VERSION ""

NS_ :

BS_:

BU_:

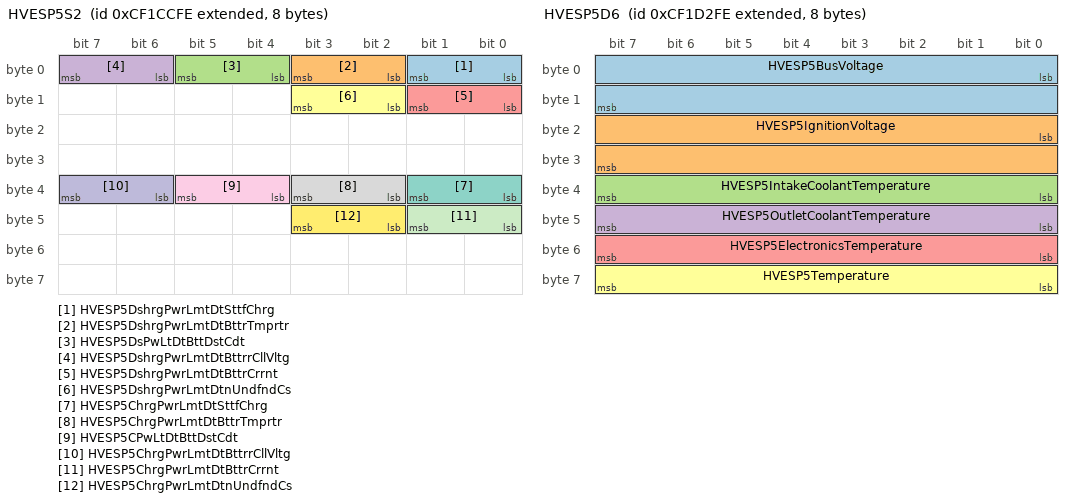
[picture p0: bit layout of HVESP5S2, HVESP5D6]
BO_ 2364656894 HVESP5S2: 8 Vector__XXX
 SG_ HVESP5DshrgPwrLmtDtSttfChrg : 0|2@1+ (1,0) [0|3] "" Vector__XXX
 SG_ HVESP5DshrgPwrLmtDtBttrTmprtr : 2|2@1+ (1,0) [0|3] "" Vector__XXX
 SG_ HVESP5DsPwLtDtBttDstCdt : 4|2@1+ (1,0) [0|3] "" Vector__XXX
 SG_ HVESP5DshrgPwrLmtDtBttrrCllVltg : 6|2@1+ (1,0) [0|3] "" Vector__XXX
 SG_ HVESP5DshrgPwrLmtDtBttrCrrnt : 8|2@1+ (1,0) [0|3] "" Vector__XXX
 SG_ HVESP5DshrgPwrLmtDtnUndfndCs : 10|2@1+ (1,0) [0|3] "" Vector__XXX
 SG_ HVESP5ChrgPwrLmtDtSttfChrg : 32|2@1+ (1,0) [0|3] "" Vector__XXX
 SG_ HVESP5ChrgPwrLmtDtBttrTmprtr : 34|2@1+ (1,0) [0|3] "" Vector__XXX
 SG_ HVESP5CPwLtDtBttDstCdt : 36|2@1+ (1,0) [0|3] "" Vector__XXX
 SG_ HVESP5ChrgPwrLmtDtBttrrCllVltg : 38|2@1+ (1,0) [0|3] "" Vector__XXX
 SG_ HVESP5ChrgPwrLmtDtBttrCrrnt : 40|2@1+ (1,0) [0|3] "" Vector__XXX
 SG_ HVESP5ChrgPwrLmtDtnUndfndCs : 42|2@1+ (1,0) [0|3] "" Vector__XXX

BO_ 2364657150 HVESP5D1: 8 Vector__XXX
 SG_ HVESP5AvailableDischargePower : 0|16@1+ (0.05,0) [0|3212.75] "kW" Vector__XXX
 SG_ HVESP5AvailableChargePower : 16|16@1+ (0.05,0) [0|3212.75] "kW" Vector__XXX
 SG_ HVESP5VoltageLevel : 32|16@1+ (0.05,0) [0|3212.75] "V" Vector__XXX
 SG_ HVESP5Current : 48|16@1+ (0.05,-1600) [-1600|1612.75] "A" Vector__XXX

BO_ 2364657406 HVESP5D2: 8 Vector__XXX
 SG_ HVESP5FastUpdateStateofCharge : 0|16@1+ (0.0015625,0) [0|100.3984375] "%" Vector__XXX
 SG_ HVESP5HighestCellVoltage : 16|16@1+ (0.001,0) [0|64.255] "V" Vector__XXX
 SG_ HVESP5LowestCellVoltage : 32|16@1+ (0.001,0) [0|64.255] "V" Vector__XXX
 SG_ HVESP5CllVltgDffrntlStts : 48|4@1+ (1,0) [0|15] "" Vector__XXX

BO_ 2364657662 HVESP5D3: 8 Vector__XXX
 SG_ HVESP5HighestCellTemperature : 0|16@1+ (0.03125,-273) [-273|1734.96875] "degC" Vector__XXX
 SG_ HVESP5LowestCellTemperature : 16|16@1+ (0.03125,-273) [-273|1734.96875] "degC" Vector__XXX
 SG_ HVESP5AverageCellTemperature : 32|16@1+ (0.03125,-273) [-273|1734.96875] "degC" Vector__XXX
 SG_ HVESP5CllTmprtrDffrntlStts : 48|2@1+ (1,0) [0|3] "" Vector__XXX

BO_ 2364657918 HVESP5D4: 8 Vector__XXX
 SG_ HVESP5DischargeCapacity : 0|16@1+ (0.01,0) [0|642.55] "Ah" Vector__XXX
 SG_ HVESP5ChargeCapacity : 16|16@1+ (0.01,0) [0|642.55] "Ah" Vector__XXX
 SG_ HVESP5CellBalancingCount : 32|16@1+ (1,0) [0|64255] "count" Vector__XXX

BO_ 2364658174 HVESP5D5: 8 Vector__XXX
 SG_ HVESP5DischargeCurrentLimit : 0|16@1+ (0.05,-1600) [-1600|1612.75] "A" Vector__XXX
 SG_ HVESP5ChargeCurrentLimit : 16|16@1+ (0.05,-1600) [-1600|1612.75] "A" Vector__XXX
 SG_ HVESP5LowestCellStateofCharge : 32|16@1+ (0.0015625,0) [0|100.3984375] "%" Vector__XXX
 SG_ HVESP5HighestCellStateofCharge : 48|16@1+ (0.0015625,0) [0|100.3984375] "%" Vector__XXX

BO_ 2364658430 HVESP5D6: 8 Vector__XXX
 SG_ HVESP5BusVoltage : 0|16@1+ (0.05,0) [0|3212.75] "V" Vector__XXX
 SG_ HVESP5IgnitionVoltage : 16|16@1+ (0.01,0) [0|642.55] "V" Vector__XXX
 SG_ HVESP5IntakeCoolantTemperature : 32|8@1+ (1,-40) [-40|210] "degC" Vector__XXX
 SG_ HVESP5OutletCoolantTemperature : 40|8@1+ (1,-40) [-40|210] "degC" Vector__XXX
 SG_ HVESP5ElectronicsTemperature : 48|8@1+ (1,-40) [-40|210] "degC" Vector__XXX
 SG_ HVESP5Temperature : 56|8@1+ (1,-40) [-40|210] "degC" Vector__XXX

BO_ 2364658686 HVESP5S1: 8 Vector__XXX
 SG_ HVESP5HghVltgBsPstvCnttrStt : 0|2@1+ (1,0) [0|3] "" Vector__XXX
 SG_ HVESP5HghVltgBsNgtvCnttrStt : 2|2@1+ (1,0) [0|3] "" Vector__XXX
 SG_ HVESP5HghVltgBsDsnntFrwrnng : 4|4@1+ (1,0) [0|15] "" Vector__XXX
 SG_ HVESP5HghVltgBsPrChrgRlStt : 8|2@1+ (1,0) [0|3] "" Vector__XXX
 SG_ HVESP5CntrfPkCnttrStt : 10|2@1+ (1,0) [0|3] "" Vector__XXX
 SG_ HVESP5HghVltgBsAtvIsltnTstStts : 12|4@1+ (1,0) [0|15] "" Vector__XXX
 SG_ HVESP5HghVltgBsPssvIsltnTstStts : 16|4@1+ (1,0) [0|15] "" Vector__XXX
 SG_ HVESP5HVILStatus : 20|2@1+ (1,0) [0|3] "" Vector__XXX
 SG_ HVESP5InertiaSwitchStatus : 22|2@1+ (1,0) [0|3] "" Vector__XXX
 SG_ HVESP5StateofChargeStatus : 24|4@1+ (1,0) [0|15] "" Vector__XXX
 SG_ HVESP5CellBalanceStatus : 28|2@1+ (1,0) [0|3] "" Vector__XXX
 SG_ HVESP5CellBalancingActive : 30|2@1+ (1,0) [0|3] "" Vector__XXX
 SG_ HVESP5InternalChargerStatus : 32|2@1+ (1,0) [0|3] "" Vector__XXX
 SG_ HVESP5HghVltgBsCnntnStts : 40|4@1+ (1,0) [0|15] "" Vector__XXX
 SG_ HVESP5OperationalStatus : 44|4@1+ (1,0) [0|15] "" Vector__XXX
 SG_ HVESP5Status1Counter : 52|4@1+ (1,0) [0|15] "" Vector__XXX
 SG_ HVESP5Status1CRC : 56|8@1+ (1,0) [0|255] "count" Vector__XXX

BO_ 2364658942 HVESP5D7: 8 Vector__XXX
 SG_ HVESP5DischargeEnergyCapacity : 0|24@1+ (0.001,0) [0|16449.535] "kWh" Vector__XXX
 SG_ HVESP5ChargeEnergyCapacity : 24|24@1+ (0.001,0) [0|16449.535] "kWh" Vector__XXX
 SG_ HVESP5MaximumChargeVoltageLimit : 48|16@1+ (0.05,0) [0|3212.75] "V" Vector__XXX

BO_ 2364659198 HVESP5MS1: 8 Vector__XXX
 SG_ HVESP5Module1OperationalStatus : 0|2@1+ (1,0) [0|3] "" Vector__XXX
 SG_ HVESP5Module2OperationalStatus : 2|2@1+ (1,0) [0|3] "" Vector__XXX
 SG_ HVESP5Module3OperationalStatus : 4|2@1+ (1,0) [0|3] "" Vector__XXX
 SG_ HVESP5Module4OperationalStatus : 6|2@1+ (1,0) [0|3] "" Vector__XXX
 SG_ HVESP5Module5OperationalStatus : 8|2@1+ (1,0) [0|3] "" Vector__XXX
 SG_ HVESP5Module6OperationalStatus : 10|2@1+ (1,0) [0|3] "" Vector__XXX
 SG_ HVESP5Module7OperationalStatus : 12|2@1+ (1,0) [0|3] "" Vector__XXX
 SG_ HVESP5Module8OperationalStatus : 14|2@1+ (1,0) [0|3] "" Vector__XXX
 SG_ HVESP5Module9OperationalStatus : 16|2@1+ (1,0) [0|3] "" Vector__XXX
 SG_ HVESP5Module10OperationalStatus : 18|2@1+ (1,0) [0|3] "" Vector__XXX
 SG_ HVESP5Module11OperationalStatus : 20|2@1+ (1,0) [0|3] "" Vector__XXX
 SG_ HVESP5Module12OperationalStatus : 22|2@1+ (1,0) [0|3] "" Vector__XXX
 SG_ HVESP5Module13OperationalStatus : 24|2@1+ (1,0) [0|3] "" Vector__XXX
 SG_ HVESP5Module14OperationalStatus : 26|2@1+ (1,0) [0|3] "" Vector__XXX
 SG_ HVESP5Module15OperationalStatus : 28|2@1+ (1,0) [0|3] "" Vector__XXX
 SG_ HVESP5Module16OperationalStatus : 30|2@1+ (1,0) [0|3] "" Vector__XXX
 SG_ HVESP5Module17OperationalStatus : 32|2@1+ (1,0) [0|3] "" Vector__XXX
 SG_ HVESP5Module18OperationalStatus : 34|2@1+ (1,0) [0|3] "" Vector__XXX
 SG_ HVESP5Module19OperationalStatus : 36|2@1+ (1,0) [0|3] "" Vector__XXX
 SG_ HVESP5Module20OperationalStatus : 38|2@1+ (1,0) [0|3] "" Vector__XXX
 SG_ HVESP5Module21OperationalStatus : 40|2@1+ (1,0) [0|3] "" Vector__XXX
 SG_ HVESP5Module22OperationalStatus : 42|2@1+ (1,0) [0|3] "" Vector__XXX
 SG_ HVESP5Module23OperationalStatus : 44|2@1+ (1,0) [0|3] "" Vector__XXX
 SG_ HVESP5Module24OperationalStatus : 46|2@1+ (1,0) [0|3] "" Vector__XXX
 SG_ HVESP5Module25OperationalStatus : 48|2@1+ (1,0) [0|3] "" Vector__XXX
 SG_ HVESP5Module26OperationalStatus : 50|2@1+ (1,0) [0|3] "" Vector__XXX
 SG_ HVESP5Module27OperationalStatus : 52|2@1+ (1,0) [0|3] "" Vector__XXX
 SG_ HVESP5Module28OperationalStatus : 54|2@1+ (1,0) [0|3] "" Vector__XXX
 SG_ HVESP5Module29OperationalStatus : 56|2@1+ (1,0) [0|3] "" Vector__XXX
 SG_ HVESP5Module30OperationalStatus : 58|2@1+ (1,0) [0|3] "" Vector__XXX
 SG_ HVESP5Module31OperationalStatus : 60|2@1+ (1,0) [0|3] "" Vector__XXX
 SG_ HVESP5Module32OperationalStatus : 62|2@1+ (1,0) [0|3] "" Vector__XXX

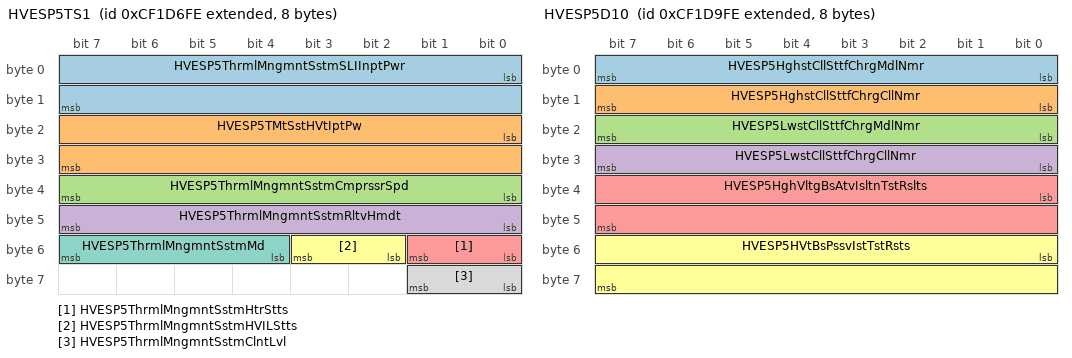
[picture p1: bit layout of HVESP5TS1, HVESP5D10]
BO_ 2364659454 HVESP5TS1: 8 Vector__XXX
 SG_ HVESP5ThrmlMngmntSstmSLIInptPwr : 0|16@1+ (0.5,0) [0|32127.5] "W" Vector__XXX
 SG_ HVESP5TMtSstHVtIptPw : 16|16@1+ (0.5,0) [0|32127.5] "W" Vector__XXX
 SG_ HVESP5ThrmlMngmntSstmCmprssrSpd : 32|8@1+ (32,0) [0|8000] "rpm" Vector__XXX
 SG_ HVESP5ThrmlMngmntSstmRltvHmdt : 40|8@1+ (0.4,0) [0|100] "%" Vector__XXX
 SG_ HVESP5ThrmlMngmntSstmHtrStts : 48|2@1+ (1,0) [0|3] "" Vector__XXX
 SG_ HVESP5ThrmlMngmntSstmHVILStts : 50|2@1+ (1,0) [0|3] "" Vector__XXX
 SG_ HVESP5ThrmlMngmntSstmMd : 52|4@1+ (1,0) [0|15] "" Vector__XXX
 SG_ HVESP5ThrmlMngmntSstmClntLvl : 56|2@1+ (1,0) [0|3] "" Vector__XXX

BO_ 2364659710 HVESP5D8: 8 Vector__XXX
 SG_ HVESP5HghstCllVltgMdlNmr : 0|8@1+ (1,0) [0|250] "count" Vector__XXX
 SG_ HVESP5HghstCllVltgCllNmr : 8|8@1+ (1,0) [0|250] "count" Vector__XXX
 SG_ HVESP5LwstCllVltgMdlNmr : 16|8@1+ (1,0) [0|250] "count" Vector__XXX
 SG_ HVESP5LwstCllVltgCllNmr : 24|8@1+ (1,0) [0|250] "count" Vector__XXX
 SG_ HVESP5AverageCellVoltage : 32|16@1+ (0.001,0) [0|64.255] "V" Vector__XXX

BO_ 2364659966 HVESP5D9: 8 Vector__XXX
 SG_ HVESP5HghstCllTmprtrMdlNmr : 0|8@1+ (1,0) [0|250] "count" Vector__XXX
 SG_ HVESP5HghstCllTmprtrCllNmr : 8|8@1+ (1,0) [0|250] "count" Vector__XXX
 SG_ HVESP5LwstCllTmprtrMdlNmr : 16|8@1+ (1,0) [0|250] "count" Vector__XXX
 SG_ HVESP5LwstCllTmprtrCllNmr : 24|8@1+ (1,0) [0|250] "count" Vector__XXX

BO_ 2364660222 HVESP5D10: 8 Vector__XXX
 SG_ HVESP5HghstCllSttfChrgMdlNmr : 0|8@1+ (1,0) [0|250] "count" Vector__XXX
 SG_ HVESP5HghstCllSttfChrgCllNmr : 8|8@1+ (1,0) [0|250] "count" Vector__XXX
 SG_ HVESP5LwstCllSttfChrgMdlNmr : 16|8@1+ (1,0) [0|250] "count" Vector__XXX
 SG_ HVESP5LwstCllSttfChrgCllNmr : 24|8@1+ (1,0) [0|250] "count" Vector__XXX
 SG_ HVESP5HghVltgBsAtvIsltnTstRslts : 32|16@1+ (0.1,0) [0|6425.5] "ohm/V" Vector__XXX
 SG_ HVESP5HVtBsPssvIstTstRsts : 48|16@1+ (0.1,0) [0|6425.5] "ohm/V" Vector__XXX

BO_ 2364660478 HVESP5D11: 8 Vector__XXX
 SG_ HVESP5BsVltgNgtvtChsssGrndVltg : 0|16@1+ (0.05,0) [0|3212.75] "V" Vector__XXX
 SG_ HVESP5VltgLvlNgtvtChsssGrndVltg : 16|16@1+ (0.05,0) [0|3212.75] "V" Vector__XXX
 SG_ HVESP5ActualChargeRate : 32|16@1+ (0.05,0) [0|3212.75] "kW" Vector__XXX

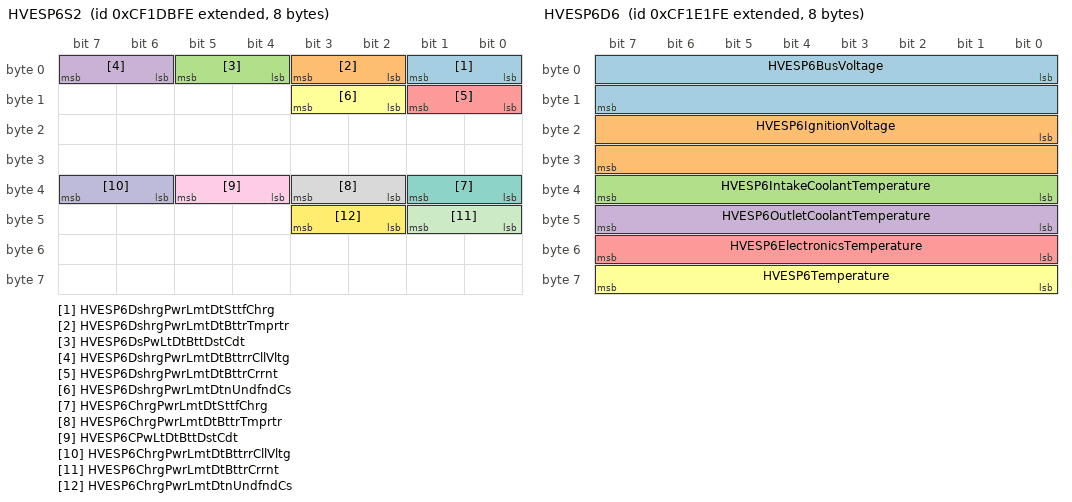
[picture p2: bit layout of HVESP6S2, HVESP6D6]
BO_ 2364660734 HVESP6S2: 8 Vector__XXX
 SG_ HVESP6DshrgPwrLmtDtSttfChrg : 0|2@1+ (1,0) [0|3] "" Vector__XXX
 SG_ HVESP6DshrgPwrLmtDtBttrTmprtr : 2|2@1+ (1,0) [0|3] "" Vector__XXX
 SG_ HVESP6DsPwLtDtBttDstCdt : 4|2@1+ (1,0) [0|3] "" Vector__XXX
 SG_ HVESP6DshrgPwrLmtDtBttrrCllVltg : 6|2@1+ (1,0) [0|3] "" Vector__XXX
 SG_ HVESP6DshrgPwrLmtDtBttrCrrnt : 8|2@1+ (1,0) [0|3] "" Vector__XXX
 SG_ HVESP6DshrgPwrLmtDtnUndfndCs : 10|2@1+ (1,0) [0|3] "" Vector__XXX
 SG_ HVESP6ChrgPwrLmtDtSttfChrg : 32|2@1+ (1,0) [0|3] "" Vector__XXX
 SG_ HVESP6ChrgPwrLmtDtBttrTmprtr : 34|2@1+ (1,0) [0|3] "" Vector__XXX
 SG_ HVESP6CPwLtDtBttDstCdt : 36|2@1+ (1,0) [0|3] "" Vector__XXX
 SG_ HVESP6ChrgPwrLmtDtBttrrCllVltg : 38|2@1+ (1,0) [0|3] "" Vector__XXX
 SG_ HVESP6ChrgPwrLmtDtBttrCrrnt : 40|2@1+ (1,0) [0|3] "" Vector__XXX
 SG_ HVESP6ChrgPwrLmtDtnUndfndCs : 42|2@1+ (1,0) [0|3] "" Vector__XXX

BO_ 2364660990 HVESP6D1: 8 Vector__XXX
 SG_ HVESP6AvailableDischargePower : 0|16@1+ (0.05,0) [0|3212.75] "kW" Vector__XXX
 SG_ HVESP6AvailableChargePower : 16|16@1+ (0.05,0) [0|3212.75] "kW" Vector__XXX
 SG_ HVESP6VoltageLevel : 32|16@1+ (0.05,0) [0|3212.75] "V" Vector__XXX
 SG_ HVESP6Current : 48|16@1+ (0.05,-1600) [-1600|1612.75] "A" Vector__XXX

BO_ 2364661246 HVESP6D2: 8 Vector__XXX
 SG_ HVESP6FastUpdateStateofCharge : 0|16@1+ (0.0015625,0) [0|100.3984375] "%" Vector__XXX
 SG_ HVESP6HighestCellVoltage : 16|16@1+ (0.001,0) [0|64.255] "V" Vector__XXX
 SG_ HVESP6LowestCellVoltage : 32|16@1+ (0.001,0) [0|64.255] "V" Vector__XXX
 SG_ HVESP6CllVltgDffrntlStts : 48|4@1+ (1,0) [0|15] "" Vector__XXX

BO_ 2364661502 HVESP6D3: 8 Vector__XXX
 SG_ HVESP6HighestCellTemperature : 0|16@1+ (0.03125,-273) [-273|1734.96875] "degC" Vector__XXX
 SG_ HVESP6LowestCellTemperature : 16|16@1+ (0.03125,-273) [-273|1734.96875] "degC" Vector__XXX
 SG_ HVESP6AverageCellTemperature : 32|16@1+ (0.03125,-273) [-273|1734.96875] "degC" Vector__XXX
 SG_ HVESP6CllTmprtrDffrntlStts : 48|2@1+ (1,0) [0|3] "" Vector__XXX

BO_ 2364661758 HVESP6D4: 8 Vector__XXX
 SG_ HVESP6DischargeCapacity : 0|16@1+ (0.01,0) [0|642.55] "Ah" Vector__XXX
 SG_ HVESP6ChargeCapacity : 16|16@1+ (0.01,0) [0|642.55] "Ah" Vector__XXX
 SG_ HVESP6CellBalancingCount : 32|16@1+ (1,0) [0|64255] "count" Vector__XXX

BO_ 2364662014 HVESP6D5: 8 Vector__XXX
 SG_ HVESP6DischargeCurrentLimit : 0|16@1+ (0.05,-1600) [-1600|1612.75] "A" Vector__XXX
 SG_ HVESP6ChargeCurrentLimit : 16|16@1+ (0.05,-1600) [-1600|1612.75] "A" Vector__XXX
 SG_ HVESP6LowestCellStateofCharge : 32|16@1+ (0.0015625,0) [0|100.3984375] "%" Vector__XXX
 SG_ HVESP6HighestCellStateofCharge : 48|16@1+ (0.0015625,0) [0|100.3984375] "%" Vector__XXX

BO_ 2364662270 HVESP6D6: 8 Vector__XXX
 SG_ HVESP6BusVoltage : 0|16@1+ (0.05,0) [0|3212.75] "V" Vector__XXX
 SG_ HVESP6IgnitionVoltage : 16|16@1+ (0.01,0) [0|642.55] "V" Vector__XXX
 SG_ HVESP6IntakeCoolantTemperature : 32|8@1+ (1,-40) [-40|210] "degC" Vector__XXX
 SG_ HVESP6OutletCoolantTemperature : 40|8@1+ (1,-40) [-40|210] "degC" Vector__XXX
 SG_ HVESP6ElectronicsTemperature : 48|8@1+ (1,-40) [-40|210] "degC" Vector__XXX
 SG_ HVESP6Temperature : 56|8@1+ (1,-40) [-40|210] "degC" Vector__XXX

BO_ 2364662526 HVESP6S1: 8 Vector__XXX
 SG_ HVESP6HghVltgBsPstvCnttrStt : 0|2@1+ (1,0) [0|3] "" Vector__XXX
 SG_ HVESP6HghVltgBsNgtvCnttrStt : 2|2@1+ (1,0) [0|3] "" Vector__XXX
 SG_ HVESP6HghVltgBsDsnntFrwrnng : 4|4@1+ (1,0) [0|15] "" Vector__XXX
 SG_ HVESP6HghVltgBsPrChrgRlStt : 8|2@1+ (1,0) [0|3] "" Vector__XXX
 SG_ HVESP6CntrfPkCnttrStt : 10|2@1+ (1,0) [0|3] "" Vector__XXX
 SG_ HVESP6HghVltgBsAtvIsltnTstStts : 12|4@1+ (1,0) [0|15] "" Vector__XXX
 SG_ HVESP6HghVltgBsPssvIsltnTstStts : 16|4@1+ (1,0) [0|15] "" Vector__XXX
 SG_ HVESP6HVILStatus : 20|2@1+ (1,0) [0|3] "" Vector__XXX
 SG_ HVESP6InertiaSwitchStatus : 22|2@1+ (1,0) [0|3] "" Vector__XXX
 SG_ HVESP6StateofChargeStatus : 24|4@1+ (1,0) [0|15] "" Vector__XXX
 SG_ HVESP6CellBalanceStatus : 28|2@1+ (1,0) [0|3] "" Vector__XXX
 SG_ HVESP6CellBalancingActive : 30|2@1+ (1,0) [0|3] "" Vector__XXX
 SG_ HVESP6InternalChargerStatus : 32|2@1+ (1,0) [0|3] "" Vector__XXX
 SG_ HVESP6HghVltgBsCnntnStts : 40|4@1+ (1,0) [0|15] "" Vector__XXX
 SG_ HVESP6OperationalStatus : 44|4@1+ (1,0) [0|15] "" Vector__XXX
 SG_ HVESP6Status1Counter : 52|4@1+ (1,0) [0|15] "" Vector__XXX
 SG_ HVESP6Status1CRC : 56|8@1+ (1,0) [0|255] "count" Vector__XXX

BO_ 2364662782 HVESP6D7: 8 Vector__XXX
 SG_ HVESP6DischargeEnergyCapacity : 0|24@1+ (0.001,0) [0|16449.535] "kWh" Vector__XXX
 SG_ HVESP6ChargeEnergyCapacity : 24|24@1+ (0.001,0) [0|16449.535] "kWh" Vector__XXX
 SG_ HVESP6MaximumChargeVoltageLimit : 48|16@1+ (0.05,0) [0|3212.75] "V" Vector__XXX

BO_ 2364663038 HVESP6MS1: 8 Vector__XXX
 SG_ HVESP6Module1OperationalStatus : 0|2@1+ (1,0) [0|3] "" Vector__XXX
 SG_ HVESP6Module2OperationalStatus : 2|2@1+ (1,0) [0|3] "" Vector__XXX
 SG_ HVESP6Module3OperationalStatus : 4|2@1+ (1,0) [0|3] "" Vector__XXX
 SG_ HVESP6Module4OperationalStatus : 6|2@1+ (1,0) [0|3] "" Vector__XXX
 SG_ HVESP6Module5OperationalStatus : 8|2@1+ (1,0) [0|3] "" Vector__XXX
 SG_ HVESP6Module6OperationalStatus : 10|2@1+ (1,0) [0|3] "" Vector__XXX
 SG_ HVESP6Module7OperationalStatus : 12|2@1+ (1,0) [0|3] "" Vector__XXX
 SG_ HVESP6Module8OperationalStatus : 14|2@1+ (1,0) [0|3] "" Vector__XXX
 SG_ HVESP6Module9OperationalStatus : 16|2@1+ (1,0) [0|3] "" Vector__XXX
 SG_ HVESP6Module10OperationalStatus : 18|2@1+ (1,0) [0|3] "" Vector__XXX
 SG_ HVESP6Module11OperationalStatus : 20|2@1+ (1,0) [0|3] "" Vector__XXX
 SG_ HVESP6Module12OperationalStatus : 22|2@1+ (1,0) [0|3] "" Vector__XXX
 SG_ HVESP6Module13OperationalStatus : 24|2@1+ (1,0) [0|3] "" Vector__XXX
 SG_ HVESP6Module14OperationalStatus : 26|2@1+ (1,0) [0|3] "" Vector__XXX
 SG_ HVESP6Module15OperationalStatus : 28|2@1+ (1,0) [0|3] "" Vector__XXX
 SG_ HVESP6Module16OperationalStatus : 30|2@1+ (1,0) [0|3] "" Vector__XXX
 SG_ HVESP6Module17OperationalStatus : 32|2@1+ (1,0) [0|3] "" Vector__XXX
 SG_ HVESP6Module18OperationalStatus : 34|2@1+ (1,0) [0|3] "" Vector__XXX
 SG_ HVESP6Module19OperationalStatus : 36|2@1+ (1,0) [0|3] "" Vector__XXX
 SG_ HVESP6Module20OperationalStatus : 38|2@1+ (1,0) [0|3] "" Vector__XXX
 SG_ HVESP6Module21OperationalStatus : 40|2@1+ (1,0) [0|3] "" Vector__XXX
 SG_ HVESP6Module22OperationalStatus : 42|2@1+ (1,0) [0|3] "" Vector__XXX
 SG_ HVESP6Module23OperationalStatus : 44|2@1+ (1,0) [0|3] "" Vector__XXX
 SG_ HVESP6Module24OperationalStatus : 46|2@1+ (1,0) [0|3] "" Vector__XXX
 SG_ HVESP6Module25OperationalStatus : 48|2@1+ (1,0) [0|3] "" Vector__XXX
 SG_ HVESP6Module26OperationalStatus : 50|2@1+ (1,0) [0|3] "" Vector__XXX
 SG_ HVESP6Module27OperationalStatus : 52|2@1+ (1,0) [0|3] "" Vector__XXX
 SG_ HVESP6Module28OperationalStatus : 54|2@1+ (1,0) [0|3] "" Vector__XXX
 SG_ HVESP6Module29OperationalStatus : 56|2@1+ (1,0) [0|3] "" Vector__XXX
 SG_ HVESP6Module30OperationalStatus : 58|2@1+ (1,0) [0|3] "" Vector__XXX
 SG_ HVESP6Module31OperationalStatus : 60|2@1+ (1,0) [0|3] "" Vector__XXX
 SG_ HVESP6Module32OperationalStatus : 62|2@1+ (1,0) [0|3] "" Vector__XXX

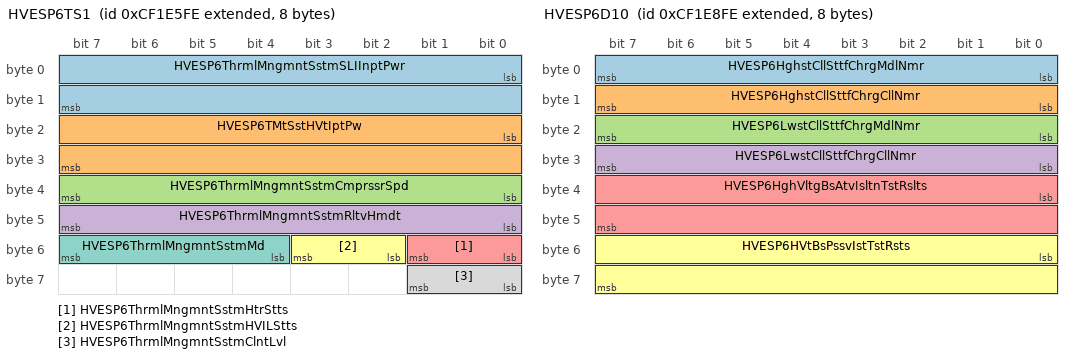
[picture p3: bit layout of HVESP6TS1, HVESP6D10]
BO_ 2364663294 HVESP6TS1: 8 Vector__XXX
 SG_ HVESP6ThrmlMngmntSstmSLIInptPwr : 0|16@1+ (0.5,0) [0|32127.5] "W" Vector__XXX
 SG_ HVESP6TMtSstHVtIptPw : 16|16@1+ (0.5,0) [0|32127.5] "W" Vector__XXX
 SG_ HVESP6ThrmlMngmntSstmCmprssrSpd : 32|8@1+ (32,0) [0|8000] "rpm" Vector__XXX
 SG_ HVESP6ThrmlMngmntSstmRltvHmdt : 40|8@1+ (0.4,0) [0|100] "%" Vector__XXX
 SG_ HVESP6ThrmlMngmntSstmHtrStts : 48|2@1+ (1,0) [0|3] "" Vector__XXX
 SG_ HVESP6ThrmlMngmntSstmHVILStts : 50|2@1+ (1,0) [0|3] "" Vector__XXX
 SG_ HVESP6ThrmlMngmntSstmMd : 52|4@1+ (1,0) [0|15] "" Vector__XXX
 SG_ HVESP6ThrmlMngmntSstmClntLvl : 56|2@1+ (1,0) [0|3] "" Vector__XXX

BO_ 2364663550 HVESP6D8: 8 Vector__XXX
 SG_ HVESP6HghstCllVltgMdlNmr : 0|8@1+ (1,0) [0|250] "count" Vector__XXX
 SG_ HVESP6HghstCllVltgCllNmr : 8|8@1+ (1,0) [0|250] "count" Vector__XXX
 SG_ HVESP6LwstCllVltgMdlNmr : 16|8@1+ (1,0) [0|250] "count" Vector__XXX
 SG_ HVESP6LwstCllVltgCllNmr : 24|8@1+ (1,0) [0|250] "count" Vector__XXX
 SG_ HVESP6AverageCellVoltage : 32|16@1+ (0.001,0) [0|64.255] "V" Vector__XXX

BO_ 2364663806 HVESP6D9: 8 Vector__XXX
 SG_ HVESP6HghstCllTmprtrMdlNmr : 0|8@1+ (1,0) [0|250] "count" Vector__XXX
 SG_ HVESP6HghstCllTmprtrCllNmr : 8|8@1+ (1,0) [0|250] "count" Vector__XXX
 SG_ HVESP6LwstCllTmprtrMdlNmr : 16|8@1+ (1,0) [0|250] "count" Vector__XXX
 SG_ HVESP6LwstCllTmprtrCllNmr : 24|8@1+ (1,0) [0|250] "count" Vector__XXX

BO_ 2364664062 HVESP6D10: 8 Vector__XXX
 SG_ HVESP6HghstCllSttfChrgMdlNmr : 0|8@1+ (1,0) [0|250] "count" Vector__XXX
 SG_ HVESP6HghstCllSttfChrgCllNmr : 8|8@1+ (1,0) [0|250] "count" Vector__XXX
 SG_ HVESP6LwstCllSttfChrgMdlNmr : 16|8@1+ (1,0) [0|250] "count" Vector__XXX
 SG_ HVESP6LwstCllSttfChrgCllNmr : 24|8@1+ (1,0) [0|250] "count" Vector__XXX
 SG_ HVESP6HghVltgBsAtvIsltnTstRslts : 32|16@1+ (0.1,0) [0|6425.5] "ohm/V" Vector__XXX
 SG_ HVESP6HVtBsPssvIstTstRsts : 48|16@1+ (0.1,0) [0|6425.5] "ohm/V" Vector__XXX

BO_ 2364664318 HVESP6D11: 8 Vector__XXX
 SG_ HVESP6BsVltgNgtvtChsssGrndVltg : 0|16@1+ (0.05,0) [0|3212.75] "V" Vector__XXX
 SG_ HVESP6VltgLvlNgtvtChsssGrndVltg : 16|16@1+ (0.05,0) [0|3212.75] "V" Vector__XXX
 SG_ HVESP6ActualChargeRate : 32|16@1+ (0.05,0) [0|3212.75] "kW" Vector__XXX

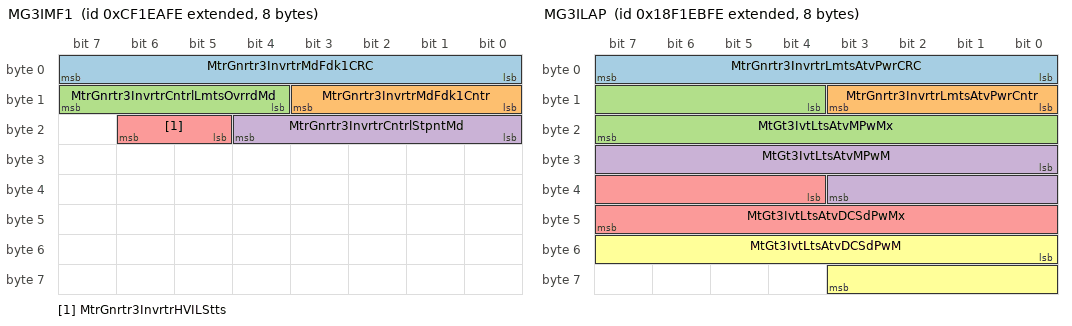
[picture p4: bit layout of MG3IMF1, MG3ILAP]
BO_ 2364664574 MG3IMF1: 8 Vector__XXX
 SG_ MtrGnrtr3InvrtrMdFdk1CRC : 0|8@1+ (1,0) [0|255] "count" Vector__XXX
 SG_ MtrGnrtr3InvrtrMdFdk1Cntr : 8|4@1+ (1,0) [0|15] "" Vector__XXX
 SG_ MtrGnrtr3InvrtrCntrlLmtsOvrrdMd : 12|4@1+ (1,0) [0|15] "" Vector__XXX
 SG_ MtrGnrtr3InvrtrCntrlStpntMd : 16|5@1+ (1,0) [0|31] "" Vector__XXX
 SG_ MtrGnrtr3InvrtrHVILStts : 21|2@1+ (1,0) [0|3] "" Vector__XXX

BO_ 2565991422 MG3ILAP: 8 Vector__XXX
 SG_ MtrGnrtr3InvrtrLmtsAtvPwrCRC : 0|8@1+ (1,0) [0|255] "count" Vector__XXX
 SG_ MtrGnrtr3InvrtrLmtsAtvPwrCntr : 8|4@1+ (1,0) [0|15] "" Vector__XXX
 SG_ MtGt3IvtLtsAtvMPwMx : 12|12@1+ (42370,-125) [-125|125.9375] "%" Vector__XXX
 SG_ MtGt3IvtLtsAtvMPwM : 24|12@1+ (42370,-125) [-125|125.9375] "%" Vector__XXX
 SG_ MtGt3IvtLtsAtvDCSdPwMx : 36|12@1+ (42370,-125) [-125|125.9375] "%" Vector__XXX
 SG_ MtGt3IvtLtsAtvDCSdPwM : 48|12@1+ (42370,-125) [-125|125.9375] "%" Vector__XXX

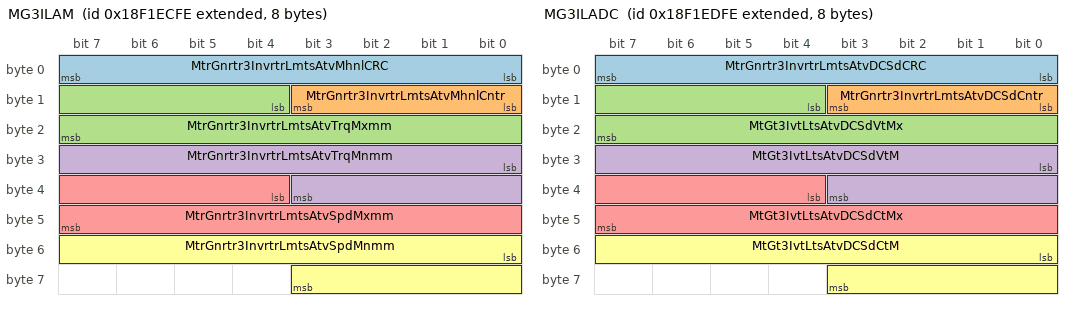
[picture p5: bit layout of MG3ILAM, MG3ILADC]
BO_ 2565991678 MG3ILAM: 8 Vector__XXX
 SG_ MtrGnrtr3InvrtrLmtsAtvMhnlCRC : 0|8@1+ (1,0) [0|255] "count" Vector__XXX
 SG_ MtrGnrtr3InvrtrLmtsAtvMhnlCntr : 8|4@1+ (1,0) [0|15] "" Vector__XXX
 SG_ MtrGnrtr3InvrtrLmtsAtvTrqMxmm : 12|12@1+ (42370,-125) [-125|125.9375] "%" Vector__XXX
 SG_ MtrGnrtr3InvrtrLmtsAtvTrqMnmm : 24|12@1+ (42370,-125) [-125|125.9375] "%" Vector__XXX
 SG_ MtrGnrtr3InvrtrLmtsAtvSpdMxmm : 36|12@1+ (42370,-125) [-125|125.9375] "%" Vector__XXX
 SG_ MtrGnrtr3InvrtrLmtsAtvSpdMnmm : 48|12@1+ (42370,-125) [-125|125.9375] "%" Vector__XXX

BO_ 2565991934 MG3ILADC: 8 Vector__XXX
 SG_ MtrGnrtr3InvrtrLmtsAtvDCSdCRC : 0|8@1+ (1,0) [0|255] "count" Vector__XXX
 SG_ MtrGnrtr3InvrtrLmtsAtvDCSdCntr : 8|4@1+ (1,0) [0|15] "" Vector__XXX
 SG_ MtGt3IvtLtsAtvDCSdVtMx : 12|12@1+ (42370,-125) [-125|125.9375] "%" Vector__XXX
 SG_ MtGt3IvtLtsAtvDCSdVtM : 24|12@1+ (42370,-125) [-125|125.9375] "%" Vector__XXX
 SG_ MtGt3IvtLtsAtvDCSdCtMx : 36|12@1+ (42370,-125) [-125|125.9375] "%" Vector__XXX
 SG_ MtGt3IvtLtsAtvDCSdCtM : 48|12@1+ (42370,-125) [-125|125.9375] "%" Vector__XXX

BO_ 2565992190 MG3ILV: 8 Vector__XXX
 SG_ MtrGnrtr3InvrtrSwthdIgntnVltg : 0|16@1+ (0.05,0) [0|3212.75] "V" Vector__XXX
 SG_ MtrGnrtr3InvrtrUnswthdSLIVltg : 16|16@1+ (0.05,0) [0|3212.75] "V" Vector__XXX

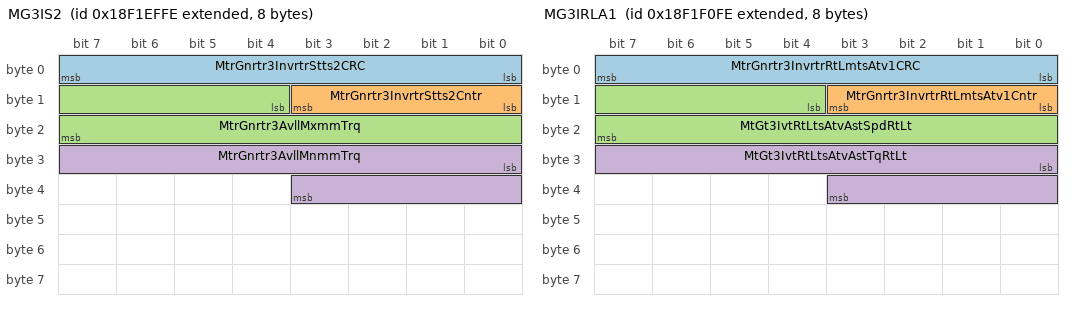
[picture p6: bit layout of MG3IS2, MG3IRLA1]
BO_ 2565992446 MG3IS2: 8 Vector__XXX
 SG_ MtrGnrtr3InvrtrStts2CRC : 0|8@1+ (1,0) [0|255] "count" Vector__XXX
 SG_ MtrGnrtr3InvrtrStts2Cntr : 8|4@1+ (1,0) [0|15] "" Vector__XXX
 SG_ MtrGnrtr3AvllMxmmTrq : 12|12@1+ (42370,-125) [-125|125.9375] "%" Vector__XXX
 SG_ MtrGnrtr3AvllMnmmTrq : 24|12@1+ (42370,-125) [-125|125.9375] "%" Vector__XXX

BO_ 2565992702 MG3IRLA1: 8 Vector__XXX
 SG_ MtrGnrtr3InvrtrRtLmtsAtv1CRC : 0|8@1+ (1,0) [0|255] "count" Vector__XXX
 SG_ MtrGnrtr3InvrtrRtLmtsAtv1Cntr : 8|4@1+ (1,0) [0|15] "" Vector__XXX
 SG_ MtGt3IvtRtLtsAtvAstSpdRtLt : 12|12@1+ (0.25,0) [0|1003.75] "%/s" Vector__XXX
 SG_ MtGt3IvtRtLtsAtvAstTqRtLt : 24|12@1+ (2,0) [0|8030] "%/s" Vector__XXX

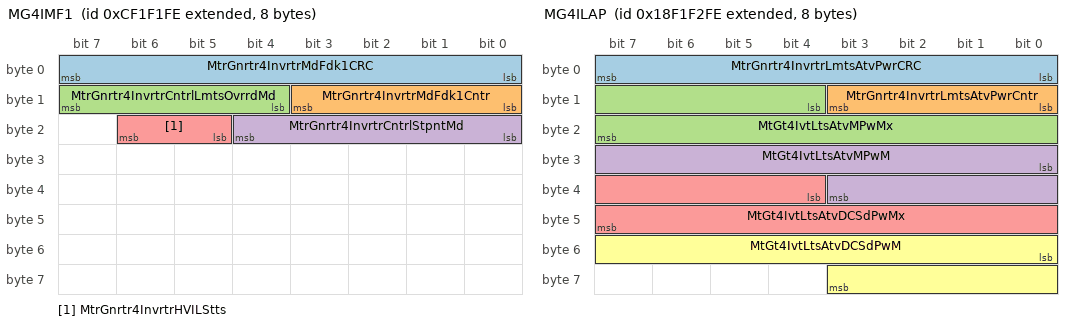
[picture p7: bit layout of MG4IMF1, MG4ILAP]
BO_ 2364666366 MG4IMF1: 8 Vector__XXX
 SG_ MtrGnrtr4InvrtrMdFdk1CRC : 0|8@1+ (1,0) [0|255] "count" Vector__XXX
 SG_ MtrGnrtr4InvrtrMdFdk1Cntr : 8|4@1+ (1,0) [0|15] "" Vector__XXX
 SG_ MtrGnrtr4InvrtrCntrlLmtsOvrrdMd : 12|4@1+ (1,0) [0|15] "" Vector__XXX
 SG_ MtrGnrtr4InvrtrCntrlStpntMd : 16|5@1+ (1,0) [0|31] "" Vector__XXX
 SG_ MtrGnrtr4InvrtrHVILStts : 21|2@1+ (1,0) [0|3] "" Vector__XXX

BO_ 2565993214 MG4ILAP: 8 Vector__XXX
 SG_ MtrGnrtr4InvrtrLmtsAtvPwrCRC : 0|8@1+ (1,0) [0|255] "count" Vector__XXX
 SG_ MtrGnrtr4InvrtrLmtsAtvPwrCntr : 8|4@1+ (1,0) [0|15] "" Vector__XXX
 SG_ MtGt4IvtLtsAtvMPwMx : 12|12@1+ (42370,-125) [-125|125.9375] "%" Vector__XXX
 SG_ MtGt4IvtLtsAtvMPwM : 24|12@1+ (42370,-125) [-125|125.9375] "%" Vector__XXX
 SG_ MtGt4IvtLtsAtvDCSdPwMx : 36|12@1+ (42370,-125) [-125|125.9375] "%" Vector__XXX
 SG_ MtGt4IvtLtsAtvDCSdPwM : 48|12@1+ (42370,-125) [-125|125.9375] "%" Vector__XXX

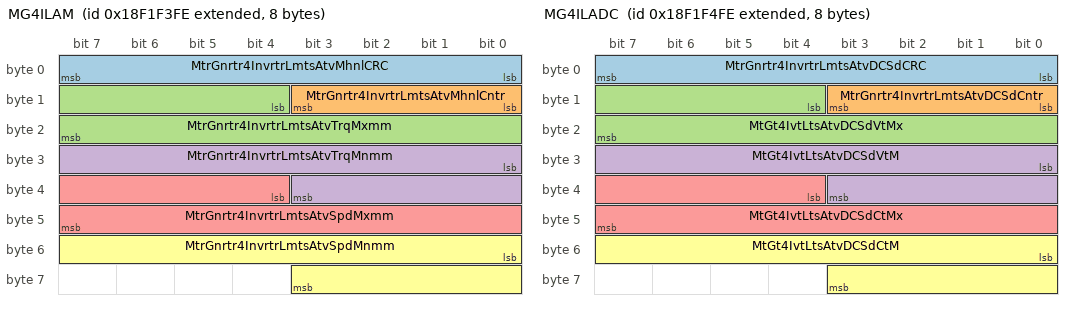
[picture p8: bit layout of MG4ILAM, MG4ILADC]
BO_ 2565993470 MG4ILAM: 8 Vector__XXX
 SG_ MtrGnrtr4InvrtrLmtsAtvMhnlCRC : 0|8@1+ (1,0) [0|255] "count" Vector__XXX
 SG_ MtrGnrtr4InvrtrLmtsAtvMhnlCntr : 8|4@1+ (1,0) [0|15] "" Vector__XXX
 SG_ MtrGnrtr4InvrtrLmtsAtvTrqMxmm : 12|12@1+ (42370,-125) [-125|125.9375] "%" Vector__XXX
 SG_ MtrGnrtr4InvrtrLmtsAtvTrqMnmm : 24|12@1+ (42370,-125) [-125|125.9375] "%" Vector__XXX
 SG_ MtrGnrtr4InvrtrLmtsAtvSpdMxmm : 36|12@1+ (42370,-125) [-125|125.9375] "%" Vector__XXX
 SG_ MtrGnrtr4InvrtrLmtsAtvSpdMnmm : 48|12@1+ (42370,-125) [-125|125.9375] "%" Vector__XXX

BO_ 2565993726 MG4ILADC: 8 Vector__XXX
 SG_ MtrGnrtr4InvrtrLmtsAtvDCSdCRC : 0|8@1+ (1,0) [0|255] "count" Vector__XXX
 SG_ MtrGnrtr4InvrtrLmtsAtvDCSdCntr : 8|4@1+ (1,0) [0|15] "" Vector__XXX
 SG_ MtGt4IvtLtsAtvDCSdVtMx : 12|12@1+ (42370,-125) [-125|125.9375] "%" Vector__XXX
 SG_ MtGt4IvtLtsAtvDCSdVtM : 24|12@1+ (42370,-125) [-125|125.9375] "%" Vector__XXX
 SG_ MtGt4IvtLtsAtvDCSdCtMx : 36|12@1+ (42370,-125) [-125|125.9375] "%" Vector__XXX
 SG_ MtGt4IvtLtsAtvDCSdCtM : 48|12@1+ (42370,-125) [-125|125.9375] "%" Vector__XXX

BO_ 2565993982 MG4ILV: 8 Vector__XXX
 SG_ MtrGnrtr4InvrtrSwthdIgntnVltg : 0|16@1+ (0.05,0) [0|3212.75] "V" Vector__XXX
 SG_ MtrGnrtr4InvrtrUnswthdSLIVltg : 16|16@1+ (0.05,0) [0|3212.75] "V" Vector__XXX

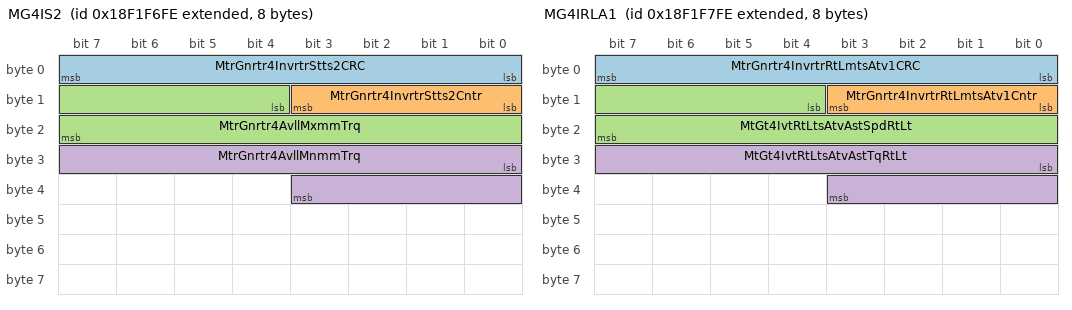
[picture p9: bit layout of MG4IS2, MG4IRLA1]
BO_ 2565994238 MG4IS2: 8 Vector__XXX
 SG_ MtrGnrtr4InvrtrStts2CRC : 0|8@1+ (1,0) [0|255] "count" Vector__XXX
 SG_ MtrGnrtr4InvrtrStts2Cntr : 8|4@1+ (1,0) [0|15] "" Vector__XXX
 SG_ MtrGnrtr4AvllMxmmTrq : 12|12@1+ (42370,-125) [-125|125.9375] "%" Vector__XXX
 SG_ MtrGnrtr4AvllMnmmTrq : 24|12@1+ (42370,-125) [-125|125.9375] "%" Vector__XXX

BO_ 2565994494 MG4IRLA1: 8 Vector__XXX
 SG_ MtrGnrtr4InvrtrRtLmtsAtv1CRC : 0|8@1+ (1,0) [0|255] "count" Vector__XXX
 SG_ MtrGnrtr4InvrtrRtLmtsAtv1Cntr : 8|4@1+ (1,0) [0|15] "" Vector__XXX
 SG_ MtGt4IvtRtLtsAtvAstSpdRtLt : 12|12@1+ (0.25,0) [0|1003.75] "%/s" Vector__XXX
 SG_ MtGt4IvtRtLtsAtvAstTqRtLt : 24|12@1+ (2,0) [0|8030] "%/s" Vector__XXX

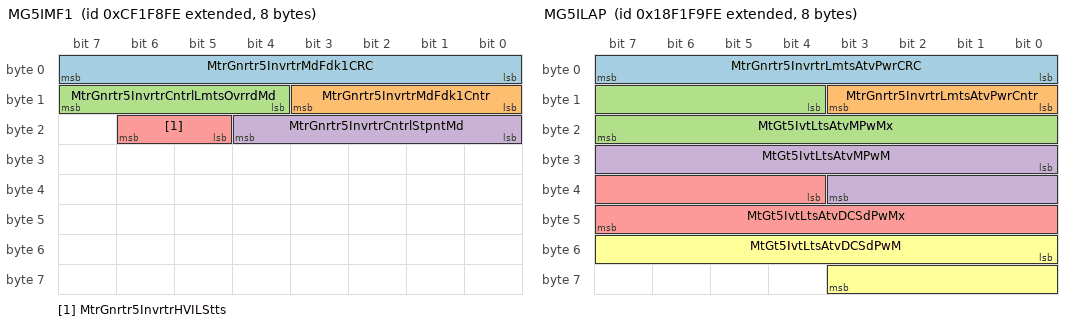
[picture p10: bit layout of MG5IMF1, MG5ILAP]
BO_ 2364668158 MG5IMF1: 8 Vector__XXX
 SG_ MtrGnrtr5InvrtrMdFdk1CRC : 0|8@1+ (1,0) [0|255] "count" Vector__XXX
 SG_ MtrGnrtr5InvrtrMdFdk1Cntr : 8|4@1+ (1,0) [0|15] "" Vector__XXX
 SG_ MtrGnrtr5InvrtrCntrlLmtsOvrrdMd : 12|4@1+ (1,0) [0|15] "" Vector__XXX
 SG_ MtrGnrtr5InvrtrCntrlStpntMd : 16|5@1+ (1,0) [0|31] "" Vector__XXX
 SG_ MtrGnrtr5InvrtrHVILStts : 21|2@1+ (1,0) [0|3] "" Vector__XXX

BO_ 2565995006 MG5ILAP: 8 Vector__XXX
 SG_ MtrGnrtr5InvrtrLmtsAtvPwrCRC : 0|8@1+ (1,0) [0|255] "count" Vector__XXX
 SG_ MtrGnrtr5InvrtrLmtsAtvPwrCntr : 8|4@1+ (1,0) [0|15] "" Vector__XXX
 SG_ MtGt5IvtLtsAtvMPwMx : 12|12@1+ (42370,-125) [-125|125.9375] "%" Vector__XXX
 SG_ MtGt5IvtLtsAtvMPwM : 24|12@1+ (42370,-125) [-125|125.9375] "%" Vector__XXX
 SG_ MtGt5IvtLtsAtvDCSdPwMx : 36|12@1+ (42370,-125) [-125|125.9375] "%" Vector__XXX
 SG_ MtGt5IvtLtsAtvDCSdPwM : 48|12@1+ (42370,-125) [-125|125.9375] "%" Vector__XXX

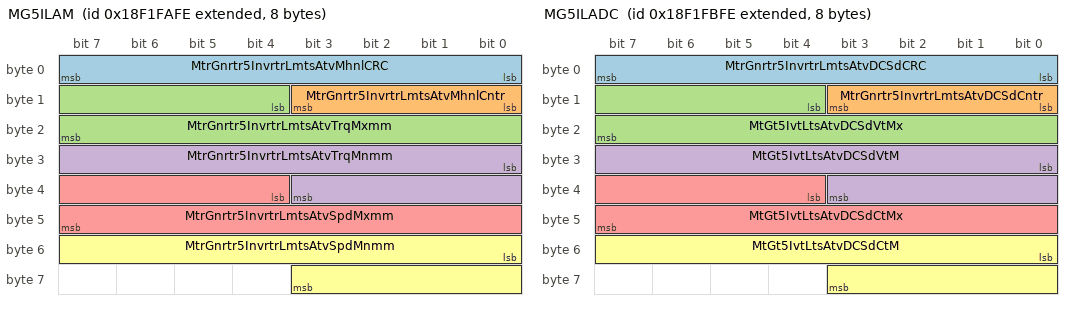
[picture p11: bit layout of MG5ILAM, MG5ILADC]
BO_ 2565995262 MG5ILAM: 8 Vector__XXX
 SG_ MtrGnrtr5InvrtrLmtsAtvMhnlCRC : 0|8@1+ (1,0) [0|255] "count" Vector__XXX
 SG_ MtrGnrtr5InvrtrLmtsAtvMhnlCntr : 8|4@1+ (1,0) [0|15] "" Vector__XXX
 SG_ MtrGnrtr5InvrtrLmtsAtvTrqMxmm : 12|12@1+ (42370,-125) [-125|125.9375] "%" Vector__XXX
 SG_ MtrGnrtr5InvrtrLmtsAtvTrqMnmm : 24|12@1+ (42370,-125) [-125|125.9375] "%" Vector__XXX
 SG_ MtrGnrtr5InvrtrLmtsAtvSpdMxmm : 36|12@1+ (42370,-125) [-125|125.9375] "%" Vector__XXX
 SG_ MtrGnrtr5InvrtrLmtsAtvSpdMnmm : 48|12@1+ (42370,-125) [-125|125.9375] "%" Vector__XXX

BO_ 2565995518 MG5ILADC: 8 Vector__XXX
 SG_ MtrGnrtr5InvrtrLmtsAtvDCSdCRC : 0|8@1+ (1,0) [0|255] "count" Vector__XXX
 SG_ MtrGnrtr5InvrtrLmtsAtvDCSdCntr : 8|4@1+ (1,0) [0|15] "" Vector__XXX
 SG_ MtGt5IvtLtsAtvDCSdVtMx : 12|12@1+ (42370,-125) [-125|125.9375] "%" Vector__XXX
 SG_ MtGt5IvtLtsAtvDCSdVtM : 24|12@1+ (42370,-125) [-125|125.9375] "%" Vector__XXX
 SG_ MtGt5IvtLtsAtvDCSdCtMx : 36|12@1+ (42370,-125) [-125|125.9375] "%" Vector__XXX
 SG_ MtGt5IvtLtsAtvDCSdCtM : 48|12@1+ (42370,-125) [-125|125.9375] "%" Vector__XXX

BO_ 2565995774 MG5ILV: 8 Vector__XXX
 SG_ MtrGnrtr5InvrtrSwthdIgntnVltg : 0|16@1+ (0.05,0) [0|3212.75] "V" Vector__XXX
 SG_ MtrGnrtr5InvrtrUnswthdSLIVltg : 16|16@1+ (0.05,0) [0|3212.75] "V" Vector__XXX

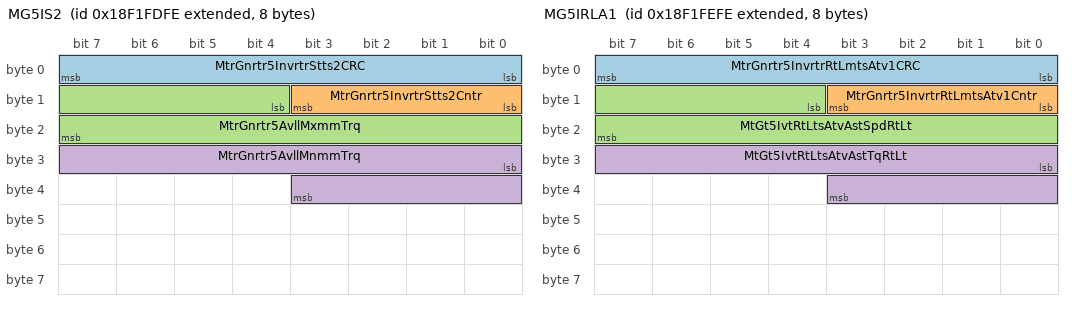
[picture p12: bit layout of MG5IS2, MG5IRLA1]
BO_ 2565996030 MG5IS2: 8 Vector__XXX
 SG_ MtrGnrtr5InvrtrStts2CRC : 0|8@1+ (1,0) [0|255] "count" Vector__XXX
 SG_ MtrGnrtr5InvrtrStts2Cntr : 8|4@1+ (1,0) [0|15] "" Vector__XXX
 SG_ MtrGnrtr5AvllMxmmTrq : 12|12@1+ (42370,-125) [-125|125.9375] "%" Vector__XXX
 SG_ MtrGnrtr5AvllMnmmTrq : 24|12@1+ (42370,-125) [-125|125.9375] "%" Vector__XXX

BO_ 2565996286 MG5IRLA1: 8 Vector__XXX
 SG_ MtrGnrtr5InvrtrRtLmtsAtv1CRC : 0|8@1+ (1,0) [0|255] "count" Vector__XXX
 SG_ MtrGnrtr5InvrtrRtLmtsAtv1Cntr : 8|4@1+ (1,0) [0|15] "" Vector__XXX
 SG_ MtGt5IvtRtLtsAtvAstSpdRtLt : 12|12@1+ (0.25,0) [0|1003.75] "%/s" Vector__XXX
 SG_ MtGt5IvtRtLtsAtvAstTqRtLt : 24|12@1+ (2,0) [0|8030] "%/s" Vector__XXX

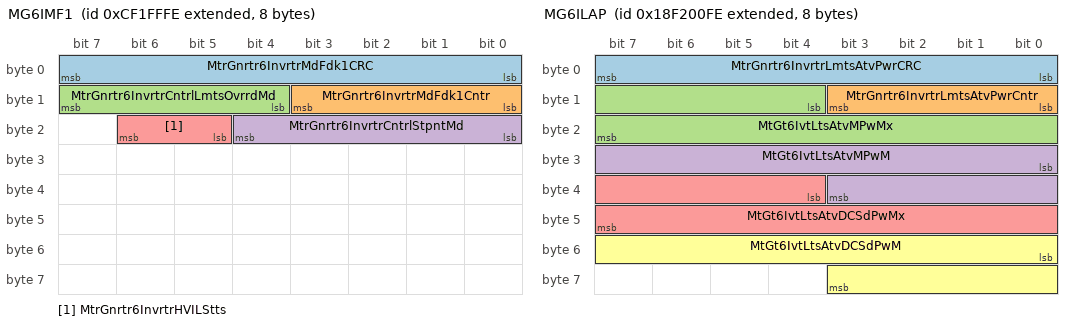
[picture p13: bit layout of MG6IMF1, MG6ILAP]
BO_ 2364669950 MG6IMF1: 8 Vector__XXX
 SG_ MtrGnrtr6InvrtrMdFdk1CRC : 0|8@1+ (1,0) [0|255] "count" Vector__XXX
 SG_ MtrGnrtr6InvrtrMdFdk1Cntr : 8|4@1+ (1,0) [0|15] "" Vector__XXX
 SG_ MtrGnrtr6InvrtrCntrlLmtsOvrrdMd : 12|4@1+ (1,0) [0|15] "" Vector__XXX
 SG_ MtrGnrtr6InvrtrCntrlStpntMd : 16|5@1+ (1,0) [0|31] "" Vector__XXX
 SG_ MtrGnrtr6InvrtrHVILStts : 21|2@1+ (1,0) [0|3] "" Vector__XXX

BO_ 2565996798 MG6ILAP: 8 Vector__XXX
 SG_ MtrGnrtr6InvrtrLmtsAtvPwrCRC : 0|8@1+ (1,0) [0|255] "count" Vector__XXX
 SG_ MtrGnrtr6InvrtrLmtsAtvPwrCntr : 8|4@1+ (1,0) [0|15] "" Vector__XXX
 SG_ MtGt6IvtLtsAtvMPwMx : 12|12@1+ (42370,-125) [-125|125.9375] "%" Vector__XXX
 SG_ MtGt6IvtLtsAtvMPwM : 24|12@1+ (42370,-125) [-125|125.9375] "%" Vector__XXX
 SG_ MtGt6IvtLtsAtvDCSdPwMx : 36|12@1+ (42370,-125) [-125|125.9375] "%" Vector__XXX
 SG_ MtGt6IvtLtsAtvDCSdPwM : 48|12@1+ (42370,-125) [-125|125.9375] "%" Vector__XXX

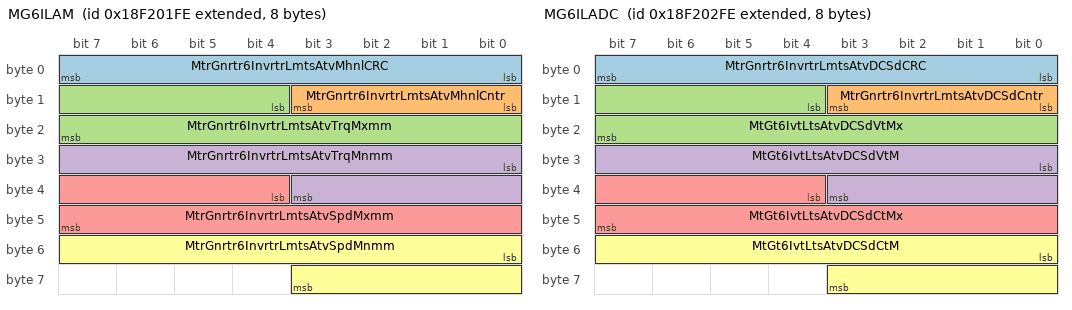
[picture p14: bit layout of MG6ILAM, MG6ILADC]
BO_ 2565997054 MG6ILAM: 8 Vector__XXX
 SG_ MtrGnrtr6InvrtrLmtsAtvMhnlCRC : 0|8@1+ (1,0) [0|255] "count" Vector__XXX
 SG_ MtrGnrtr6InvrtrLmtsAtvMhnlCntr : 8|4@1+ (1,0) [0|15] "" Vector__XXX
 SG_ MtrGnrtr6InvrtrLmtsAtvTrqMxmm : 12|12@1+ (42370,-125) [-125|125.9375] "%" Vector__XXX
 SG_ MtrGnrtr6InvrtrLmtsAtvTrqMnmm : 24|12@1+ (42370,-125) [-125|125.9375] "%" Vector__XXX
 SG_ MtrGnrtr6InvrtrLmtsAtvSpdMxmm : 36|12@1+ (42370,-125) [-125|125.9375] "%" Vector__XXX
 SG_ MtrGnrtr6InvrtrLmtsAtvSpdMnmm : 48|12@1+ (42370,-125) [-125|125.9375] "%" Vector__XXX

BO_ 2565997310 MG6ILADC: 8 Vector__XXX
 SG_ MtrGnrtr6InvrtrLmtsAtvDCSdCRC : 0|8@1+ (1,0) [0|255] "count" Vector__XXX
 SG_ MtrGnrtr6InvrtrLmtsAtvDCSdCntr : 8|4@1+ (1,0) [0|15] "" Vector__XXX
 SG_ MtGt6IvtLtsAtvDCSdVtMx : 12|12@1+ (42370,-125) [-125|125.9375] "%" Vector__XXX
 SG_ MtGt6IvtLtsAtvDCSdVtM : 24|12@1+ (42370,-125) [-125|125.9375] "%" Vector__XXX
 SG_ MtGt6IvtLtsAtvDCSdCtMx : 36|12@1+ (42370,-125) [-125|125.9375] "%" Vector__XXX
 SG_ MtGt6IvtLtsAtvDCSdCtM : 48|12@1+ (42370,-125) [-125|125.9375] "%" Vector__XXX

BO_ 2565997566 MG6ILV: 8 Vector__XXX
 SG_ MtrGnrtr6InvrtrSwthdIgntnVltg : 0|16@1+ (0.05,0) [0|3212.75] "V" Vector__XXX
 SG_ MtrGnrtr6InvrtrUnswthdSLIVltg : 16|16@1+ (0.05,0) [0|3212.75] "V" Vector__XXX

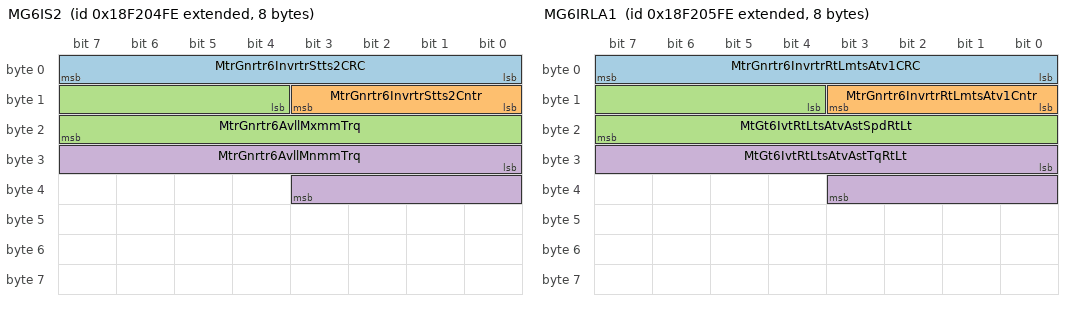
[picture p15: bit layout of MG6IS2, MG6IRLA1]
BO_ 2565997822 MG6IS2: 8 Vector__XXX
 SG_ MtrGnrtr6InvrtrStts2CRC : 0|8@1+ (1,0) [0|255] "count" Vector__XXX
 SG_ MtrGnrtr6InvrtrStts2Cntr : 8|4@1+ (1,0) [0|15] "" Vector__XXX
 SG_ MtrGnrtr6AvllMxmmTrq : 12|12@1+ (42370,-125) [-125|125.9375] "%" Vector__XXX
 SG_ MtrGnrtr6AvllMnmmTrq : 24|12@1+ (42370,-125) [-125|125.9375] "%" Vector__XXX

BO_ 2565998078 MG6IRLA1: 8 Vector__XXX
 SG_ MtrGnrtr6InvrtrRtLmtsAtv1CRC : 0|8@1+ (1,0) [0|255] "count" Vector__XXX
 SG_ MtrGnrtr6InvrtrRtLmtsAtv1Cntr : 8|4@1+ (1,0) [0|15] "" Vector__XXX
 SG_ MtGt6IvtRtLtsAtvAstSpdRtLt : 12|12@1+ (0.25,0) [0|1003.75] "%/s" Vector__XXX
 SG_ MtGt6IvtRtLtsAtvAstTqRtLt : 24|12@1+ (2,0) [0|8030] "%/s" Vector__XXX

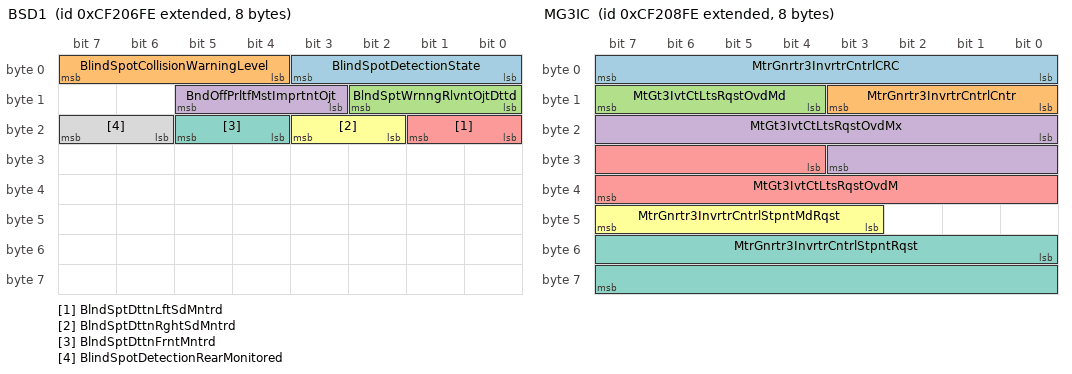
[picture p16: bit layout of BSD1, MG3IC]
BO_ 2364671742 BSD1: 8 Vector__XXX
 SG_ BlindSpotDetectionState : 0|4@1+ (1,0) [0|15] "" Vector__XXX
 SG_ BlindSpotCollisionWarningLevel : 4|4@1+ (1,0) [0|15] "" Vector__XXX
 SG_ BlndSptWrnngRlvntOjtDttd : 8|3@1+ (1,0) [0|7] "" Vector__XXX
 SG_ BndOffPrltfMstImprtntOjt : 11|3@1+ (1,0) [0|7] "" Vector__XXX
 SG_ BlndSptDttnLftSdMntrd : 16|2@1+ (1,0) [0|3] "" Vector__XXX
 SG_ BlndSptDttnRghtSdMntrd : 18|2@1+ (1,0) [0|3] "" Vector__XXX
 SG_ BlndSptDttnFrntMntrd : 20|2@1+ (1,0) [0|3] "" Vector__XXX
 SG_ BlindSpotDetectionRearMonitored : 22|2@1+ (1,0) [0|3] "" Vector__XXX

BO_ 2364671998 WINCH1: 8 Vector__XXX
 SG_ WinchMotorEncoderPosition : 0|16@1+ (1,0) [0|64255] "count" Vector__XXX
 SG_ WinchRevolutionCounter : 16|16@1+ (1,-32128) [-32128|32127] "count" Vector__XXX

BO_ 2364672254 MG3IC: 8 Vector__XXX
 SG_ MtrGnrtr3InvrtrCntrlCRC : 0|8@1+ (1,0) [0|255] "count" Vector__XXX
 SG_ MtrGnrtr3InvrtrCntrlCntr : 8|4@1+ (1,0) [0|15] "" Vector__XXX
 SG_ MtGt3IvtCtLtsRqstOvdMd : 12|4@1+ (1,0) [0|15] "" Vector__XXX
 SG_ MtGt3IvtCtLtsRqstOvdMx : 16|12@1+ (42370,-125) [-125|125.9375] "%" Vector__XXX
 SG_ MtGt3IvtCtLtsRqstOvdM : 28|12@1+ (42370,-125) [-125|125.9375] "%" Vector__XXX
 SG_ MtrGnrtr3InvrtrCntrlStpntMdRqst : 43|5@1+ (1,0) [0|31] "" Vector__XXX
 SG_ MtrGnrtr3InvrtrCntrlStpntRqst : 48|16@1+ (0.00390625,-125) [-125|125.99609375] "%" Vector__XXX

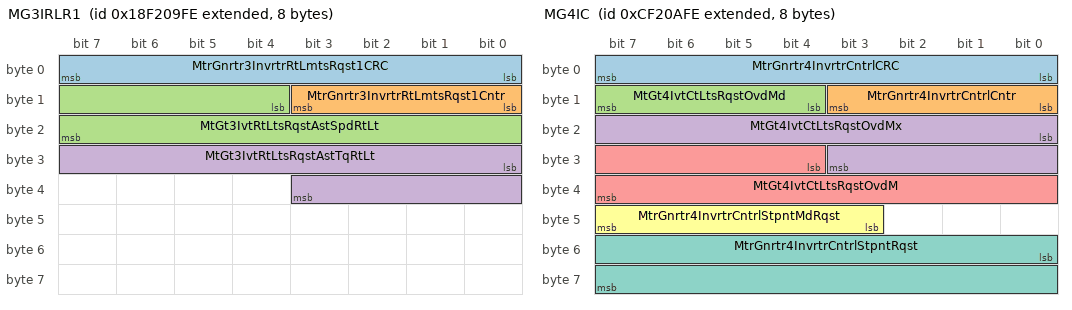
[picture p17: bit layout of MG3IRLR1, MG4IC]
BO_ 2565999102 MG3IRLR1: 8 Vector__XXX
 SG_ MtrGnrtr3InvrtrRtLmtsRqst1CRC : 0|8@1+ (1,0) [0|255] "count" Vector__XXX
 SG_ MtrGnrtr3InvrtrRtLmtsRqst1Cntr : 8|4@1+ (1,0) [0|15] "" Vector__XXX
 SG_ MtGt3IvtRtLtsRqstAstSpdRtLt : 12|12@1+ (0.25,0) [0|1003.75] "%/s" Vector__XXX
 SG_ MtGt3IvtRtLtsRqstAstTqRtLt : 24|12@1+ (2,0) [0|8030] "%/s" Vector__XXX

BO_ 2364672766 MG4IC: 8 Vector__XXX
 SG_ MtrGnrtr4InvrtrCntrlCRC : 0|8@1+ (1,0) [0|255] "count" Vector__XXX
 SG_ MtrGnrtr4InvrtrCntrlCntr : 8|4@1+ (1,0) [0|15] "" Vector__XXX
 SG_ MtGt4IvtCtLtsRqstOvdMd : 12|4@1+ (1,0) [0|15] "" Vector__XXX
 SG_ MtGt4IvtCtLtsRqstOvdMx : 16|12@1+ (42370,-125) [-125|125.9375] "%" Vector__XXX
 SG_ MtGt4IvtCtLtsRqstOvdM : 28|12@1+ (42370,-125) [-125|125.9375] "%" Vector__XXX
 SG_ MtrGnrtr4InvrtrCntrlStpntMdRqst : 43|5@1+ (1,0) [0|31] "" Vector__XXX
 SG_ MtrGnrtr4InvrtrCntrlStpntRqst : 48|16@1+ (0.00390625,-125) [-125|125.99609375] "%" Vector__XXX

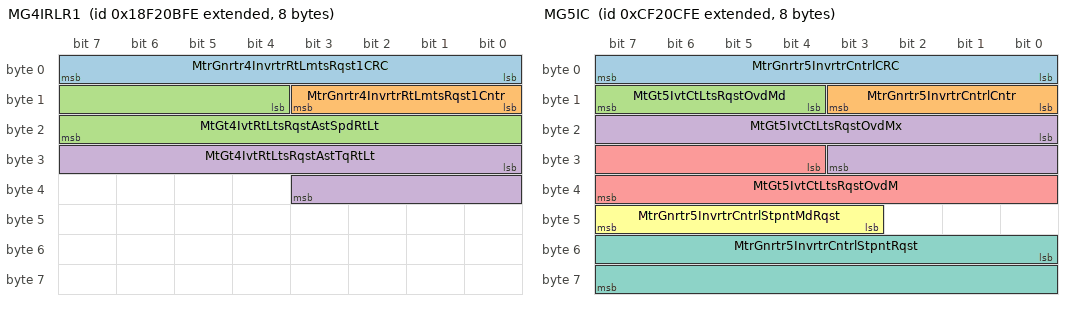
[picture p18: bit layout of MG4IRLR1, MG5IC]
BO_ 2565999614 MG4IRLR1: 8 Vector__XXX
 SG_ MtrGnrtr4InvrtrRtLmtsRqst1CRC : 0|8@1+ (1,0) [0|255] "count" Vector__XXX
 SG_ MtrGnrtr4InvrtrRtLmtsRqst1Cntr : 8|4@1+ (1,0) [0|15] "" Vector__XXX
 SG_ MtGt4IvtRtLtsRqstAstSpdRtLt : 12|12@1+ (0.25,0) [0|1003.75] "%/s" Vector__XXX
 SG_ MtGt4IvtRtLtsRqstAstTqRtLt : 24|12@1+ (2,0) [0|8030] "%/s" Vector__XXX

BO_ 2364673278 MG5IC: 8 Vector__XXX
 SG_ MtrGnrtr5InvrtrCntrlCRC : 0|8@1+ (1,0) [0|255] "count" Vector__XXX
 SG_ MtrGnrtr5InvrtrCntrlCntr : 8|4@1+ (1,0) [0|15] "" Vector__XXX
 SG_ MtGt5IvtCtLtsRqstOvdMd : 12|4@1+ (1,0) [0|15] "" Vector__XXX
 SG_ MtGt5IvtCtLtsRqstOvdMx : 16|12@1+ (42370,-125) [-125|125.9375] "%" Vector__XXX
 SG_ MtGt5IvtCtLtsRqstOvdM : 28|12@1+ (42370,-125) [-125|125.9375] "%" Vector__XXX
 SG_ MtrGnrtr5InvrtrCntrlStpntMdRqst : 43|5@1+ (1,0) [0|31] "" Vector__XXX
 SG_ MtrGnrtr5InvrtrCntrlStpntRqst : 48|16@1+ (0.00390625,-125) [-125|125.99609375] "%" Vector__XXX

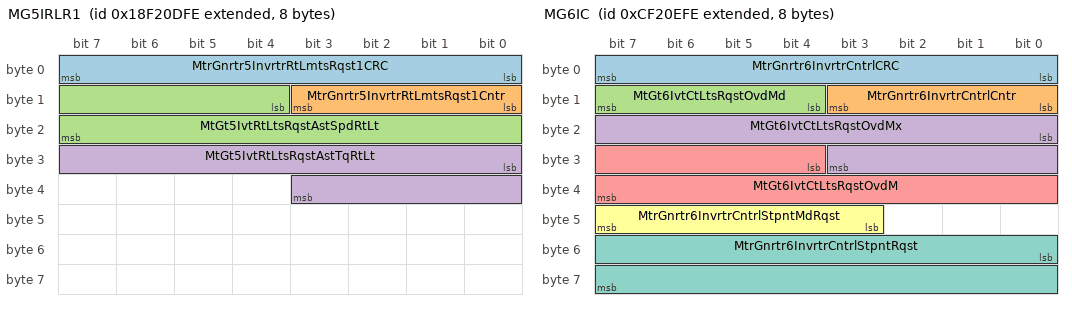
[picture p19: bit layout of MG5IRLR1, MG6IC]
BO_ 2566000126 MG5IRLR1: 8 Vector__XXX
 SG_ MtrGnrtr5InvrtrRtLmtsRqst1CRC : 0|8@1+ (1,0) [0|255] "count" Vector__XXX
 SG_ MtrGnrtr5InvrtrRtLmtsRqst1Cntr : 8|4@1+ (1,0) [0|15] "" Vector__XXX
 SG_ MtGt5IvtRtLtsRqstAstSpdRtLt : 12|12@1+ (0.25,0) [0|1003.75] "%/s" Vector__XXX
 SG_ MtGt5IvtRtLtsRqstAstTqRtLt : 24|12@1+ (2,0) [0|8030] "%/s" Vector__XXX

BO_ 2364673790 MG6IC: 8 Vector__XXX
 SG_ MtrGnrtr6InvrtrCntrlCRC : 0|8@1+ (1,0) [0|255] "count" Vector__XXX
 SG_ MtrGnrtr6InvrtrCntrlCntr : 8|4@1+ (1,0) [0|15] "" Vector__XXX
 SG_ MtGt6IvtCtLtsRqstOvdMd : 12|4@1+ (1,0) [0|15] "" Vector__XXX
 SG_ MtGt6IvtCtLtsRqstOvdMx : 16|12@1+ (42370,-125) [-125|125.9375] "%" Vector__XXX
 SG_ MtGt6IvtCtLtsRqstOvdM : 28|12@1+ (42370,-125) [-125|125.9375] "%" Vector__XXX
 SG_ MtrGnrtr6InvrtrCntrlStpntMdRqst : 43|5@1+ (1,0) [0|31] "" Vector__XXX
 SG_ MtrGnrtr6InvrtrCntrlStpntRqst : 48|16@1+ (0.00390625,-125) [-125|125.99609375] "%" Vector__XXX

BO_ 2566000638 MG6IRLR1: 8 Vector__XXX
 SG_ MtrGnrtr6InvrtrRtLmtsRqst1CRC : 0|8@1+ (1,0) [0|255] "count" Vector__XXX
 SG_ MtrGnrtr6InvrtrRtLmtsRqst1Cntr : 8|4@1+ (1,0) [0|15] "" Vector__XXX
 SG_ MtGt6IvtRtLtsRqstAstSpdRtLt : 12|12@1+ (0.25,0) [0|1003.75] "%/s" Vector__XXX
 SG_ MtGt6IvtRtLtsRqstAstTqRtLt : 24|12@1+ (2,0) [0|8030] "%/s" Vector__XXX

BO_ 2566574078 EVCC1D1: 200 Vector__XXX
 SG_ EVCC1ControlPilotmaximumvoltage : 0|16@1+ (0.05,-1606) [-1606|1606.75] "V" Vector__XXX
 SG_ EVCC1ControlPilotminimumvoltage : 16|16@1+ (0.05,-1606) [-1606|1606.75] "V" Vector__XXX
 SG_ EVCC1ControlPilotPWMfrequency : 32|16@1+ (1,0) [0|64255] "Hz" Vector__XXX
 SG_ EVCC1ControlPilotDutyCycle : 48|8@1+ (0.5,0) [0|125] "%" Vector__XXX
 SG_ EVCC1ControlPilotState : 56|4@1+ (1,0) [0|15] "" Vector__XXX
 SG_ EVCC1ControlPilotSubState : 60|4@1+ (1,0) [0|15] "" Vector__XXX
 SG_ EVCC1Proximitycircuitvoltage : 64|16@1+ (0.01,0) [0|642.55] "V" Vector__XXX
 SG_ EVCC1Inletconnectortemperature : 80|8@1+ (1,-40) [-40|210] "degC" Vector__XXX
 SG_ EVCC1CompatibilityCode : 88|4@1+ (1,0) [0|15] "" Vector__XXX

BO_ 2499465470 CDC2: 8 Vector__XXX
 SG_ Mirror1LeftRightSelection : 0|3@1+ (1,0) [0|7] "" Vector__XXX
 SG_ Mirror2LeftRightSelection : 3|3@1+ (1,0) [0|7] "" Vector__XXX
 SG_ MirrorPrimarySecondarySelection : 8|3@1+ (1,0) [0|7] "" Vector__XXX

BO_ 2499465726 EAI2: 8 Vector__XXX
 SG_ EngnClndrTmprtrAvrg : 0|16@1+ (0.03125,-273) [-273|1734.96875] "degC" Vector__XXX
 SG_ EngnClndrBnk1TmprtrAvrg : 16|16@1+ (0.03125,-273) [-273|1734.96875] "degC" Vector__XXX
 SG_ EngnClndrBnk2TmprtrAvrg : 32|16@1+ (0.03125,-273) [-273|1734.96875] "degC" Vector__XXX

CM_ BO_ 2364656894 "High Voltage Energy Storage Pack 5 Status 2";
CM_ SG_ 2364656894 HVESP5DshrgPwrLmtDtSttfChrg "HVESP5 Discharge Power Limit Due to State of Charge: Indicates whether or not discharge power of this HVES instance is being limited due to state of charge.This parameter is for one of multiple packs in an HVESS.  If there is only one pack in the sys...";
CM_ SG_ 2364656894 HVESP5DshrgPwrLmtDtBttrTmprtr "HVESP5 Discharge Power Limit Due to Battery Temperature: Indicates whether or not discharge power of this HVES instance is being limited due to battery temperature.This parameter is for one of multiple packs in an HVESS.  If there is only one pack in...";
CM_ SG_ 2364656894 HVESP5DsPwLtDtBttDstCdt "HVESP5 Discharge Power Limit Due to Battery Diagnostic Condition: Indicates whether or not discharge power of this HVES instance is being limited due to a battery diagnostic condition.This parameter is for one of multiple packs in an HVESS.  If there...";
CM_ SG_ 2364656894 HVESP5DshrgPwrLmtDtBttrrCllVltg "HVESP5 Discharge Power Limit Due to Battery or Cell Voltage: Indicates whether or not discharge power of this HVES instance is being limited due to a battery or cell voltage level.This parameter is for one of multiple packs in an HVESS.  If there is ...";
CM_ SG_ 2364656894 HVESP5DshrgPwrLmtDtBttrCrrnt "HVESP5 Discharge Power Limit Due to Battery Current: Indicates whether or not discharge power of this HVES instance is being limited due to battery current.This parameter is for one of multiple packs in an HVESS.  If there is only one pack in the sys...";
CM_ SG_ 2364656894 HVESP5DshrgPwrLmtDtnUndfndCs "HVESP5 Discharge Power Limit Due to an Undefined Cause: Indicates whether or not discharge power of this HVES instance is being limited due to an undefined cause.This parameter is for one of multiple packs in an HVESS.  If there is only one pack in t...";
CM_ SG_ 2364656894 HVESP5ChrgPwrLmtDtSttfChrg "HVESP5 Charge Power Limit Due to State of Charge: Indicates whether or not charge power of this HVES instance is being limited due to state of charge.This parameter is for one of multiple packs in an HVESS.  If there is only one pack in the system, t...";
CM_ SG_ 2364656894 HVESP5ChrgPwrLmtDtBttrTmprtr "HVESP5 Charge Power Limit Due to Battery Temperature: Indicates whether or not charge power of this HVES instance is being limited due to battery temperature.This parameter is for one of multiple packs in an HVESS.  If there is only one pack in the s...";
CM_ SG_ 2364656894 HVESP5CPwLtDtBttDstCdt "HVESP5 Charge Power Limit Due to Battery Diagnostic Condition: Indicates whether or not charge power of this HVES instance is being limited due to a battery diagnostic condition.This parameter is for one of multiple packs in an HVESS.  If there is on...";
CM_ SG_ 2364656894 HVESP5ChrgPwrLmtDtBttrrCllVltg "HVESP5 Charge Power Limit Due to Battery or Cell Voltage: Indicates whether or not charge power of this HVES instance is being limited due to a battery or cell voltage level.This parameter is for one of multiple packs in an HVESS.  If there is only o...";
CM_ SG_ 2364656894 HVESP5ChrgPwrLmtDtBttrCrrnt "HVESP5 Charge Power Limit Due to Battery Current: Indicates whether or not charge power of this HVES instance is being limited due to battery current.This parameter is for one of multiple packs in an HVESS.  If there is only one pack in the system, t...";
CM_ SG_ 2364656894 HVESP5ChrgPwrLmtDtnUndfndCs "HVESP5 Charge Power Limit Due to an Undefined Cause: Indicates whether or not charge power of this HVES instance is being limited due to an undefined cause.This parameter is for one of multiple packs in an HVESS.  If there is only one pack in the sys...";
CM_ BO_ 2364657150 "High Voltage Energy Storage Pack 5 Data 1";
CM_ SG_ 2364657150 HVESP5AvailableDischargePower "HVESP5 Available Discharge Power: The rate at which this High Voltage Energy Storage Pack instance can currently provide energy for propulsion or other uses.This parameter is for one of multiple packs in an HVESS.  If there is only one pack in the sy...";
CM_ SG_ 2364657150 HVESP5AvailableChargePower "HVESP5 Available Charge Power: The rate at which this High Voltage Energy Storage Pack instance can currently receive energy from a regenerative or recharging system.This parameter is for one of multiple packs in an HVESS.  If there is only one pack ...";
CM_ SG_ 2364657150 HVESP5VoltageLevel "HVESP5 Voltage Level: The voltage level of this High Voltage Energy Storage Pack instance. This parameter should be synchronized with SPN 11517 (HVESP5 Current) such that a realized power value can be calculated.  If the HVES component physically con...";
CM_ SG_ 2364657150 HVESP5Current "HVESP5 Current: The current in or out of this High Voltage Energy Storage Pack instance. This parameter should be synchronized with SPN 11516 (HVESP5 Voltage Level) such that a realized power value can be calculated.  This parameter is defined from t...";
CM_ BO_ 2364657406 "High Voltage Energy Storage Pack 5 Data 2";
CM_ SG_ 2364657406 HVESP5FastUpdateStateofCharge "HVESP5 Fast Update State of Charge: Indicates this High Voltage Energy Storage Pack instance state of charge.  0% means no charge remaining, 100% means the system is fully charged in terms of physical limits of this energy storage pack instance.  Acc...";
CM_ SG_ 2364657406 HVESP5HighestCellVoltage "HVESP5 Highest Cell Voltage: The highest voltage level reported by any cell in this High Voltage Energy Storage Pack instance. If a single voltage sensor covers more than one cell, the value in this parameter is for the smallest group of cells measur...";
CM_ SG_ 2364657406 HVESP5LowestCellVoltage "HVESP5 Lowest Cell Voltage: The lowest voltage level reported by any cell in this High Voltage Energy Storage Pack instance. If a single voltage sensor covers more than one cell, the value in this parameter is for the smallest group of cells measured...";
CM_ SG_ 2364657406 HVESP5CllVltgDffrntlStts "HVESP5 Cell Voltage Differential Status: Indicates whether or not the differential between the highest and lowest cell voltages are within acceptable limits, according to this High Voltage Energy Storage Pack instance. The actual voltage differential...";
CM_ BO_ 2364657662 "High Voltage Energy Storage Pack 5 Data 3";
CM_ SG_ 2364657662 HVESP5HighestCellTemperature "HVESP5 Highest Cell Temperature: The highest temperature level reported by any cell in this High Voltage Energy Storage Pack instance.  If a single temperature sensor covers more than one cell, the value in this parameter is for the smallest group of...";
CM_ SG_ 2364657662 HVESP5LowestCellTemperature "HVESP5 Lowest Cell Temperature: The lowest temperature level reported by any cell in this High Voltage Energy Storage Pack instance.  If a single temperature sensor covers more than one cell, the value in this parameter is for the smallest group of c...";
CM_ SG_ 2364657662 HVESP5AverageCellTemperature "HVESP5 Average Cell Temperature: The average temperature level of all cells in this High Voltage Energy Storage Pack instance.This parameter is for one of multiple packs in an HVESS.  If there is only one pack in the system, the HVESS parameters shou...";
CM_ SG_ 2364657662 HVESP5CllTmprtrDffrntlStts "HVESP5 Cell Temperature Differential Status: Indicates whether or not the differential between the highest and lowest cell temperatures are within acceptable limits per this High Voltage Energy Storage Pack instance.  The actual temperature different...";
CM_ BO_ 2364657918 "High Voltage Energy Storage Pack 5 Data 4";
CM_ SG_ 2364657918 HVESP5DischargeCapacity "HVESP5 Discharge Capacity: The amount of stored electrical charge in this High Voltage Energy Storage Pack instance that is available for use by the hybrid system, i.e. “how full is the tank”.  See SPN 11554 (HVESP5 Discharge Energy Capacity) for kil...";
CM_ SG_ 2364657918 HVESP5ChargeCapacity "HVESP5 Charge Capacity: The amount of unused electrical charge storage in this High Voltage Energy Storage Pack instance that is available to be filled by charging, i.e. “how much empty space is remaining in the tank”.  See SPN 11555 (HVESP5 Charge E...";
CM_ SG_ 2364657918 HVESP5CellBalancingCount "HVESP5 Cell Balancing Count: The number of cells that are currently being balanced in this High Voltage Energy Storage Pack instance.This parameter is for one of multiple packs in an HVESS.  If there is only one pack in the system, the HVESS paramete...";
CM_ BO_ 2364658174 "High Voltage Energy Storage Pack 5 Data 5";
CM_ SG_ 2364658174 HVESP5DischargeCurrentLimit "HVESP5 Discharge Current Limit: The maximum permissible current flow out of this High Voltage Energy Storage Pack instance. This parameter is defined from the high voltage energy storage pack's point of view.A negative value represents current flowin...";
CM_ SG_ 2364658174 HVESP5ChargeCurrentLimit "HVESP5 Charge Current Limit: The maximum permissible current flow into this High Voltage Energy Storage Pack instance. This parameter is defined from the high voltage energy storage pack's point of view.A positive value represents current flowing int...";
CM_ SG_ 2364658174 HVESP5LowestCellStateofCharge "HVESP5 Lowest Cell State of Charge: Indicates the state of charge of the lowest-charged cell in this High Voltage Energy Storage Pack instance.  0% means no charge remaining, 100% means the cell is fully charged.   If a single state of charge value c...";
CM_ SG_ 2364658174 HVESP5HighestCellStateofCharge "HVESP5 Highest Cell State of Charge: Indicates the state of charge of the highest-charged cell in this High Voltage Energy Storage Pack instance.  0% means no charge remaining, 100% means the cell is fully charged.  If a single state of charge value ...";
CM_ BO_ 2364658430 "High Voltage Energy Storage Pack 5 Data 6";
CM_ SG_ 2364658430 HVESP5BusVoltage "HVESP5 Bus Voltage: The voltage level of the high voltage bus, as measured by this High Voltage Energy Storage Pack instance on the bus side (not the battery side) of its contactors.This parameter is for one of multiple packs in an HVESS.  If there i...";
CM_ SG_ 2364658430 HVESP5IgnitionVoltage "HVESP5 Ignition Voltage: The voltage level at the ignition input of this High Voltage Energy Storage Pack controller.This parameter is for one of multiple packs in an HVESS.  If there is only one pack in the system, the HVESS parameters should be use...";
CM_ SG_ 2364658430 HVESP5IntakeCoolantTemperature "HVESP5 Intake Coolant Temperature: The temperature of liquid coolant as it enters this High Voltage Energy Storage Pack instance.This parameter is for one of multiple packs in an HVESS.  If there is only one pack in the system, the HVESS parameters s...";
CM_ SG_ 2364658430 HVESP5OutletCoolantTemperature "HVESP5 Outlet Coolant Temperature: The temperature of liquid coolant as it exits this High Voltage Energy Storage Pack instance.This parameter is for one of multiple packs in an HVESS.  If there is only one pack in the system, the HVESS parameters sh...";
CM_ SG_ 2364658430 HVESP5ElectronicsTemperature "HVESP5 Electronics Temperature: The temperature of the electronics or control modules in this High Voltage Energy Storage Pack instance.  If there are multiple temperature sensors then this parameter would be set to the maximum sensor reading.This pa...";
CM_ SG_ 2364658430 HVESP5Temperature "HVESP5 Temperature: The temperature of this High Voltage Energy Storage Pack instance. The value may be determined from a unique sensor specifically for this purpose, or by aggregating various temperature sensor readings within the pack.This paramete...";
CM_ BO_ 2364658686 "High Voltage Energy Storage Pack 5 Status 1";
CM_ SG_ 2364658686 HVESP5HghVltgBsPstvCnttrStt "HVESP5 High-Voltage Bus (Positive) Contactor State: Position of this High Voltage Energy Storage Pack instance positive side bus contactor.  When this contactor is closed, the positive side of this HVES instance is connected to the positive side of t...";
CM_ SG_ 2364658686 HVESP5HghVltgBsNgtvCnttrStt "HVESP5 High-Voltage Bus (Negative) Contactor State: Position of this High Voltage Energy Storage Pack instance negative side bus contactor.  When this contactor is closed, the negative side of this HVES instance is connected to the negative side of t...";
CM_ SG_ 2364658686 HVESP5HghVltgBsDsnntFrwrnng "HVESP5 High-Voltage Bus Disconnect Forewarning: Indicates that this High Voltage Energy Storage Pack instance is about to disconnect from the high voltage bus due to unacceptable conditions.This parameter is for one of multiple packs in an HVESS. If ...";
CM_ SG_ 2364658686 HVESP5HghVltgBsPrChrgRlStt "HVESP5 High-Voltage Bus Pre-Charge Relay State: Position of the high-voltage bus contactor pre-charge relay.  When this relay is closed, this High Voltage Energy Storage Pack instance is bringing the high-voltage bus up to its operating level.This pa...";
CM_ SG_ 2364658686 HVESP5CntrfPkCnttrStt "HVESP5 Center of Pack Contactor State: Position of the center high-voltage contactor.  When this contactor is closed, the positive half of this High Voltage Energy Storage Pack instance is connected to the negative half.  If a system controls the pos...";
CM_ SG_ 2364658686 HVESP5HghVltgBsAtvIsltnTstStts "HVESP5 High-Voltage Bus Active Isolation Test Status: Status of the high-voltage bus electrical active isolation test as performed by this High Voltage Energy Storage Pack instance.This parameter is for one of multiple packs in an HVESS. If there is ...";
CM_ SG_ 2364658686 HVESP5HghVltgBsPssvIsltnTstStts "HVESP5 High-Voltage Bus Passive Isolation Test Status: Status of the high-voltage bus electrical passive isolation test as performed by this High Voltage Energy Storage Pack instance.This parameter is for one of multiple packs in an HVESS. If there i...";
CM_ SG_ 2364658686 HVESP5HVILStatus "HVESP5 HVIL Status: Status of the High Voltage Interlock Loop from the viewpoint of this High Voltage Energy Storage Pack instance.This parameter is for one of multiple packs in an HVESS. If there is only one pack in the system, the HVESS parameters ...";
CM_ SG_ 2364658686 HVESP5InertiaSwitchStatus "HVESP5 Inertia Switch Status: Switch indicating that an impact has been sensed by this High Voltage Energy Storage Pack instance. The impact indication may require action by another controller, or by this HVES instance itself.  For example, a control...";
CM_ SG_ 2364658686 HVESP5StateofChargeStatus "HVESP5 State of Charge Status: Status of this High Voltage Energy Storage Pack instance State of Charge (SOC).  Note:  A given HVES controller may not support all of the states.This parameter is for one of multiple packs in an HVESS.  If there is onl...";
CM_ SG_ 2364658686 HVESP5CellBalanceStatus "HVESP5 Cell Balance Status: Indicates whether or not the cells in this High Voltage Energy Storage Pack instance are balanced.This parameter is for one of multiple packs in an HVESS.  If there is only one pack in the system, the HVESS parameters shou...";
CM_ SG_ 2364658686 HVESP5CellBalancingActive "HVESP5 Cell Balancing Active: Indicates whether or not the cells in this High Voltage Energy Storage Pack instance are currently being balanced.This parameter is for one of multiple packs in an HVESS.  If there is only one pack in the system, the HVE...";
CM_ SG_ 2364658686 HVESP5InternalChargerStatus "HVESP5 Internal Charger Status: Indicates that the charger in this HVES instance is on.  External chargers may use the External Energy Source Connection Status (SPN 7898) and related SPs.This parameter is for one of multiple packs in an HVESS. If the...";
CM_ SG_ 2364658686 HVESP5HghVltgBsCnntnStts "HVESP5 High-Voltage Bus Connection Status: This parameter provides high level feedback on this High Voltage Energy Storage Pack instance high voltage bus connection.  For specific contactor information, see SPN 11539 (HVESP5 High-Voltage Bus (Positiv...";
CM_ SG_ 2364658686 HVESP5OperationalStatus "HVESP5 Operational Status: Provides feedback on where this High Voltage Energy Storage Pack instance is in its operating spectrum, and includes feedback in response to the Operation Consent [i.e. SPN 11499 (HVESP5 Operation Consent)] and Power Down C...";
CM_ SG_ 2364658686 HVESP5Status1Counter "HVESP5 Status 1 Counter: The message counter is used to detect situations where the transmitting ECU malfunction repeats the same frame all the time. The receiver of the information may use the counter parameter to detect this situation. The transmit...";
CM_ SG_ 2364658686 HVESP5Status1CRC "HVESP5 Status 1 CRC: The CRC is defined as follows: • Length: 8 bits • Polynomial: x^8+x^5+x^3+x^2+x+1 • Initial Value: FFh • Input Data Reflection: Not reflected • Result Data Reflection: Not reflected • XOR value: FFhSAE makes no claim of the funct...";
CM_ BO_ 2364658942 "High Voltage Energy Storage Pack 5 Data 7";
CM_ SG_ 2364658942 HVESP5DischargeEnergyCapacity "HVESP5 Discharge Energy Capacity: The amount of stored electrical energy in this High Voltage Energy Storage Pack instance that is available for use by the hybrid system, i.e. “how full is the tank”.  See SPN 11526 (HVESP5 Discharge Capacity) for Amp...";
CM_ SG_ 2364658942 HVESP5ChargeEnergyCapacity "HVESP5 Charge Energy Capacity: The amount of unused electrical energy storage available to be filled by charging this High Voltage Energy Storage Pack instance, i.e. “how much empty space is remaining in the tank”.  See SPN 11527 (HVESP5 Charge Capac...";
CM_ SG_ 2364658942 HVESP5MaximumChargeVoltageLimit "HVESP5 Maximum Charge Voltage Limit: The maximum voltage level not to be exceeded while charging this High Voltage Energy Storage Pack instance.  If this parameter is not supported, the maximum charge voltage should be limited to SPN 11598 (HVESP5 Re...";
CM_ BO_ 2364659198 "High Voltage Energy Storage Pack 5 Module Status 1";
CM_ SG_ 2364659198 HVESP5Module1OperationalStatus "HVESP5 Module 1 Operational Status: Operational Status of Module 1 in this High Voltage Energy Storage Pack Instance.  Not Operational is used when the module is initializing or not able to function (e.g. internal module level monitors have failed). ...";
CM_ SG_ 2364659198 HVESP5Module2OperationalStatus "HVESP5 Module 2 Operational Status: Operational Status of Module 2 in this High Voltage Energy Storage Pack Instance.  Not Operational is used when the module is initializing or not able to function (e.g. internal module level monitors have failed). ...";
CM_ SG_ 2364659198 HVESP5Module3OperationalStatus "HVESP5 Module 3 Operational Status: Operational Status of Module 3 in this High Voltage Energy Storage Pack Instance.  Not Operational is used when the module is initializing or not able to function (e.g. internal module level monitors have failed). ...";
CM_ SG_ 2364659198 HVESP5Module4OperationalStatus "HVESP5 Module 4 Operational Status: Operational Status of Module 4 in this High Voltage Energy Storage Pack Instance.  Not Operational is used when the module is initializing or not able to function (e.g. internal module level monitors have failed). ...";
CM_ SG_ 2364659198 HVESP5Module5OperationalStatus "HVESP5 Module 5 Operational Status: Operational Status of Module 5 in this High Voltage Energy Storage Pack Instance.  Not Operational is used when the module is initializing or not able to function (e.g. internal module level monitors have failed). ...";
CM_ SG_ 2364659198 HVESP5Module6OperationalStatus "HVESP5 Module 6 Operational Status: Operational Status of Module 6 in this High Voltage Energy Storage Pack Instance.  Not Operational is used when the module is initializing or not able to function (e.g. internal module level monitors have failed). ...";
CM_ SG_ 2364659198 HVESP5Module7OperationalStatus "HVESP5 Module 7 Operational Status: Operational Status of Module 7 in this High Voltage Energy Storage Pack Instance.  Not Operational is used when the module is initializing or not able to function (e.g. internal module level monitors have failed). ...";
CM_ SG_ 2364659198 HVESP5Module8OperationalStatus "HVESP5 Module 8 Operational Status: Operational Status of Module 8 in this High Voltage Energy Storage Pack Instance.  Not Operational is used when the module is initializing or not able to function (e.g. internal module level monitors have failed). ...";
CM_ SG_ 2364659198 HVESP5Module9OperationalStatus "HVESP5 Module 9 Operational Status: Operational Status of Module 9 in this High Voltage Energy Storage Pack Instance.  Not Operational is used when the module is initializing or not able to function (e.g. internal module level monitors have failed). ...";
CM_ SG_ 2364659198 HVESP5Module10OperationalStatus "HVESP5 Module 10 Operational Status: Operational Status of Module 10 in this High Voltage Energy Storage Pack Instance.  Not Operational is used when the module is initializing or not able to function (e.g. internal module level monitors have failed)...";
CM_ SG_ 2364659198 HVESP5Module11OperationalStatus "HVESP5 Module 11 Operational Status: Operational Status of Module 11 in this High Voltage Energy Storage Pack Instance.  Not Operational is used when the module is initializing or not able to function (e.g. internal module level monitors have failed)...";
CM_ SG_ 2364659198 HVESP5Module12OperationalStatus "HVESP5 Module 12 Operational Status: Operational Status of Module 12 in this High Voltage Energy Storage Pack Instance.  Not Operational is used when the module is initializing or not able to function (e.g. internal module level monitors have failed)...";
CM_ SG_ 2364659198 HVESP5Module13OperationalStatus "HVESP5 Module 13 Operational Status: Operational Status of Module 13 in this High Voltage Energy Storage Pack Instance.  Not Operational is used when the module is initializing or not able to function (e.g. internal module level monitors have failed)...";
CM_ SG_ 2364659198 HVESP5Module14OperationalStatus "HVESP5 Module 14 Operational Status: Operational Status of Module 14 in this High Voltage Energy Storage Pack Instance.  Not Operational is used when the module is initializing or not able to function (e.g. internal module level monitors have failed)...";
CM_ SG_ 2364659198 HVESP5Module15OperationalStatus "HVESP5 Module 15 Operational Status: Operational Status of Module 15 in this High Voltage Energy Storage Pack Instance.  Not Operational is used when the module is initializing or not able to function (e.g. internal module level monitors have failed)...";
CM_ SG_ 2364659198 HVESP5Module16OperationalStatus "HVESP5 Module 16 Operational Status: Operational Status of Module 16 in this High Voltage Energy Storage Pack Instance.  Not Operational is used when the module is initializing or not able to function (e.g. internal module level monitors have failed)...";
CM_ SG_ 2364659198 HVESP5Module17OperationalStatus "HVESP5 Module 17 Operational Status: Operational Status of Module 17 in this High Voltage Energy Storage System (or Pack 1 in systems with only one pack).  Not Operational is used when the module is initializing or not able to function (e.g. internal...";
CM_ SG_ 2364659198 HVESP5Module18OperationalStatus "HVESP5 Module 18 Operational Status: Operational Status of Module 18 in this High Voltage Energy Storage System (or Pack 1 in systems with only one pack).  Not Operational is used when the module is initializing or not able to function (e.g. internal...";
CM_ SG_ 2364659198 HVESP5Module19OperationalStatus "HVESP5 Module 19 Operational Status: Operational Status of Module 19 in this High Voltage Energy Storage System (or Pack 1 in systems with only one pack).  Not Operational is used when the module is initializing or not able to function (e.g. internal...";
CM_ SG_ 2364659198 HVESP5Module20OperationalStatus "HVESP5 Module 20 Operational Status: Operational Status of Module 20 in this High Voltage Energy Storage System (or Pack 1 in systems with only one pack).  Not Operational is used when the module is initializing or not able to function (e.g. internal...";
CM_ SG_ 2364659198 HVESP5Module21OperationalStatus "HVESP5 Module 21 Operational Status: Operational Status of Module 21 in this High Voltage Energy Storage System (or Pack 1 in systems with only one pack).  Not Operational is used when the module is initializing or not able to function (e.g. internal...";
CM_ SG_ 2364659198 HVESP5Module22OperationalStatus "HVESP5 Module 22 Operational Status: Operational Status of Module 22 in this High Voltage Energy Storage System (or Pack 1 in systems with only one pack).  Not Operational is used when the module is initializing or not able to function (e.g. internal...";
CM_ SG_ 2364659198 HVESP5Module23OperationalStatus "HVESP5 Module 23 Operational Status: Operational Status of Module 23 in this High Voltage Energy Storage System (or Pack 1 in systems with only one pack).  Not Operational is used when the module is initializing or not able to function (e.g. internal...";
CM_ SG_ 2364659198 HVESP5Module24OperationalStatus "HVESP5 Module 24 Operational Status: Operational Status of Module 24 in this High Voltage Energy Storage System (or Pack 1 in systems with only one pack).  Not Operational is used when the module is initializing or not able to function (e.g. internal...";
CM_ SG_ 2364659198 HVESP5Module25OperationalStatus "HVESP5 Module 25 Operational Status: Operational Status of Module 25 in this High Voltage Energy Storage System (or Pack 1 in systems with only one pack).  Not Operational is used when the module is initializing or not able to function (e.g. internal...";
CM_ SG_ 2364659198 HVESP5Module26OperationalStatus "HVESP5 Module 26 Operational Status: Operational Status of Module 26 in this High Voltage Energy Storage System (or Pack 1 in systems with only one pack).  Not Operational is used when the module is initializing or not able to function (e.g. internal...";
CM_ SG_ 2364659198 HVESP5Module27OperationalStatus "HVESP5 Module 27 Operational Status: Operational Status of Module 27 in this High Voltage Energy Storage System (or Pack 1 in systems with only one pack).  Not Operational is used when the module is initializing or not able to function (e.g. internal...";
CM_ SG_ 2364659198 HVESP5Module28OperationalStatus "HVESP5 Module 28 Operational Status: Operational Status of Module 28 in this High Voltage Energy Storage System (or Pack 1 in systems with only one pack).  Not Operational is used when the module is initializing or not able to function (e.g. internal...";
CM_ SG_ 2364659198 HVESP5Module29OperationalStatus "HVESP5 Module 29 Operational Status: Operational Status of Module 29 in this High Voltage Energy Storage System (or Pack 1 in systems with only one pack).  Not Operational is used when the module is initializing or not able to function (e.g. internal...";
CM_ SG_ 2364659198 HVESP5Module30OperationalStatus "HVESP5 Module 30 Operational Status: Operational Status of Module 30 in this High Voltage Energy Storage System (or Pack 1 in systems with only one pack).  Not Operational is used when the module is initializing or not able to function (e.g. internal...";
CM_ SG_ 2364659198 HVESP5Module31OperationalStatus "HVESP5 Module 31 Operational Status: Operational Status of Module 31 in this High Voltage Energy Storage System (or Pack 1 in systems with only one pack).  Not Operational is used when the module is initializing or not able to function (e.g. internal...";
CM_ SG_ 2364659198 HVESP5Module32OperationalStatus "HVESP5 Module 32 Operational Status: Operational Status of Module 32 in this High Voltage Energy Storage System (or Pack 1 in systems with only one pack).  Not Operational is used when the module is initializing or not able to function (e.g. internal...";
CM_ BO_ 2364659454 "High Voltage Energy Storage Pack 5 Thermal Management System Status 1";
CM_ SG_ 2364659454 HVESP5ThrmlMngmntSstmSLIInptPwr "HVESP5 Thermal Management System SLI Input Power: This is the low-voltage power consumed by this HVES Thermal Management System (TMS).This parameter is for one of multiple packs in an HVESS.  If there is only one pack in the system, the HVESS paramet...";
CM_ SG_ 2364659454 HVESP5TMtSstHVtIptPw "HVESP5 Thermal Management System High-Voltage Input Power: This is the high-voltage power consumed by this HVES Thermal Management System (TMS).This parameter is for one of multiple packs in an HVESS.  If there is only one pack in the system, the HVE...";
CM_ SG_ 2364659454 HVESP5ThrmlMngmntSstmCmprssrSpd "HVESP5 Thermal Management System Compressor Speed: When this High Voltage Energy Storage Pack Thermal Management System is equipped with an active cooling system (e.g. air conditioner), this is the Compressor Speed.This parameter is for one of multip...";
CM_ SG_ 2364659454 HVESP5ThrmlMngmntSstmRltvHmdt "HVESP5 Thermal Management System Relative Humidty: When this High Voltage Energy Storage Pack Thermal Management System is equipped with a relative humidity sensor, this is the  measured Relative Humidity.This parameter is for one of multiple packs i...";
CM_ SG_ 2364659454 HVESP5ThrmlMngmntSstmHtrStts "HVESP5 Thermal Management System Heater Status: The state of this High Voltage Energy Storage Pack heaterThis parameter is for one of multiple packs in an HVESS.  If there is only one pack in the system, the HVESS parameters should be used. If there ...";
CM_ SG_ 2364659454 HVESP5ThrmlMngmntSstmHVILStts "HVESP5 Thermal Management System HVIL Status: In multiple HVES configurations, this is the status of the High Voltage Interlock Loop from the viewpoint of this Thermal Management System.00b = HVIL Closed01b = HVIL Open10b = Error11b = Not AvailableTh...";
CM_ SG_ 2364659454 HVESP5ThrmlMngmntSstmMd "HVESP5 Thermal Management System Mode: Indicates the operating mode of the Thermal Management System.  The heat transfer medium may be (e.g. liquid or air).  The cooling system may be fans, liquid coolant, or a combination of mediums.  The system may...";
CM_ SG_ 2364659454 HVESP5ThrmlMngmntSstmClntLvl "HVESP5 Thermal Management System Coolant Level: Indicates the coolant level in this HVES Thermal Management System (TMS).This parameter is for one of multiple packs in an HVESS.  If there is only one pack in the system, the HVESS parameters should be...";
CM_ BO_ 2364659710 "High Voltage Energy Storage Pack 5 Data 8";
CM_ SG_ 2364659710 HVESP5HghstCllVltgMdlNmr "HVESP5 Highest Cell Voltage Module Number: Identifies the location of the module containing SPN 11519 (HVESP5 Highest Cell Voltage).This parameter is for one of multiple packs in an HVESS.  If there is only one pack in the system, the HVESS parameter...";
CM_ SG_ 2364659710 HVESP5HghstCllVltgCllNmr "HVESP5 Highest Cell Voltage Cell Number: Identifies the location of SPN 11519 (HVESP5 Highest Cell Voltage) within SPN 11579 (HVESP5 Highest Cell Voltage Module Number).This parameter is for one of multiple packs in an HVESS.  If there is only one pa...";
CM_ SG_ 2364659710 HVESP5LwstCllVltgMdlNmr "HVESP5 Lowest Cell Voltage Module Number: Identifies the location of the module containing SPN 11520 (HVESP5 Lowest Cell Voltage).This parameter is for one of multiple packs in an HVESS.  If there is only one pack in the system, the HVESS parameters ...";
CM_ SG_ 2364659710 HVESP5LwstCllVltgCllNmr "HVESP5 Lowest Cell Voltage Cell Number: Identifies the location of SPN 11520 (HVESP5 Lowest Cell Voltage) within SPN 11581 (HVESP5 Lowest Cell Voltage Module Number).This parameter is for one of multiple packs in an HVESS.  If there is only one pack ...";
CM_ SG_ 2364659710 HVESP5AverageCellVoltage "HVESP5 Average Cell Voltage: The average cell voltage in this High Voltage Energy Storage Pack instance.This parameter is for one of multiple packs in an HVESS.  If there is only one pack in the system, the HVESS parameters should be used. If there a...";
CM_ BO_ 2364659966 "High Voltage Energy Storage Pack 5 Data 9";
CM_ SG_ 2364659966 HVESP5HghstCllTmprtrMdlNmr "HVESP5 Highest Cell Temperature Module Number: Identifies the location of the module containing SPN 11522 (HVESP5 Highest Cell Temperature).This parameter is for one of multiple packs in an HVESS.  If there is only one pack in the system, the HVESS p...";
CM_ SG_ 2364659966 HVESP5HghstCllTmprtrCllNmr "HVESP5 Highest Cell Temperature Cell Number: Identifies the location of SPN 11522 (HVESP5 Highest Cell Temperature) within SPN 11584 (HVESP5 Highest Cell Temperature Module Number).This parameter is for one of multiple packs in an HVESS.  If there is...";
CM_ SG_ 2364659966 HVESP5LwstCllTmprtrMdlNmr "HVESP5 Lowest Cell Temperature Module Number: Identifies the location of the module containing SPN 11523 (HVESP5 Lowest Cell Temperature).This parameter is for one of multiple packs in an HVESS.  If there is only one pack in the system, the HVESS par...";
CM_ SG_ 2364659966 HVESP5LwstCllTmprtrCllNmr "HVESP5 Lowest Cell Temperature Cell Number: Identifies the location of SPN 11523 (HVESP5 Lowest Cell Temperature) within SPN 11586 (HVESP5 Lowest Cell Temperature Module Number).This parameter is for one of multiple packs in an HVESS.  If there is on...";
CM_ BO_ 2364660222 "High Voltage Energy Storage Pack 5 Data 10";
CM_ SG_ 2364660222 HVESP5HghstCllSttfChrgMdlNmr "HVESP5 Highest Cell State of Charge Module Number: Identifies the location of the module containing SPN 11532 (HVESP5 Highest Cell State of Charge).This parameter is for one of multiple packs in an HVESS.  If there is only one pack in the system, the...";
CM_ SG_ 2364660222 HVESP5HghstCllSttfChrgCllNmr "HVESP5 Highest Cell State of Charge Cell Number: Identifies the location of SPN 11532 (HVESP5 Highest Cell State of Charge) within SPN 11588 (HVESP5 Highest Cell State of Charge Module Number).This parameter is for one of multiple packs in an HVESS. ...";
CM_ SG_ 2364660222 HVESP5LwstCllSttfChrgMdlNmr "HVESP5 Lowest Cell State of Charge Module Number: Identifies the location of the module containing SPN 11531 (HVESP5 Lowest Cell State of Charge).This parameter is for one of multiple packs in an HVESS.  If there is only one pack in the system, the H...";
CM_ SG_ 2364660222 HVESP5LwstCllSttfChrgCllNmr "HVESP5 Lowest Cell State of Charge Cell Number: Identifies the location of SPN 11531 (HVESP5 Lowest Cell State of Charge) within SPN 11590 (HVESP5 Lowest Cell State of Charge Module Number).This parameter is for one of multiple packs in an HVESS.  If...";
CM_ SG_ 2364660222 HVESP5HghVltgBsAtvIsltnTstRslts "HVESP5 High-Voltage Bus Active Isolation Test Results: The isolation resistance expressed in Ohms per Volt that resulted from the High-Voltage Bus Active Isolation Test.See SPN 11544 (HVESP5 High-Voltage Bus Active Isolation Test Status) for test sta...";
CM_ SG_ 2364660222 HVESP5HVtBsPssvIstTstRsts "HVESP5 High-Voltage Bus Passive Isolation Test Results: The isolation resistance expressed in Ohms per Volt that resulted from the High-Voltage Bus Passive Isolation Test.See SPN 11545 (HVESP5 High-Voltage Bus Passive Isolation Test Status) for test ...";
CM_ BO_ 2364660478 "High Voltage Energy Storage Pack 5 Data 11";
CM_ SG_ 2364660478 HVESP5BsVltgNgtvtChsssGrndVltg "HVESP5 Bus Voltage Negative to Chassis Ground Voltage: Voltage difference between the most negative terminal of the HVES battery and chassis measured on the hybrid system bus side (not the battery side) of any HVES contained output contactor.  This v...";
CM_ SG_ 2364660478 HVESP5VltgLvlNgtvtChsssGrndVltg "HVESP5 Voltage Level Negative to Chassis Ground Voltage: Voltage difference between the most negative terminal of the HVES battery and chassis measured at the battery side of any HVES contained output contactor.  This voltage may be used for system l...";
CM_ SG_ 2364660478 HVESP5ActualChargeRate "HVESP5 Actual Charge Rate: This signal represents the actual present charge rate of this High Voltage Energy Storage Pack instance.This parameter is for one of multiple packs in an HVESS. If there is only one pack in the system, the HVESS parameters ...";
CM_ BO_ 2364660734 "High Voltage Energy Storage Pack 6 Status 2";
CM_ SG_ 2364660734 HVESP6DshrgPwrLmtDtSttfChrg "HVESP6 Discharge Power Limit Due to State of Charge: Indicates whether or not discharge power of this HVES instance is being limited due to state of charge.This parameter is for one of multiple packs in an HVESS.  If there is only one pack in the sys...";
CM_ SG_ 2364660734 HVESP6DshrgPwrLmtDtBttrTmprtr "HVESP6 Discharge Power Limit Due to Battery Temperature: Indicates whether or not discharge power of this HVES instance is being limited due to battery temperature.This parameter is for one of multiple packs in an HVESS.  If there is only one pack in...";
CM_ SG_ 2364660734 HVESP6DsPwLtDtBttDstCdt "HVESP6 Discharge Power Limit Due to Battery Diagnostic Condition: Indicates whether or not discharge power of this HVES instance is being limited due to a battery diagnostic condition.This parameter is for one of multiple packs in an HVESS.  If there...";
CM_ SG_ 2364660734 HVESP6DshrgPwrLmtDtBttrrCllVltg "HVESP6 Discharge Power Limit Due to Battery or Cell Voltage: Indicates whether or not discharge power of this HVES instance is being limited due to a battery or cell voltage level.This parameter is for one of multiple packs in an HVESS.  If there is ...";
CM_ SG_ 2364660734 HVESP6DshrgPwrLmtDtBttrCrrnt "HVESP6 Discharge Power Limit Due to Battery Current: Indicates whether or not discharge power of this HVES instance is being limited due to battery current.This parameter is for one of multiple packs in an HVESS.  If there is only one pack in the sys...";
CM_ SG_ 2364660734 HVESP6DshrgPwrLmtDtnUndfndCs "HVESP6 Discharge Power Limit Due to an Undefined Cause: Indicates whether or not discharge power of this HVES instance is being limited due to an undefined cause.This parameter is for one of multiple packs in an HVESS.  If there is only one pack in t...";
CM_ SG_ 2364660734 HVESP6ChrgPwrLmtDtSttfChrg "HVESP6 Charge Power Limit Due to State of Charge: Indicates whether or not charge power of this HVES instance is being limited due to state of charge.This parameter is for one of multiple packs in an HVESS.  If there is only one pack in the system, t...";
CM_ SG_ 2364660734 HVESP6ChrgPwrLmtDtBttrTmprtr "HVESP6 Charge Power Limit Due to Battery Temperature: Indicates whether or not charge power of this HVES instance is being limited due to battery temperature.This parameter is for one of multiple packs in an HVESS.  If there is only one pack in the s...";
CM_ SG_ 2364660734 HVESP6CPwLtDtBttDstCdt "HVESP6 Charge Power Limit Due to Battery Diagnostic Condition: Indicates whether or not charge power of this HVES instance is being limited due to a battery diagnostic condition.This parameter is for one of multiple packs in an HVESS.  If there is on...";
CM_ SG_ 2364660734 HVESP6ChrgPwrLmtDtBttrrCllVltg "HVESP6 Charge Power Limit Due to Battery or Cell Voltage: Indicates whether or not charge power of this HVES instance is being limited due to a battery or cell voltage level.This parameter is for one of multiple packs in an HVESS.  If there is only o...";
CM_ SG_ 2364660734 HVESP6ChrgPwrLmtDtBttrCrrnt "HVESP6 Charge Power Limit Due to Battery Current: Indicates whether or not charge power of this HVES instance is being limited due to battery current.This parameter is for one of multiple packs in an HVESS.  If there is only one pack in the system, t...";
CM_ SG_ 2364660734 HVESP6ChrgPwrLmtDtnUndfndCs "HVESP6 Charge Power Limit Due to an Undefined Cause: Indicates whether or not charge power of this HVES instance is being limited due to an undefined cause.This parameter is for one of multiple packs in an HVESS.  If there is only one pack in the sys...";
CM_ BO_ 2364660990 "High Voltage Energy Storage Pack 6 Data 1";
CM_ SG_ 2364660990 HVESP6AvailableDischargePower "HVESP6 Available Discharge Power: The rate at which this High Voltage Energy Storage Pack instance can currently provide energy for propulsion or other uses.This parameter is for one of multiple packs in an HVESS.  If there is only one pack in the sy...";
CM_ SG_ 2364660990 HVESP6AvailableChargePower "HVESP6 Available Charge Power: The rate at which this High Voltage Energy Storage Pack instance can currently receive energy from a regenerative or recharging system.This parameter is for one of multiple packs in an HVESS.  If there is only one pack ...";
CM_ SG_ 2364660990 HVESP6VoltageLevel "HVESP6 Voltage Level: The voltage level of this High Voltage Energy Storage Pack instance. This parameter should be synchronized with SPN 11633 (HVESP6 Current) such that a realized power value can be calculated.  If the HVES component physically con...";
CM_ SG_ 2364660990 HVESP6Current "HVESP6 Current: The current in or out of this High Voltage Energy Storage Pack instance. This parameter should be synchronized with SPN 11632 (HVESP6 Voltage Level) such that a realized power value can be calculated.  This parameter is defined from t...";
CM_ BO_ 2364661246 "High Voltage Energy Storage Pack 6 Data 2";
CM_ SG_ 2364661246 HVESP6FastUpdateStateofCharge "HVESP6 Fast Update State of Charge: Indicates this High Voltage Energy Storage Pack instance state of charge.  0% means no charge remaining, 100% means the system is fully charged in terms of physical limits of this energy storage pack instance.  Acc...";
CM_ SG_ 2364661246 HVESP6HighestCellVoltage "HVESP6 Highest Cell Voltage: The highest voltage level reported by any cell in this High Voltage Energy Storage Pack instance. If a single voltage sensor covers more than one cell, the value in this parameter is for the smallest group of cells measur...";
CM_ SG_ 2364661246 HVESP6LowestCellVoltage "HVESP6 Lowest Cell Voltage: The lowest voltage level reported by any cell in this High Voltage Energy Storage Pack instance. If a single voltage sensor covers more than one cell, the value in this parameter is for the smallest group of cells measured...";
CM_ SG_ 2364661246 HVESP6CllVltgDffrntlStts "HVESP6 Cell Voltage Differential Status: Indicates whether or not the differential between the highest and lowest cell voltages are within acceptable limits, according to this High Voltage Energy Storage Pack instance. The actual voltage differential...";
CM_ BO_ 2364661502 "High Voltage Energy Storage Pack 6 Data 3";
CM_ SG_ 2364661502 HVESP6HighestCellTemperature "HVESP6 Highest Cell Temperature: The highest temperature level reported by any cell in this High Voltage Energy Storage Pack instance.  If a single temperature sensor covers more than one cell, the value in this parameter is for the smallest group of...";
CM_ SG_ 2364661502 HVESP6LowestCellTemperature "HVESP6 Lowest Cell Temperature: The lowest temperature level reported by any cell in this High Voltage Energy Storage Pack instance.  If a single temperature sensor covers more than one cell, the value in this parameter is for the smallest group of c...";
CM_ SG_ 2364661502 HVESP6AverageCellTemperature "HVESP6 Average Cell Temperature: The average temperature level of all cells in this High Voltage Energy Storage Pack instance.This parameter is for one of multiple packs in an HVESS.  If there is only one pack in the system, the HVESS parameters shou...";
CM_ SG_ 2364661502 HVESP6CllTmprtrDffrntlStts "HVESP6 Cell Temperature Differential Status: Indicates whether or not the differential between the highest and lowest cell temperatures are within acceptable limits per this High Voltage Energy Storage Pack instance.  The actual temperature different...";
CM_ BO_ 2364661758 "High Voltage Energy Storage Pack 6 Data 4";
CM_ SG_ 2364661758 HVESP6DischargeCapacity "HVESP6 Discharge Capacity: The amount of stored electrical charge in this High Voltage Energy Storage Pack instance that is available for use by the hybrid system, i.e. “how full is the tank”.  See SPN 11670 (HVESP6 Discharge Energy Capacity) for kil...";
CM_ SG_ 2364661758 HVESP6ChargeCapacity "HVESP6 Charge Capacity: The amount of unused electrical charge storage in this High Voltage Energy Storage Pack instance that is available to be filled by charging, i.e. “how much empty space is remaining in the tank”.  See SPN 11671 (HVESP6 Charge E...";
CM_ SG_ 2364661758 HVESP6CellBalancingCount "HVESP6 Cell Balancing Count: The number of cells that are currently being balanced in this High Voltage Energy Storage Pack instance.This parameter is for one of multiple packs in an HVESS.  If there is only one pack in the system, the HVESS paramete...";
CM_ BO_ 2364662014 "High Voltage Energy Storage Pack 6 Data 5";
CM_ SG_ 2364662014 HVESP6DischargeCurrentLimit "HVESP6 Discharge Current Limit: The maximum permissible current flow out of this High Voltage Energy Storage Pack instance. This parameter is defined from the high voltage energy storage pack's point of view.A negative value represents current flowin...";
CM_ SG_ 2364662014 HVESP6ChargeCurrentLimit "HVESP6 Charge Current Limit: The maximum permissible current flow into this High Voltage Energy Storage Pack instance. This parameter is defined from the high voltage energy storage pack's point of view.A positive value represents current flowing int...";
CM_ SG_ 2364662014 HVESP6LowestCellStateofCharge "HVESP6 Lowest Cell State of Charge: Indicates the state of charge of the lowest-charged cell in this High Voltage Energy Storage Pack instance.  0% means no charge remaining, 100% means the cell is fully charged.   If a single state of charge value c...";
CM_ SG_ 2364662014 HVESP6HighestCellStateofCharge "HVESP6 Highest Cell State of Charge: Indicates the state of charge of the highest-charged cell in this High Voltage Energy Storage Pack instance.  0% means no charge remaining, 100% means the cell is fully charged.  If a single state of charge value ...";
CM_ BO_ 2364662270 "High Voltage Energy Storage Pack 6 Data 6";
CM_ SG_ 2364662270 HVESP6BusVoltage "HVESP6 Bus Voltage: The voltage level of the high voltage bus, as measured by this High Voltage Energy Storage Pack instance on the bus side (not the battery side) of its contactors.This parameter is for one of multiple packs in an HVESS.  If there i...";
CM_ SG_ 2364662270 HVESP6IgnitionVoltage "HVESP6 Ignition Voltage: The voltage level at the ignition input of this High Voltage Energy Storage Pack controller.This parameter is for one of multiple packs in an HVESS.  If there is only one pack in the system, the HVESS parameters should be use...";
CM_ SG_ 2364662270 HVESP6IntakeCoolantTemperature "HVESP6 Intake Coolant Temperature: The temperature of liquid coolant as it enters this High Voltage Energy Storage Pack instance.This parameter is for one of multiple packs in an HVESS.  If there is only one pack in the system, the HVESS parameters s...";
CM_ SG_ 2364662270 HVESP6OutletCoolantTemperature "HVESP6 Outlet Coolant Temperature: The temperature of liquid coolant as it exits this High Voltage Energy Storage Pack instance.This parameter is for one of multiple packs in an HVESS.  If there is only one pack in the system, the HVESS parameters sh...";
CM_ SG_ 2364662270 HVESP6ElectronicsTemperature "HVESP6 Electronics Temperature: The temperature of the electronics or control modules in this High Voltage Energy Storage Pack instance.  If there are multiple temperature sensors then this parameter would be set to the maximum sensor reading.This pa...";
CM_ SG_ 2364662270 HVESP6Temperature "HVESP6 Temperature: The temperature of this High Voltage Energy Storage Pack instance. The value may be determined from a unique sensor specifically for this purpose, or by aggregating various temperature sensor readings within the pack.This paramete...";
CM_ BO_ 2364662526 "High Voltage Energy Storage Pack 6 Status 1";
CM_ SG_ 2364662526 HVESP6HghVltgBsPstvCnttrStt "HVESP6 High-Voltage Bus (Positive) Contactor State: Position of this High Voltage Energy Storage Pack instance positive side bus contactor.  When this contactor is closed, the positive side of this HVES instance is connected to the positive side of t...";
CM_ SG_ 2364662526 HVESP6HghVltgBsNgtvCnttrStt "HVESP6 High-Voltage Bus (Negative) Contactor State: Position of this High Voltage Energy Storage Pack instance negative side bus contactor.  When this contactor is closed, the negative side of this HVES instance is connected to the negative side of t...";
CM_ SG_ 2364662526 HVESP6HghVltgBsDsnntFrwrnng "HVESP6 High-Voltage Bus Disconnect Forewarning: Indicates that this High Voltage Energy Storage Pack instance is about to disconnect from the high voltage bus due to unacceptable conditions.This parameter is for one of multiple packs in an HVESS. If ...";
CM_ SG_ 2364662526 HVESP6HghVltgBsPrChrgRlStt "HVESP6 High-Voltage Bus Pre-Charge Relay State: Position of the high-voltage bus contactor pre-charge relay.  When this relay is closed, this High Voltage Energy Storage Pack instance is bringing the high-voltage bus up to its operating level.This pa...";
CM_ SG_ 2364662526 HVESP6CntrfPkCnttrStt "HVESP6 Center of Pack Contactor State: Position of the center high-voltage contactor.  When this contactor is closed, the positive half of this High Voltage Energy Storage Pack instance is connected to the negative half.  If a system controls the pos...";
CM_ SG_ 2364662526 HVESP6HghVltgBsAtvIsltnTstStts "HVESP6 High-Voltage Bus Active Isolation Test Status: Status of the high-voltage bus electrical active isolation test as performed by this High Voltage Energy Storage Pack instance.This parameter is for one of multiple packs in an HVESS. If there is ...";
CM_ SG_ 2364662526 HVESP6HghVltgBsPssvIsltnTstStts "HVESP6 High-Voltage Bus Passive Isolation Test Status: Status of the high-voltage bus electrical passive isolation test as performed by this High Voltage Energy Storage Pack instance.This parameter is for one of multiple packs in an HVESS. If there i...";
CM_ SG_ 2364662526 HVESP6HVILStatus "HVESP6 HVIL Status: Status of the High Voltage Interlock Loop from the viewpoint of this High Voltage Energy Storage Pack instance.This parameter is for one of multiple packs in an HVESS. If there is only one pack in the system, the HVESS parameters ...";
CM_ SG_ 2364662526 HVESP6InertiaSwitchStatus "HVESP6 Inertia Switch Status: Switch indicating that an impact has been sensed by this High Voltage Energy Storage Pack instance. The impact indication may require action by another controller, or by this HVES instance itself.  For example, a control...";
CM_ SG_ 2364662526 HVESP6StateofChargeStatus "HVESP6 State of Charge Status: Status of this High Voltage Energy Storage Pack instance State of Charge (SOC).  Note:  A given HVES controller may not support all of the states.This parameter is for one of multiple packs in an HVESS.  If there is onl...";
CM_ SG_ 2364662526 HVESP6CellBalanceStatus "HVESP6 Cell Balance Status: Indicates whether or not the cells in this High Voltage Energy Storage Pack instance are balanced.This parameter is for one of multiple packs in an HVESS.  If there is only one pack in the system, the HVESS parameters shou...";
CM_ SG_ 2364662526 HVESP6CellBalancingActive "HVESP6 Cell Balancing Active: Indicates whether or not the cells in this High Voltage Energy Storage Pack instance are currently being balanced.This parameter is for one of multiple packs in an HVESS.  If there is only one pack in the system, the HVE...";
CM_ SG_ 2364662526 HVESP6InternalChargerStatus "HVESP6 Internal Charger Status: Indicates that the charger in this HVES instance is on.  External chargers may use the External Energy Source Connection Status (SPN 7898) and related SPs.This parameter is for one of multiple packs in an HVESS. If the...";
CM_ SG_ 2364662526 HVESP6HghVltgBsCnntnStts "HVESP6 High-Voltage Bus Connection Status: This parameter provides high level feedback on this High Voltage Energy Storage Pack instance high voltage bus connection.  For specific contactor information, see SPN 11655 (HVESP6 High-Voltage Bus (Positiv...";
CM_ SG_ 2364662526 HVESP6OperationalStatus "HVESP6 Operational Status: Provides feedback on where this High Voltage Energy Storage Pack instance is in its operating spectrum, and includes feedback in response to the Operation Consent [i.e. SPN 11615 (HVESP6 Operation Consent)] and Power Down C...";
CM_ SG_ 2364662526 HVESP6Status1Counter "HVESP6 Status 1 Counter: The message counter is used to detect situations where the transmitting ECU malfunction repeats the same frame all the time. The receiver of the information may use the counter parameter to detect this situation. The transmit...";
CM_ SG_ 2364662526 HVESP6Status1CRC "HVESP6 Status 1 CRC: The CRC is defined as follows: • Length: 8 bits • Polynomial: x^8+x^5+x^3+x^2+x+1 • Initial Value: FFh • Input Data Reflection: Not reflected • Result Data Reflection: Not reflected • XOR value: FFhSAE makes no claim of the funct...";
CM_ BO_ 2364662782 "High Voltage Energy Storage Pack 6 Data 7";
CM_ SG_ 2364662782 HVESP6DischargeEnergyCapacity "HVESP6 Discharge Energy Capacity: The amount of stored electrical energy in this High Voltage Energy Storage Pack instance that is available for use by the hybrid system, i.e. “how full is the tank”.  See SPN 11642 (HVESP6 Discharge Capacity) for Amp...";
CM_ SG_ 2364662782 HVESP6ChargeEnergyCapacity "HVESP6 Charge Energy Capacity: The amount of unused electrical energy storage available to be filled by charging this High Voltage Energy Storage Pack instance, i.e. “how much empty space is remaining in the tank”.  See SPN 11643 (HVESP6 Charge Capac...";
CM_ SG_ 2364662782 HVESP6MaximumChargeVoltageLimit "HVESP6 Maximum Charge Voltage Limit: The maximum voltage level not to be exceeded while charging this High Voltage Energy Storage Pack instance.  If this parameter is not supported, the maximum charge voltage should be limited to SPN 11714 (HVESP6 Re...";
CM_ BO_ 2364663038 "High Voltage Energy Storage Pack 6 Module Status 1";
CM_ SG_ 2364663038 HVESP6Module1OperationalStatus "HVESP6 Module 1 Operational Status: Operational Status of Module 1 in this High Voltage Energy Storage Pack Instance.  Not Operational is used when the module is initializing or not able to function (e.g. internal module level monitors have failed). ...";
CM_ SG_ 2364663038 HVESP6Module2OperationalStatus "HVESP6 Module 2 Operational Status: Operational Status of Module 2 in this High Voltage Energy Storage Pack Instance.  Not Operational is used when the module is initializing or not able to function (e.g. internal module level monitors have failed). ...";
CM_ SG_ 2364663038 HVESP6Module3OperationalStatus "HVESP6 Module 3 Operational Status: Operational Status of Module 3 in this High Voltage Energy Storage Pack Instance.  Not Operational is used when the module is initializing or not able to function (e.g. internal module level monitors have failed). ...";
CM_ SG_ 2364663038 HVESP6Module4OperationalStatus "HVESP6 Module 4 Operational Status: Operational Status of Module 4 in this High Voltage Energy Storage Pack Instance.  Not Operational is used when the module is initializing or not able to function (e.g. internal module level monitors have failed). ...";
CM_ SG_ 2364663038 HVESP6Module5OperationalStatus "HVESP6 Module 5 Operational Status: Operational Status of Module 5 in this High Voltage Energy Storage Pack Instance.  Not Operational is used when the module is initializing or not able to function (e.g. internal module level monitors have failed). ...";
CM_ SG_ 2364663038 HVESP6Module6OperationalStatus "HVESP6 Module 6 Operational Status: Operational Status of Module 6 in this High Voltage Energy Storage Pack Instance.  Not Operational is used when the module is initializing or not able to function (e.g. internal module level monitors have failed). ...";
CM_ SG_ 2364663038 HVESP6Module7OperationalStatus "HVESP6 Module 7 Operational Status: Operational Status of Module 7 in this High Voltage Energy Storage Pack Instance.  Not Operational is used when the module is initializing or not able to function (e.g. internal module level monitors have failed). ...";
CM_ SG_ 2364663038 HVESP6Module8OperationalStatus "HVESP6 Module 8 Operational Status: Operational Status of Module 8 in this High Voltage Energy Storage Pack Instance.  Not Operational is used when the module is initializing or not able to function (e.g. internal module level monitors have failed). ...";
CM_ SG_ 2364663038 HVESP6Module9OperationalStatus "HVESP6 Module 9 Operational Status: Operational Status of Module 9 in this High Voltage Energy Storage Pack Instance.  Not Operational is used when the module is initializing or not able to function (e.g. internal module level monitors have failed). ...";
CM_ SG_ 2364663038 HVESP6Module10OperationalStatus "HVESP6 Module 10 Operational Status: Operational Status of Module 10 in this High Voltage Energy Storage Pack Instance.  Not Operational is used when the module is initializing or not able to function (e.g. internal module level monitors have failed)...";
CM_ SG_ 2364663038 HVESP6Module11OperationalStatus "HVESP6 Module 11 Operational Status: Operational Status of Module 11 in this High Voltage Energy Storage Pack Instance.  Not Operational is used when the module is initializing or not able to function (e.g. internal module level monitors have failed)...";
CM_ SG_ 2364663038 HVESP6Module12OperationalStatus "HVESP6 Module 12 Operational Status: Operational Status of Module 12 in this High Voltage Energy Storage Pack Instance.  Not Operational is used when the module is initializing or not able to function (e.g. internal module level monitors have failed)...";
CM_ SG_ 2364663038 HVESP6Module13OperationalStatus "HVESP6 Module 13 Operational Status: Operational Status of Module 13 in this High Voltage Energy Storage Pack Instance.  Not Operational is used when the module is initializing or not able to function (e.g. internal module level monitors have failed)...";
CM_ SG_ 2364663038 HVESP6Module14OperationalStatus "HVESP6 Module 14 Operational Status: Operational Status of Module 14 in this High Voltage Energy Storage Pack Instance.  Not Operational is used when the module is initializing or not able to function (e.g. internal module level monitors have failed)...";
CM_ SG_ 2364663038 HVESP6Module15OperationalStatus "HVESP6 Module 15 Operational Status: Operational Status of Module 15 in this High Voltage Energy Storage Pack Instance.  Not Operational is used when the module is initializing or not able to function (e.g. internal module level monitors have failed)...";
CM_ SG_ 2364663038 HVESP6Module16OperationalStatus "HVESP6 Module 16 Operational Status: Operational Status of Module 16 in this High Voltage Energy Storage Pack Instance.  Not Operational is used when the module is initializing or not able to function (e.g. internal module level monitors have failed)...";
CM_ SG_ 2364663038 HVESP6Module17OperationalStatus "HVESP6 Module 17 Operational Status: Operational Status of Module 17 in this High Voltage Energy Storage System (or Pack 1 in systems with only one pack).  Not Operational is used when the module is initializing or not able to function (e.g. internal...";
CM_ SG_ 2364663038 HVESP6Module18OperationalStatus "HVESP6 Module 18 Operational Status: Operational Status of Module 18 in this High Voltage Energy Storage System (or Pack 1 in systems with only one pack).  Not Operational is used when the module is initializing or not able to function (e.g. internal...";
CM_ SG_ 2364663038 HVESP6Module19OperationalStatus "HVESP6 Module 19 Operational Status: Operational Status of Module 19 in this High Voltage Energy Storage System (or Pack 1 in systems with only one pack).  Not Operational is used when the module is initializing or not able to function (e.g. internal...";
CM_ SG_ 2364663038 HVESP6Module20OperationalStatus "HVESP6 Module 20 Operational Status: Operational Status of Module 20 in this High Voltage Energy Storage System (or Pack 1 in systems with only one pack).  Not Operational is used when the module is initializing or not able to function (e.g. internal...";
CM_ SG_ 2364663038 HVESP6Module21OperationalStatus "HVESP6 Module 21 Operational Status: Operational Status of Module 21 in this High Voltage Energy Storage System (or Pack 1 in systems with only one pack).  Not Operational is used when the module is initializing or not able to function (e.g. internal...";
CM_ SG_ 2364663038 HVESP6Module22OperationalStatus "HVESP6 Module 22 Operational Status: Operational Status of Module 22 in this High Voltage Energy Storage System (or Pack 1 in systems with only one pack).  Not Operational is used when the module is initializing or not able to function (e.g. internal...";
CM_ SG_ 2364663038 HVESP6Module23OperationalStatus "HVESP6 Module 23 Operational Status: Operational Status of Module 23 in this High Voltage Energy Storage System (or Pack 1 in systems with only one pack).  Not Operational is used when the module is initializing or not able to function (e.g. internal...";
CM_ SG_ 2364663038 HVESP6Module24OperationalStatus "HVESP6 Module 24 Operational Status: Operational Status of Module 24 in this High Voltage Energy Storage System (or Pack 1 in systems with only one pack).  Not Operational is used when the module is initializing or not able to function (e.g. internal...";
CM_ SG_ 2364663038 HVESP6Module25OperationalStatus "HVESP6 Module 25 Operational Status: Operational Status of Module 25 in this High Voltage Energy Storage System (or Pack 1 in systems with only one pack).  Not Operational is used when the module is initializing or not able to function (e.g. internal...";
CM_ SG_ 2364663038 HVESP6Module26OperationalStatus "HVESP6 Module 26 Operational Status: Operational Status of Module 26 in this High Voltage Energy Storage System (or Pack 1 in systems with only one pack).  Not Operational is used when the module is initializing or not able to function (e.g. internal...";
CM_ SG_ 2364663038 HVESP6Module27OperationalStatus "HVESP6 Module 27 Operational Status: Operational Status of Module 27 in this High Voltage Energy Storage System (or Pack 1 in systems with only one pack).  Not Operational is used when the module is initializing or not able to function (e.g. internal...";
CM_ SG_ 2364663038 HVESP6Module28OperationalStatus "HVESP6 Module 28 Operational Status: Operational Status of Module 28 in this High Voltage Energy Storage System (or Pack 1 in systems with only one pack).  Not Operational is used when the module is initializing or not able to function (e.g. internal...";
CM_ SG_ 2364663038 HVESP6Module29OperationalStatus "HVESP6 Module 29 Operational Status: Operational Status of Module 29 in this High Voltage Energy Storage System (or Pack 1 in systems with only one pack).  Not Operational is used when the module is initializing or not able to function (e.g. internal...";
CM_ SG_ 2364663038 HVESP6Module30OperationalStatus "HVESP6 Module 30 Operational Status: Operational Status of Module 30 in this High Voltage Energy Storage System (or Pack 1 in systems with only one pack).  Not Operational is used when the module is initializing or not able to function (e.g. internal...";
CM_ SG_ 2364663038 HVESP6Module31OperationalStatus "HVESP6 Module 31 Operational Status: Operational Status of Module 31 in this High Voltage Energy Storage System (or Pack 1 in systems with only one pack).  Not Operational is used when the module is initializing or not able to function (e.g. internal...";
CM_ SG_ 2364663038 HVESP6Module32OperationalStatus "HVESP6 Module 32 Operational Status: Operational Status of Module 32 in this High Voltage Energy Storage System (or Pack 1 in systems with only one pack).  Not Operational is used when the module is initializing or not able to function (e.g. internal...";
CM_ BO_ 2364663294 "High Voltage Energy Storage Pack 6 Thermal Management System Status 1";
CM_ SG_ 2364663294 HVESP6ThrmlMngmntSstmSLIInptPwr "HVESP6 Thermal Management System SLI Input Power: This is the low-voltage power consumed by this HVES Thermal Management System (TMS).This parameter is for one of multiple packs in an HVESS.  If there is only one pack in the system, the HVESS paramet...";
CM_ SG_ 2364663294 HVESP6TMtSstHVtIptPw "HVESP6 Thermal Management System High-Voltage Input Power: This is the high-voltage power consumed by this HVES Thermal Management System (TMS).This parameter is for one of multiple packs in an HVESS.  If there is only one pack in the system, the HVE...";
CM_ SG_ 2364663294 HVESP6ThrmlMngmntSstmCmprssrSpd "HVESP6 Thermal Management System Compressor Speed: When this High Voltage Energy Storage Pack Thermal Management System is equipped with an active cooling system (e.g. air conditioner), this is the Compressor Speed.This parameter is for one of multip...";
CM_ SG_ 2364663294 HVESP6ThrmlMngmntSstmRltvHmdt "HVESP6 Thermal Management System Relative Humidty: When this High Voltage Energy Storage Pack Thermal Management System is equipped with a relative humidity sensor, this is the  measured Relative Humidity.This parameter is for one of multiple packs i...";
CM_ SG_ 2364663294 HVESP6ThrmlMngmntSstmHtrStts "HVESP6 Thermal Management System Heater Status: The state of this High Voltage Energy Storage Pack heaterThis parameter is for one of multiple packs in an HVESS.  If there is only one pack in the system, the HVESS parameters should be used. If there ...";
CM_ SG_ 2364663294 HVESP6ThrmlMngmntSstmHVILStts "HVESP6 Thermal Management System HVIL Status: In multiple HVES configurations, this is the status of the High Voltage Interlock Loop from the viewpoint of this Thermal Management System.00b = HVIL Closed01b = HVIL Open10b = Error11b = Not AvailableTh...";
CM_ SG_ 2364663294 HVESP6ThrmlMngmntSstmMd "HVESP6 Thermal Management System Mode: Indicates the operating mode of the Thermal Management System.  The heat transfer medium may be (e.g. liquid or air).  The cooling system may be fans, liquid coolant, or a combination of mediums.  The system may...";
CM_ SG_ 2364663294 HVESP6ThrmlMngmntSstmClntLvl "HVESP6 Thermal Management System Coolant Level: Indicates the coolant level in this HVES Thermal Management System (TMS).This parameter is for one of multiple packs in an HVESS.  If there is only one pack in the system, the HVESS parameters should be...";
CM_ BO_ 2364663550 "High Voltage Energy Storage Pack 6 Data 8";
CM_ SG_ 2364663550 HVESP6HghstCllVltgMdlNmr "HVESP6 Highest Cell Voltage Module Number: Identifies the location of the module containing SPN 11635 (HVESP6 Highest Cell Voltage).This parameter is for one of multiple packs in an HVESS.  If there is only one pack in the system, the HVESS parameter...";
CM_ SG_ 2364663550 HVESP6HghstCllVltgCllNmr "HVESP6 Highest Cell Voltage Cell Number: Identifies the location of SPN 11635 (HVESP6 Highest Cell Voltage) within SPN 11695 (HVESP6 Highest Cell Voltage Module Number).This parameter is for one of multiple packs in an HVESS.  If there is only one pa...";
CM_ SG_ 2364663550 HVESP6LwstCllVltgMdlNmr "HVESP6 Lowest Cell Voltage Module Number: Identifies the location of the module containing SPN 11636 (HVESP6 Lowest Cell Voltage).This parameter is for one of multiple packs in an HVESS.  If there is only one pack in the system, the HVESS parameters ...";
CM_ SG_ 2364663550 HVESP6LwstCllVltgCllNmr "HVESP6 Lowest Cell Voltage Cell Number: Identifies the location of SPN 11636 (HVESP6 Lowest Cell Voltage) within SPN 11697 (HVESP6 Lowest Cell Voltage Module Number).This parameter is for one of multiple packs in an HVESS.  If there is only one pack ...";
CM_ SG_ 2364663550 HVESP6AverageCellVoltage "HVESP6 Average Cell Voltage: The average cell voltage in this High Voltage Energy Storage Pack instance.This parameter is for one of multiple packs in an HVESS.  If there is only one pack in the system, the HVESS parameters should be used. If there a...";
CM_ BO_ 2364663806 "High Voltage Energy Storage Pack 6 Data 9";
CM_ SG_ 2364663806 HVESP6HghstCllTmprtrMdlNmr "HVESP6 Highest Cell Temperature Module Number: Identifies the location of the module containing SPN 11638 (HVESP6 Highest Cell Temperature).This parameter is for one of multiple packs in an HVESS.  If there is only one pack in the system, the HVESS p...";
CM_ SG_ 2364663806 HVESP6HghstCllTmprtrCllNmr "HVESP6 Highest Cell Temperature Cell Number: Identifies the location of SPN 11638 (HVESP6 Highest Cell Temperature) within SPN 11700 (HVESP6 Highest Cell Temperature Module Number).This parameter is for one of multiple packs in an HVESS.  If there is...";
CM_ SG_ 2364663806 HVESP6LwstCllTmprtrMdlNmr "HVESP6 Lowest Cell Temperature Module Number: Identifies the location of the module containing SPN 11639 (HVESP6 Lowest Cell Temperature).This parameter is for one of multiple packs in an HVESS.  If there is only one pack in the system, the HVESS par...";
CM_ SG_ 2364663806 HVESP6LwstCllTmprtrCllNmr "HVESP6 Lowest Cell Temperature Cell Number: Identifies the location of SPN 11639 (HVESP6 Lowest Cell Temperature) within SPN 11702 (HVESP6 Lowest Cell Temperature Module Number).This parameter is for one of multiple packs in an HVESS.  If there is on...";
CM_ BO_ 2364664062 "High Voltage Energy Storage Pack 6 Data 10";
CM_ SG_ 2364664062 HVESP6HghstCllSttfChrgMdlNmr "HVESP6 Highest Cell State of Charge Module Number: Identifies the location of the module containing SPN 11648 (HVESP6 Highest Cell State of Charge).This parameter is for one of multiple packs in an HVESS.  If there is only one pack in the system, the...";
CM_ SG_ 2364664062 HVESP6HghstCllSttfChrgCllNmr "HVESP6 Highest Cell State of Charge Cell Number: Identifies the location of SPN 11648 (HVESP6 Highest Cell State of Charge) within SPN 11704 (HVESP6 Highest Cell State of Charge Module Number).This parameter is for one of multiple packs in an HVESS. ...";
CM_ SG_ 2364664062 HVESP6LwstCllSttfChrgMdlNmr "HVESP6 Lowest Cell State of Charge Module Number: Identifies the location of the module containing SPN 11647 (HVESP6 Lowest Cell State of Charge).This parameter is for one of multiple packs in an HVESS.  If there is only one pack in the system, the H...";
CM_ SG_ 2364664062 HVESP6LwstCllSttfChrgCllNmr "HVESP6 Lowest Cell State of Charge Cell Number: Identifies the location of SPN 11647 (HVESP6 Lowest Cell State of Charge) within SPN 11706 (HVESP6 Lowest Cell State of Charge Module Number).This parameter is for one of multiple packs in an HVESS.  If...";
CM_ SG_ 2364664062 HVESP6HghVltgBsAtvIsltnTstRslts "HVESP6 High-Voltage Bus Active Isolation Test Results: The isolation resistance expressed in Ohms per Volt that resulted from the High-Voltage Bus Active Isolation Test.See SPN 11660 (HVESP6 High-Voltage Bus Active Isolation Test Status) for test sta...";
CM_ SG_ 2364664062 HVESP6HVtBsPssvIstTstRsts "HVESP6 High-Voltage Bus Passive Isolation Test Results: The isolation resistance expressed in Ohms per Volt that resulted from the High-Voltage Bus Passive Isolation Test.See SPN 11661 (HVESP6 High-Voltage Bus Passive Isolation Test Status) for test ...";
CM_ BO_ 2364664318 "High Voltage Energy Storage Pack 6 Data 11";
CM_ SG_ 2364664318 HVESP6BsVltgNgtvtChsssGrndVltg "HVESP6 Bus Voltage Negative to Chassis Ground Voltage: Voltage difference between the most negative terminal of the HVES battery and chassis measured on the hybrid system bus side (not the battery side) of any HVES contained output contactor.  This v...";
CM_ SG_ 2364664318 HVESP6VltgLvlNgtvtChsssGrndVltg "HVESP6 Voltage Level Negative to Chassis Ground Voltage: Voltage difference between the most negative terminal of the HVES battery and chassis measured at the battery side of any HVES contained output contactor.  This voltage may be used for system l...";
CM_ SG_ 2364664318 HVESP6ActualChargeRate "HVESP6 Actual Charge Rate: This signal represents the actual present charge rate of this High Voltage Energy Storage Pack instance.This parameter is for one of multiple packs in an HVESS. If there is only one pack in the system, the HVESS parameters ...";
CM_ BO_ 2364664574 "Motor/Generator 3 Inverter Mode Feedback 1";
CM_ SG_ 2364664574 MtrGnrtr3InvrtrMdFdk1CRC "Motor/Generator 3 Inverter Mode Feedback 1 CRC: The CRC is defined as follows:• Length: 8 bits• Polynomial: x^8+x^5+x^3+x^2+x+1• Initial Value: FFh• Input Data Reflection: Not reflected• Result Data Reflection: Not reflected• XOR value: FFhSAE makes ...";
CM_ SG_ 2364664574 MtrGnrtr3InvrtrMdFdk1Cntr "Motor/Generator 3 Inverter Mode Feedback 1 Counter: The message counter is used to detect situations where the transmitting ECU malfunction repeats the same frame all the time. The receiver of the information may use the counter parameter to detect t...";
CM_ SG_ 2364664574 MtrGnrtr3InvrtrCntrlLmtsOvrrdMd "Motor/Generator 3 Inverter Control Limits Override Mode: During normal operation this will have the same value as SPN 11810 [Control Limits Request Override Mode].  0 = Operating limits are not overridden.  If a limit was previously active, then it h...";
CM_ SG_ 2364664574 MtrGnrtr3InvrtrCntrlStpntMd "Motor/Generator 3 Inverter Control Setpoint Mode: Reports the inverter mode (See SPN 11813 [Control Setpoint Mode Request] for requested mode).Passive modes:  0 = Powered On - the inverter is commanded to be powered on and able to communicate, but th...";
CM_ SG_ 2364664574 MtrGnrtr3InvrtrHVILStts "Motor/Generator 3 Inverter HVIL Status: Reports the High Voltage Interlock Loop (HVIL) state.00b = HVIL Closed01b = HVIL Open10b = Error11b = Not Available";
CM_ BO_ 2565991422 "Motor/Generator 3 Inverter Limits Active Power";
CM_ SG_ 2565991422 MtrGnrtr3InvrtrLmtsAtvPwrCRC "Motor/Generator 3 Inverter Limits Active Power CRC: The CRC is defined as follows:• Length: 8 bits• Polynomial: x^8+x^5+x^3+x^2+x+1• Initial Value: FFh• Input Data Reflection: Not reflected• Result Data Reflection: Not reflected• XOR value: FFhSAE ma...";
CM_ SG_ 2565991422 MtrGnrtr3InvrtrLmtsAtvPwrCntr "Motor/Generator 3 Inverter Limits Active Power Counter: The message counter is used to detect situations where the transmitting ECU malfunction repeats the same frame all the time. The receiver of the information may use the counter parameter to dete...";
CM_ SG_ 2565991422 MtGt3IvtLtsAtvMPwMx "Motor/Generator 3 Inverter Limits Active Mechanical Power Maximum: The inverter keeps the mechanical motor power below this value.   This limit may be set in response to a Limits Request or determined by the inverter based on operating conditions.Ref...";
CM_ SG_ 2565991422 MtGt3IvtLtsAtvMPwM "Motor/Generator 3 Inverter Limits Active Mechanical Power Minimum: The inverter keeps the mechanical motor power above this value.   This limit may be set in response to a Limits Request or determined by the inverter based on operating conditions.Ref...";
CM_ SG_ 2565991422 MtGt3IvtLtsAtvDCSdPwMx "Motor/Generator 3 Inverter Limits Active DC Side Power Maximum: The inverter keeps the DC Side power below this value.   This limit may be set in response to a Limits Request or determined by the inverter based on operating conditions.Refer to SPN 11...";
CM_ SG_ 2565991422 MtGt3IvtLtsAtvDCSdPwM "Motor/Generator 3 Inverter Limits Active DC Side Power Minimum: The inverter keeps the DC side power above this value.   This limit may be set in response to a Limits Request or determined by the inverter based on operating conditions.Refer to SPN 11...";
CM_ BO_ 2565991678 "Motor/Generator 3 Inverter Limits Active Mechanical";
CM_ SG_ 2565991678 MtrGnrtr3InvrtrLmtsAtvMhnlCRC "Motor/Generator 3 Inverter Limits Active Mechanical CRC: The CRC is defined as follows:• Length: 8 bits• Polynomial: x^8+x^5+x^3+x^2+x+1• Initial Value: FFh• Input Data Reflection: Not reflected• Result Data Reflection: Not reflected• XOR value: FFhS...";
CM_ SG_ 2565991678 MtrGnrtr3InvrtrLmtsAtvMhnlCntr "Motor/Generator 3 Inverter Limits Active Mechanical Counter: The message counter is used to detect situations where the transmitting ECU malfunction repeats the same frame all the time. The receiver of the information may use the counter parameter to...";
CM_ SG_ 2565991678 MtrGnrtr3InvrtrLmtsAtvTrqMxmm "Motor/Generator 3 Inverter Limits Active Torque Maximum: The inverter keeps the motor torque below this value.  This limit may be set in response to a Limits Request or determined by the inverter based on operating conditions.Refer to SPN 11821 [Refe...";
CM_ SG_ 2565991678 MtrGnrtr3InvrtrLmtsAtvTrqMnmm "Motor/Generator 3 Inverter Limits Active Torque Minimum: The inverter keeps the motor torque above this value.  This limit may be set in response to a Limits Request or determined by the inverter based on operating conditions.Refer to SPN 11821 [Refe...";
CM_ SG_ 2565991678 MtrGnrtr3InvrtrLmtsAtvSpdMxmm "Motor/Generator 3 Inverter Limits Active Speed Maximum: The inverter keeps the motor speed below this value.  This limit may be set in response to a Limits Request or determined by the inverter based on operating conditions.Refer to SPN 11822 [Refere...";
CM_ SG_ 2565991678 MtrGnrtr3InvrtrLmtsAtvSpdMnmm "Motor/Generator 3 Inverter Limits Active Speed Minimum: The inverter keeps the motor Speed above this value.  This limit may be set in response to a Limits Request or determined by the inverter based on operating conditions.Refer to SPN 11822 [Refere...";
CM_ BO_ 2565991934 "Motor/Generator 3 Inverter Limits Active DC Side";
CM_ SG_ 2565991934 MtrGnrtr3InvrtrLmtsAtvDCSdCRC "Motor/Generator 3 Inverter Limits Active DC Side CRC: The CRC is defined as follows:• Length: 8 bits• Polynomial: x^8+x^5+x^3+x^2+x+1• Initial Value: FFh• Input Data Reflection: Not reflected• Result Data Reflection: Not reflected• XOR value: FFhSAE ...";
CM_ SG_ 2565991934 MtrGnrtr3InvrtrLmtsAtvDCSdCntr "Motor/Generator 3 Inverter Limits Active DC Side Counter: The message counter is used to detect situations where the transmitting ECU malfunction repeats the same frame all the time. The receiver of the information may use the counter parameter to de...";
CM_ SG_ 2565991934 MtGt3IvtLtsAtvDCSdVtMx "Motor/Generator 3 Inverter Limits Active DC Side Voltage Maximum: The inverter keeps the DC side voltage below this value.  This limit may be set in response to a Limits Request or determined by the inverter based on operating conditions.Refer to SPN...";
CM_ SG_ 2565991934 MtGt3IvtLtsAtvDCSdVtM "Motor/Generator 3 Inverter Limits Active DC Side Voltage Minimum: The inverter keeps the DC side voltage above this value.  This limit may be set in response to a Limits Request or determined by the inverter based on operating conditions.Refer to SPN...";
CM_ SG_ 2565991934 MtGt3IvtLtsAtvDCSdCtMx "Motor/Generator 3 Inverter Limits Active DC Side Current Maximum: The inverter keeps the DC side current below this value.  This limit may be set in response to a Limits Request or determined by the inverter based on operating conditions. Refer to SP...";
CM_ SG_ 2565991934 MtGt3IvtLtsAtvDCSdCtM "Motor/Generator 3 Inverter Limits Active DC Side Current Minimum: The inverter keeps the DC side current above this value.  This limit may be set in response to a Limits Request or determined by the inverter based on operating conditions.Refer to SPN...";
CM_ BO_ 2565992190 "Motor/Generator 3 Inverter Low Voltage";
CM_ SG_ 2565992190 MtrGnrtr3InvrtrSwthdIgntnVltg "Motor/Generator 3 Inverter Switched Ignition Voltage: Switched Ignition voltage supplied to this instance of the inverter controller.";
CM_ SG_ 2565992190 MtrGnrtr3InvrtrUnswthdSLIVltg "Motor/Generator 3 Inverter Unswitched SLI Voltage: Continuously supplied SLI power to this instance of the inverter controller.";
CM_ BO_ 2565992446 "Motor/Generator 3 Inverter Status 2";
CM_ SG_ 2565992446 MtrGnrtr3InvrtrStts2CRC "Motor/Generator 3 Inverter Status 2 CRC: The CRC is defined as follows:• Length: 8 bits• Polynomial: x^8+x^5+x^3+x^2+x+1• Initial Value: FFh• Input Data Reflection: Not reflected• Result Data Reflection: Not reflected• XOR value: FFhSAE makes no clai...";
CM_ SG_ 2565992446 MtrGnrtr3InvrtrStts2Cntr "Motor/Generator 3 Inverter Status 2 Counter: The message counter is used to detect situations where the transmitting ECU malfunction repeats the same frame all the time. The receiver of the information may use the counter parameter to detect this sit...";
CM_ SG_ 2565992446 MtrGnrtr3AvllMxmmTrq "Motor/Generator 3 Available Maximum Torque: This is an estimate of the maximum available motor torque including active deratings at the present motor speed.  This refers to the motor rotor output and excludes any gearbox that may be attached to the m...";
CM_ SG_ 2565992446 MtrGnrtr3AvllMnmmTrq "Motor/Generator 3 Available Minimum Torque: This is an estimate of the minimum available motor torque including active deratings at the present motor speed.  This refers to the motor rotor output and excludes any gearbox that may be attached to the m...";
CM_ BO_ 2565992702 "Motor/Generator 3 Inverter Rate Limits Active 1";
CM_ SG_ 2565992702 MtrGnrtr3InvrtrRtLmtsAtv1CRC "Motor/Generator 3 Inverter Rate Limits Active 1 CRC: The CRC is defined as follows:• Length: 8 bits• Polynomial: x^8+x^5+x^3+x^2+x+1• Initial Value: FFh• Input Data Reflection: Not reflected• Result Data Reflection: Not reflected• XOR value: FFhSAE m...";
CM_ SG_ 2565992702 MtrGnrtr3InvrtrRtLmtsAtv1Cntr "Motor/Generator 3 Inverter Rate Limits Active 1 Counter: The message counter is used to detect situations where the transmitting ECU malfunction repeats the same frame all the time. The receiver of the information may use the counter parameter to det...";
CM_ SG_ 2565992702 MtGt3IvtRtLtsAtvAstSpdRtLt "Motor/Generator 3 Inverter Rate Limits Active Absolute Speed Rate Limit: The active maximum rate of change for the absolute motor speed  (i.e. |d(speed)|/dt) in all control modes of this motor/generator inverter instance. Refer to SPN 11822 [Referenc...";
CM_ SG_ 2565992702 MtGt3IvtRtLtsAtvAstTqRtLt "Motor/Generator 3 Inverter Rate Limits Active Absolute Torque Rate Limit: The active maximum rate of change for the absolute motor torque (i.e. |d(torque)|/dt) in all control modes of this motor/generator inverter instance. Refer to SPN 11821 [Refere...";
CM_ BO_ 2364666366 "Motor/Generator 4 Inverter Mode Feedback 1";
CM_ SG_ 2364666366 MtrGnrtr4InvrtrMdFdk1CRC "Motor/Generator 4 Inverter Mode Feedback 1 CRC: The CRC is defined as follows:• Length: 8 bits• Polynomial: x^8+x^5+x^3+x^2+x+1• Initial Value: FFh• Input Data Reflection: Not reflected• Result Data Reflection: Not reflected• XOR value: FFhSAE makes ...";
CM_ SG_ 2364666366 MtrGnrtr4InvrtrMdFdk1Cntr "Motor/Generator 4 Inverter Mode Feedback 1 Counter: The message counter is used to detect situations where the transmitting ECU malfunction repeats the same frame all the time. The receiver of the information may use the counter parameter to detect t...";
CM_ SG_ 2364666366 MtrGnrtr4InvrtrCntrlLmtsOvrrdMd "Motor/Generator 4 Inverter Control Limits Override Mode: During normal operation this will have the same value as SPN 11928 [Control Limits Request Override Mode].  0 = Operating limits are not overridden.  If a limit was previously active, then it h...";
CM_ SG_ 2364666366 MtrGnrtr4InvrtrCntrlStpntMd "Motor/Generator 4 Inverter Control Setpoint Mode: Reports the inverter mode (See SPN 11931 [Control Setpoint Mode Request] for requested mode).Passive modes:  0 = Powered On - the inverter is commanded to be powered on and able to communicate, but th...";
CM_ SG_ 2364666366 MtrGnrtr4InvrtrHVILStts "Motor/Generator 4 Inverter HVIL Status: Reports the High Voltage Interlock Loop (HVIL) state.00b = HVIL Closed01b = HVIL Open10b = Error11b = Not Available";
CM_ BO_ 2565993214 "Motor/Generator 4 Inverter Limits Active Power";
CM_ SG_ 2565993214 MtrGnrtr4InvrtrLmtsAtvPwrCRC "Motor/Generator 4 Inverter Limits Active Power CRC: The CRC is defined as follows:• Length: 8 bits• Polynomial: x^8+x^5+x^3+x^2+x+1• Initial Value: FFh• Input Data Reflection: Not reflected• Result Data Reflection: Not reflected• XOR value: FFhSAE ma...";
CM_ SG_ 2565993214 MtrGnrtr4InvrtrLmtsAtvPwrCntr "Motor/Generator 4 Inverter Limits Active Power Counter: The message counter is used to detect situations where the transmitting ECU malfunction repeats the same frame all the time. The receiver of the information may use the counter parameter to dete...";
CM_ SG_ 2565993214 MtGt4IvtLtsAtvMPwMx "Motor/Generator 4 Inverter Limits Active Mechanical Power Maximum: The inverter keeps the mechanical motor power below this value.   This limit may be set in response to a Limits Request or determined by the inverter based on operating conditions.Ref...";
CM_ SG_ 2565993214 MtGt4IvtLtsAtvMPwM "Motor/Generator 4 Inverter Limits Active Mechanical Power Minimum: The inverter keeps the mechanical motor power above this value.   This limit may be set in response to a Limits Request or determined by the inverter based on operating conditions.Ref...";
CM_ SG_ 2565993214 MtGt4IvtLtsAtvDCSdPwMx "Motor/Generator 4 Inverter Limits Active DC Side Power Maximum: The inverter keeps the DC Side power below this value.   This limit may be set in response to a Limits Request or determined by the inverter based on operating conditions.Refer to SPN 11...";
CM_ SG_ 2565993214 MtGt4IvtLtsAtvDCSdPwM "Motor/Generator 4 Inverter Limits Active DC Side Power Minimum: The inverter keeps the DC side power above this value.   This limit may be set in response to a Limits Request or determined by the inverter based on operating conditions.Refer to SPN 11...";
CM_ BO_ 2565993470 "Motor/Generator 4 Inverter Limits Active Mechanical";
CM_ SG_ 2565993470 MtrGnrtr4InvrtrLmtsAtvMhnlCRC "Motor/Generator 4 Inverter Limits Active Mechanical CRC: The CRC is defined as follows:• Length: 8 bits• Polynomial: x^8+x^5+x^3+x^2+x+1• Initial Value: FFh• Input Data Reflection: Not reflected• Result Data Reflection: Not reflected• XOR value: FFhS...";
CM_ SG_ 2565993470 MtrGnrtr4InvrtrLmtsAtvMhnlCntr "Motor/Generator 4 Inverter Limits Active Mechanical Counter: The message counter is used to detect situations where the transmitting ECU malfunction repeats the same frame all the time. The receiver of the information may use the counter parameter to...";
CM_ SG_ 2565993470 MtrGnrtr4InvrtrLmtsAtvTrqMxmm "Motor/Generator 4 Inverter Limits Active Torque Maximum: The inverter keeps the motor torque below this value.  This limit may be set in response to a Limits Request or determined by the inverter based on operating conditions.Refer to SPN 11939 [Refe...";
CM_ SG_ 2565993470 MtrGnrtr4InvrtrLmtsAtvTrqMnmm "Motor/Generator 4 Inverter Limits Active Torque Minimum: The inverter keeps the motor torque above this value.  This limit may be set in response to a Limits Request or determined by the inverter based on operating conditions.Refer to SPN 11939 [Refe...";
CM_ SG_ 2565993470 MtrGnrtr4InvrtrLmtsAtvSpdMxmm "Motor/Generator 4 Inverter Limits Active Speed Maximum: The inverter keeps the motor speed below this value.  This limit may be set in response to a Limits Request or determined by the inverter based on operating conditions.Refer to SPN 11940 [Refere...";
CM_ SG_ 2565993470 MtrGnrtr4InvrtrLmtsAtvSpdMnmm "Motor/Generator 4 Inverter Limits Active Speed Minimum: The inverter keeps the motor Speed above this value.  This limit may be set in response to a Limits Request or determined by the inverter based on operating conditions.Refer to SPN 11940 [Refere...";
CM_ BO_ 2565993726 "Motor/Generator 4 Inverter Limits Active DC Side";
CM_ SG_ 2565993726 MtrGnrtr4InvrtrLmtsAtvDCSdCRC "Motor/Generator 4 Inverter Limits Active DC Side CRC: The CRC is defined as follows:• Length: 8 bits• Polynomial: x^8+x^5+x^3+x^2+x+1• Initial Value: FFh• Input Data Reflection: Not reflected• Result Data Reflection: Not reflected• XOR value: FFhSAE ...";
CM_ SG_ 2565993726 MtrGnrtr4InvrtrLmtsAtvDCSdCntr "Motor/Generator 4 Inverter Limits Active DC Side Counter: The message counter is used to detect situations where the transmitting ECU malfunction repeats the same frame all the time. The receiver of the information may use the counter parameter to de...";
CM_ SG_ 2565993726 MtGt4IvtLtsAtvDCSdVtMx "Motor/Generator 4 Inverter Limits Active DC Side Voltage Maximum: The inverter keeps the DC side voltage below this value.  This limit may be set in response to a Limits Request or determined by the inverter based on operating conditions.Refer to SPN...";
CM_ SG_ 2565993726 MtGt4IvtLtsAtvDCSdVtM "Motor/Generator 4 Inverter Limits Active DC Side Voltage Minimum: The inverter keeps the DC side voltage above this value.  This limit may be set in response to a Limits Request or determined by the inverter based on operating conditions.Refer to SPN...";
CM_ SG_ 2565993726 MtGt4IvtLtsAtvDCSdCtMx "Motor/Generator 4 Inverter Limits Active DC Side Current Maximum: The inverter keeps the DC side current below this value.  This limit may be set in response to a Limits Request or determined by the inverter based on operating conditions. Refer to SP...";
CM_ SG_ 2565993726 MtGt4IvtLtsAtvDCSdCtM "Motor/Generator 4 Inverter Limits Active DC Side Current Minimum: The inverter keeps the DC side current above this value.  This limit may be set in response to a Limits Request or determined by the inverter based on operating conditions.Refer to SPN...";
CM_ BO_ 2565993982 "Motor/Generator 4 Inverter Low Voltage";
CM_ SG_ 2565993982 MtrGnrtr4InvrtrSwthdIgntnVltg "Motor/Generator 4 Inverter Switched Ignition Voltage: Switched Ignition voltage supplied to this instance of the inverter controller.";
CM_ SG_ 2565993982 MtrGnrtr4InvrtrUnswthdSLIVltg "Motor/Generator 4 Inverter Unswitched SLI Voltage: Continuously supplied SLI power to this instance of the inverter controller.";
CM_ BO_ 2565994238 "Motor/Generator 4 Inverter Status 2";
CM_ SG_ 2565994238 MtrGnrtr4InvrtrStts2CRC "Motor/Generator 4 Inverter Status 2 CRC: The CRC is defined as follows:• Length: 8 bits• Polynomial: x^8+x^5+x^3+x^2+x+1• Initial Value: FFh• Input Data Reflection: Not reflected• Result Data Reflection: Not reflected• XOR value: FFhSAE makes no clai...";
CM_ SG_ 2565994238 MtrGnrtr4InvrtrStts2Cntr "Motor/Generator 4 Inverter Status 2 Counter: The message counter is used to detect situations where the transmitting ECU malfunction repeats the same frame all the time. The receiver of the information may use the counter parameter to detect this sit...";
CM_ SG_ 2565994238 MtrGnrtr4AvllMxmmTrq "Motor/Generator 4 Available Maximum Torque: This is an estimate of the maximum available motor torque including active deratings at the present motor speed.  This refers to the motor rotor output and excludes any gearbox that may be attached to the m...";
CM_ SG_ 2565994238 MtrGnrtr4AvllMnmmTrq "Motor/Generator 4 Available Minimum Torque: This is an estimate of the minimum available motor torque including active deratings at the present motor speed.  This refers to the motor rotor output and excludes any gearbox that may be attached to the m...";
CM_ BO_ 2565994494 "Motor/Generator 4 Inverter Rate Limits Active 1";
CM_ SG_ 2565994494 MtrGnrtr4InvrtrRtLmtsAtv1CRC "Motor/Generator 4 Inverter Rate Limits Active 1 CRC: The CRC is defined as follows:• Length: 8 bits• Polynomial: x^8+x^5+x^3+x^2+x+1• Initial Value: FFh• Input Data Reflection: Not reflected• Result Data Reflection: Not reflected• XOR value: FFhSAE m...";
CM_ SG_ 2565994494 MtrGnrtr4InvrtrRtLmtsAtv1Cntr "Motor/Generator 4 Inverter Rate Limits Active 1 Counter: The message counter is used to detect situations where the transmitting ECU malfunction repeats the same frame all the time. The receiver of the information may use the counter parameter to det...";
CM_ SG_ 2565994494 MtGt4IvtRtLtsAtvAstSpdRtLt "Motor/Generator 4 Inverter Rate Limits Active Absolute Speed Rate Limit: The active maximum rate of change for the absolute motor speed  (i.e. |d(speed)|/dt) in all control modes of this motor/generator inverter instance. Refer to SPN 11940 [Referenc...";
CM_ SG_ 2565994494 MtGt4IvtRtLtsAtvAstTqRtLt "Motor/Generator 4 Inverter Rate Limits Active Absolute Torque Rate Limit: The active maximum rate of change for the absolute motor torque (i.e. |d(torque)|/dt) in all control modes of this motor/generator inverter instance. Refer to SPN 11939 [Refere...";
CM_ BO_ 2364668158 "Motor/Generator 5 Inverter Mode Feedback 1";
CM_ SG_ 2364668158 MtrGnrtr5InvrtrMdFdk1CRC "Motor/Generator 5 Inverter Mode Feedback 1 CRC: The CRC is defined as follows:• Length: 8 bits• Polynomial: x^8+x^5+x^3+x^2+x+1• Initial Value: FFh• Input Data Reflection: Not reflected• Result Data Reflection: Not reflected• XOR value: FFhSAE makes ...";
CM_ SG_ 2364668158 MtrGnrtr5InvrtrMdFdk1Cntr "Motor/Generator 5 Inverter Mode Feedback 1 Counter: The message counter is used to detect situations where the transmitting ECU malfunction repeats the same frame all the time. The receiver of the information may use the counter parameter to detect t...";
CM_ SG_ 2364668158 MtrGnrtr5InvrtrCntrlLmtsOvrrdMd "Motor/Generator 5 Inverter Control Limits Override Mode: During normal operation this will have the same value as SPN 12046 [Control Limits Request Override Mode].  0 = Operating limits are not overridden.  If a limit was previously active, then it h...";
CM_ SG_ 2364668158 MtrGnrtr5InvrtrCntrlStpntMd "Motor/Generator 5 Inverter Control Setpoint Mode: Reports the inverter mode (See SPN 12049 [Control Setpoint Mode Request] for requested mode).Passive modes:  0 = Powered On - the inverter is commanded to be powered on and able to communicate, but th...";
CM_ SG_ 2364668158 MtrGnrtr5InvrtrHVILStts "Motor/Generator 5 Inverter HVIL Status: Reports the High Voltage Interlock Loop (HVIL) state.00b = HVIL Closed01b = HVIL Open10b = Error11b = Not Available";
CM_ BO_ 2565995006 "Motor/Generator 5 Inverter Limits Active Power";
CM_ SG_ 2565995006 MtrGnrtr5InvrtrLmtsAtvPwrCRC "Motor/Generator 5 Inverter Limits Active Power CRC: The CRC is defined as follows:• Length: 8 bits• Polynomial: x^8+x^5+x^3+x^2+x+1• Initial Value: FFh• Input Data Reflection: Not reflected• Result Data Reflection: Not reflected• XOR value: FFhSAE ma...";
CM_ SG_ 2565995006 MtrGnrtr5InvrtrLmtsAtvPwrCntr "Motor/Generator 5 Inverter Limits Active Power Counter: The message counter is used to detect situations where the transmitting ECU malfunction repeats the same frame all the time. The receiver of the information may use the counter parameter to dete...";
CM_ SG_ 2565995006 MtGt5IvtLtsAtvMPwMx "Motor/Generator 5 Inverter Limits Active Mechanical Power Maximum: The inverter keeps the mechanical motor power below this value.   This limit may be set in response to a Limits Request or determined by the inverter based on operating conditions.Ref...";
CM_ SG_ 2565995006 MtGt5IvtLtsAtvMPwM "Motor/Generator 5 Inverter Limits Active Mechanical Power Minimum: The inverter keeps the mechanical motor power above this value.   This limit may be set in response to a Limits Request or determined by the inverter based on operating conditions.Ref...";
CM_ SG_ 2565995006 MtGt5IvtLtsAtvDCSdPwMx "Motor/Generator 5 Inverter Limits Active DC Side Power Maximum: The inverter keeps the DC Side power below this value.   This limit may be set in response to a Limits Request or determined by the inverter based on operating conditions.Refer to SPN 12...";
CM_ SG_ 2565995006 MtGt5IvtLtsAtvDCSdPwM "Motor/Generator 5 Inverter Limits Active DC Side Power Minimum: The inverter keeps the DC side power above this value.   This limit may be set in response to a Limits Request or determined by the inverter based on operating conditions.Refer to SPN 12...";
CM_ BO_ 2565995262 "Motor/Generator 5 Inverter Limits Active Mechanical";
CM_ SG_ 2565995262 MtrGnrtr5InvrtrLmtsAtvMhnlCRC "Motor/Generator 5 Inverter Limits Active Mechanical CRC: The CRC is defined as follows:• Length: 8 bits• Polynomial: x^8+x^5+x^3+x^2+x+1• Initial Value: FFh• Input Data Reflection: Not reflected• Result Data Reflection: Not reflected• XOR value: FFhS...";
CM_ SG_ 2565995262 MtrGnrtr5InvrtrLmtsAtvMhnlCntr "Motor/Generator 5 Inverter Limits Active Mechanical Counter: The message counter is used to detect situations where the transmitting ECU malfunction repeats the same frame all the time. The receiver of the information may use the counter parameter to...";
CM_ SG_ 2565995262 MtrGnrtr5InvrtrLmtsAtvTrqMxmm "Motor/Generator 5 Inverter Limits Active Torque Maximum: The inverter keeps the motor torque below this value.  This limit may be set in response to a Limits Request or determined by the inverter based on operating conditions.Refer to SPN 12057 [Refe...";
CM_ SG_ 2565995262 MtrGnrtr5InvrtrLmtsAtvTrqMnmm "Motor/Generator 5 Inverter Limits Active Torque Minimum: The inverter keeps the motor torque above this value.  This limit may be set in response to a Limits Request or determined by the inverter based on operating conditions.Refer to SPN 12057 [Refe...";
CM_ SG_ 2565995262 MtrGnrtr5InvrtrLmtsAtvSpdMxmm "Motor/Generator 5 Inverter Limits Active Speed Maximum: The inverter keeps the motor speed below this value.  This limit may be set in response to a Limits Request or determined by the inverter based on operating conditions.Refer to SPN 12058 [Refere...";
CM_ SG_ 2565995262 MtrGnrtr5InvrtrLmtsAtvSpdMnmm "Motor/Generator 5 Inverter Limits Active Speed Minimum: The inverter keeps the motor Speed above this value.  This limit may be set in response to a Limits Request or determined by the inverter based on operating conditions.Refer to SPN 12058 [Refere...";
CM_ BO_ 2565995518 "Motor/Generator 5 Inverter Limits Active DC Side";
CM_ SG_ 2565995518 MtrGnrtr5InvrtrLmtsAtvDCSdCRC "Motor/Generator 5 Inverter Limits Active DC Side CRC: The CRC is defined as follows:• Length: 8 bits• Polynomial: x^8+x^5+x^3+x^2+x+1• Initial Value: FFh• Input Data Reflection: Not reflected• Result Data Reflection: Not reflected• XOR value: FFhSAE ...";
CM_ SG_ 2565995518 MtrGnrtr5InvrtrLmtsAtvDCSdCntr "Motor/Generator 5 Inverter Limits Active DC Side Counter: The message counter is used to detect situations where the transmitting ECU malfunction repeats the same frame all the time. The receiver of the information may use the counter parameter to de...";
CM_ SG_ 2565995518 MtGt5IvtLtsAtvDCSdVtMx "Motor/Generator 5 Inverter Limits Active DC Side Voltage Maximum: The inverter keeps the DC side voltage below this value.  This limit may be set in response to a Limits Request or determined by the inverter based on operating conditions.Refer to SPN...";
CM_ SG_ 2565995518 MtGt5IvtLtsAtvDCSdVtM "Motor/Generator 5 Inverter Limits Active DC Side Voltage Minimum: The inverter keeps the DC side voltage above this value.  This limit may be set in response to a Limits Request or determined by the inverter based on operating conditions.Refer to SPN...";
CM_ SG_ 2565995518 MtGt5IvtLtsAtvDCSdCtMx "Motor/Generator 5 Inverter Limits Active DC Side Current Maximum: The inverter keeps the DC side current below this value.  This limit may be set in response to a Limits Request or determined by the inverter based on operating conditions. Refer to SP...";
CM_ SG_ 2565995518 MtGt5IvtLtsAtvDCSdCtM "Motor/Generator 5 Inverter Limits Active DC Side Current Minimum: The inverter keeps the DC side current above this value.  This limit may be set in response to a Limits Request or determined by the inverter based on operating conditions.Refer to SPN...";
CM_ BO_ 2565995774 "Motor/Generator 5 Inverter Low Voltage";
CM_ SG_ 2565995774 MtrGnrtr5InvrtrSwthdIgntnVltg "Motor/Generator 5 Inverter Switched Ignition Voltage: Switched Ignition voltage supplied to this instance of the inverter controller.";
CM_ SG_ 2565995774 MtrGnrtr5InvrtrUnswthdSLIVltg "Motor/Generator 5 Inverter Unswitched SLI Voltage: Continuously supplied SLI power to this instance of the inverter controller.";
CM_ BO_ 2565996030 "Motor/Generator 5 Inverter Status 2";
CM_ SG_ 2565996030 MtrGnrtr5InvrtrStts2CRC "Motor/Generator 5 Inverter Status 2 CRC: The CRC is defined as follows:• Length: 8 bits• Polynomial: x^8+x^5+x^3+x^2+x+1• Initial Value: FFh• Input Data Reflection: Not reflected• Result Data Reflection: Not reflected• XOR value: FFhSAE makes no clai...";
CM_ SG_ 2565996030 MtrGnrtr5InvrtrStts2Cntr "Motor/Generator 5 Inverter Status 2 Counter: The message counter is used to detect situations where the transmitting ECU malfunction repeats the same frame all the time. The receiver of the information may use the counter parameter to detect this sit...";
CM_ SG_ 2565996030 MtrGnrtr5AvllMxmmTrq "Motor/Generator 5 Available Maximum Torque: This is an estimate of the maximum available motor torque including active deratings at the present motor speed.  This refers to the motor rotor output and excludes any gearbox that may be attached to the m...";
CM_ SG_ 2565996030 MtrGnrtr5AvllMnmmTrq "Motor/Generator 5 Available Minimum Torque: This is an estimate of the minimum available motor torque including active deratings at the present motor speed.  This refers to the motor rotor output and excludes any gearbox that may be attached to the m...";
CM_ BO_ 2565996286 "Motor/Generator 5 Inverter Rate Limits Active 1";
CM_ SG_ 2565996286 MtrGnrtr5InvrtrRtLmtsAtv1CRC "Motor/Generator 5 Inverter Rate Limits Active 1 CRC: The CRC is defined as follows:• Length: 8 bits• Polynomial: x^8+x^5+x^3+x^2+x+1• Initial Value: FFh• Input Data Reflection: Not reflected• Result Data Reflection: Not reflected• XOR value: FFhSAE m...";
CM_ SG_ 2565996286 MtrGnrtr5InvrtrRtLmtsAtv1Cntr "Motor/Generator 5 Inverter Rate Limits Active 1 Counter: The message counter is used to detect situations where the transmitting ECU malfunction repeats the same frame all the time. The receiver of the information may use the counter parameter to det...";
CM_ SG_ 2565996286 MtGt5IvtRtLtsAtvAstSpdRtLt "Motor/Generator 5 Inverter Rate Limits Active Absolute Speed Rate Limit: The active maximum rate of change for the absolute motor speed  (i.e. |d(speed)|/dt) in all control modes of this motor/generator inverter instance. Refer to SPN 12058 [Referenc...";
CM_ SG_ 2565996286 MtGt5IvtRtLtsAtvAstTqRtLt "Motor/Generator 5 Inverter Rate Limits Active Absolute Torque Rate Limit: The active maximum rate of change for the absolute motor torque (i.e. |d(torque)|/dt) in all control modes of this motor/generator inverter instance. Refer to SPN 12057 [Refere...";
CM_ BO_ 2364669950 "Motor/Generator 6 Inverter Mode Feedback 1";
CM_ SG_ 2364669950 MtrGnrtr6InvrtrMdFdk1CRC "Motor/Generator 6 Inverter Mode Feedback 1 CRC: The CRC is defined as follows:• Length: 8 bits• Polynomial: x^8+x^5+x^3+x^2+x+1• Initial Value: FFh• Input Data Reflection: Not reflected• Result Data Reflection: Not reflected• XOR value: FFhSAE makes ...";
CM_ SG_ 2364669950 MtrGnrtr6InvrtrMdFdk1Cntr "Motor/Generator 6 Inverter Mode Feedback 1 Counter: The message counter is used to detect situations where the transmitting ECU malfunction repeats the same frame all the time. The receiver of the information may use the counter parameter to detect t...";
CM_ SG_ 2364669950 MtrGnrtr6InvrtrCntrlLmtsOvrrdMd "Motor/Generator 6 Inverter Control Limits Override Mode: During normal operation this will have the same value as SPN 12164 [Control Limits Request Override Mode].  0 = Operating limits are not overridden.  If a limit was previously active, then it h...";
CM_ SG_ 2364669950 MtrGnrtr6InvrtrCntrlStpntMd "Motor/Generator 6 Inverter Control Setpoint Mode: Reports the inverter mode (See SPN 12167 [Control Setpoint Mode Request] for requested mode).Passive modes:  0 = Powered On - the inverter is commanded to be powered on and able to communicate, but th...";
CM_ SG_ 2364669950 MtrGnrtr6InvrtrHVILStts "Motor/Generator 6 Inverter HVIL Status: Reports the High Voltage Interlock Loop (HVIL) state.00b = HVIL Closed01b = HVIL Open10b = Error11b = Not Available";
CM_ BO_ 2565996798 "Motor/Generator 6 Inverter Limits Active Power";
CM_ SG_ 2565996798 MtrGnrtr6InvrtrLmtsAtvPwrCRC "Motor/Generator 6 Inverter Limits Active Power CRC: The CRC is defined as follows:• Length: 8 bits• Polynomial: x^8+x^5+x^3+x^2+x+1• Initial Value: FFh• Input Data Reflection: Not reflected• Result Data Reflection: Not reflected• XOR value: FFhSAE ma...";
CM_ SG_ 2565996798 MtrGnrtr6InvrtrLmtsAtvPwrCntr "Motor/Generator 6 Inverter Limits Active Power Counter: The message counter is used to detect situations where the transmitting ECU malfunction repeats the same frame all the time. The receiver of the information may use the counter parameter to dete...";
CM_ SG_ 2565996798 MtGt6IvtLtsAtvMPwMx "Motor/Generator 6 Inverter Limits Active Mechanical Power Maximum: The inverter keeps the mechanical motor power below this value.   This limit may be set in response to a Limits Request or determined by the inverter based on operating conditions.Ref...";
CM_ SG_ 2565996798 MtGt6IvtLtsAtvMPwM "Motor/Generator 6 Inverter Limits Active Mechanical Power Minimum: The inverter keeps the mechanical motor power above this value.   This limit may be set in response to a Limits Request or determined by the inverter based on operating conditions.Ref...";
CM_ SG_ 2565996798 MtGt6IvtLtsAtvDCSdPwMx "Motor/Generator 6 Inverter Limits Active DC Side Power Maximum: The inverter keeps the DC Side power below this value.   This limit may be set in response to a Limits Request or determined by the inverter based on operating conditions.Refer to SPN 12...";
CM_ SG_ 2565996798 MtGt6IvtLtsAtvDCSdPwM "Motor/Generator 6 Inverter Limits Active DC Side Power Minimum: The inverter keeps the DC side power above this value.   This limit may be set in response to a Limits Request or determined by the inverter based on operating conditions.Refer to SPN 12...";
CM_ BO_ 2565997054 "Motor/Generator 6 Inverter Limits Active Mechanical";
CM_ SG_ 2565997054 MtrGnrtr6InvrtrLmtsAtvMhnlCRC "Motor/Generator 6 Inverter Limits Active Mechanical CRC: The CRC is defined as follows:• Length: 8 bits• Polynomial: x^8+x^5+x^3+x^2+x+1• Initial Value: FFh• Input Data Reflection: Not reflected• Result Data Reflection: Not reflected• XOR value: FFhS...";
CM_ SG_ 2565997054 MtrGnrtr6InvrtrLmtsAtvMhnlCntr "Motor/Generator 6 Inverter Limits Active Mechanical Counter: The message counter is used to detect situations where the transmitting ECU malfunction repeats the same frame all the time. The receiver of the information may use the counter parameter to...";
CM_ SG_ 2565997054 MtrGnrtr6InvrtrLmtsAtvTrqMxmm "Motor/Generator 6 Inverter Limits Active Torque Maximum: The inverter keeps the motor torque below this value.  This limit may be set in response to a Limits Request or determined by the inverter based on operating conditions.Refer to SPN 12175 [Refe...";
CM_ SG_ 2565997054 MtrGnrtr6InvrtrLmtsAtvTrqMnmm "Motor/Generator 6 Inverter Limits Active Torque Minimum: The inverter keeps the motor torque above this value.  This limit may be set in response to a Limits Request or determined by the inverter based on operating conditions.Refer to SPN 12175 [Refe...";
CM_ SG_ 2565997054 MtrGnrtr6InvrtrLmtsAtvSpdMxmm "Motor/Generator 6 Inverter Limits Active Speed Maximum: The inverter keeps the motor speed below this value.  This limit may be set in response to a Limits Request or determined by the inverter based on operating conditions.Refer to SPN 12176 [Refere...";
CM_ SG_ 2565997054 MtrGnrtr6InvrtrLmtsAtvSpdMnmm "Motor/Generator 6 Inverter Limits Active Speed Minimum: The inverter keeps the motor Speed above this value.  This limit may be set in response to a Limits Request or determined by the inverter based on operating conditions.Refer to SPN 12176 [Refere...";
CM_ BO_ 2565997310 "Motor/Generator 6 Inverter Limits Active DC Side";
CM_ SG_ 2565997310 MtrGnrtr6InvrtrLmtsAtvDCSdCRC "Motor/Generator 6 Inverter Limits Active DC Side CRC: The CRC is defined as follows:• Length: 8 bits• Polynomial: x^8+x^5+x^3+x^2+x+1• Initial Value: FFh• Input Data Reflection: Not reflected• Result Data Reflection: Not reflected• XOR value: FFhSAE ...";
CM_ SG_ 2565997310 MtrGnrtr6InvrtrLmtsAtvDCSdCntr "Motor/Generator 6 Inverter Limits Active DC Side Counter: The message counter is used to detect situations where the transmitting ECU malfunction repeats the same frame all the time. The receiver of the information may use the counter parameter to de...";
CM_ SG_ 2565997310 MtGt6IvtLtsAtvDCSdVtMx "Motor/Generator 6 Inverter Limits Active DC Side Voltage Maximum: The inverter keeps the DC side voltage below this value.  This limit may be set in response to a Limits Request or determined by the inverter based on operating conditions.Refer to SPN...";
CM_ SG_ 2565997310 MtGt6IvtLtsAtvDCSdVtM "Motor/Generator 6 Inverter Limits Active DC Side Voltage Minimum: The inverter keeps the DC side voltage above this value.  This limit may be set in response to a Limits Request or determined by the inverter based on operating conditions.Refer to SPN...";
CM_ SG_ 2565997310 MtGt6IvtLtsAtvDCSdCtMx "Motor/Generator 6 Inverter Limits Active DC Side Current Maximum: The inverter keeps the DC side current below this value.  This limit may be set in response to a Limits Request or determined by the inverter based on operating conditions. Refer to SP...";
CM_ SG_ 2565997310 MtGt6IvtLtsAtvDCSdCtM "Motor/Generator 6 Inverter Limits Active DC Side Current Minimum: The inverter keeps the DC side current above this value.  This limit may be set in response to a Limits Request or determined by the inverter based on operating conditions.Refer to SPN...";
CM_ BO_ 2565997566 "Motor/Generator 6 Inverter Low Voltage";
CM_ SG_ 2565997566 MtrGnrtr6InvrtrSwthdIgntnVltg "Motor/Generator 6 Inverter Switched Ignition Voltage: Switched Ignition voltage supplied to this instance of the inverter controller.";
CM_ SG_ 2565997566 MtrGnrtr6InvrtrUnswthdSLIVltg "Motor/Generator 6 Inverter Unswitched SLI Voltage: Continuously supplied SLI power to this instance of the inverter controller.";
CM_ BO_ 2565997822 "Motor/Generator 6 Inverter Status 2";
CM_ SG_ 2565997822 MtrGnrtr6InvrtrStts2CRC "Motor/Generator 6 Inverter Status 2 CRC: The CRC is defined as follows:• Length: 8 bits• Polynomial: x^8+x^5+x^3+x^2+x+1• Initial Value: FFh• Input Data Reflection: Not reflected• Result Data Reflection: Not reflected• XOR value: FFhSAE makes no clai...";
CM_ SG_ 2565997822 MtrGnrtr6InvrtrStts2Cntr "Motor/Generator 6 Inverter Status 2 Counter: The message counter is used to detect situations where the transmitting ECU malfunction repeats the same frame all the time. The receiver of the information may use the counter parameter to detect this sit...";
CM_ SG_ 2565997822 MtrGnrtr6AvllMxmmTrq "Motor/Generator 6 Available Maximum Torque: This is an estimate of the maximum available motor torque including active deratings at the present motor speed.  This refers to the motor rotor output and excludes any gearbox that may be attached to the m...";
CM_ SG_ 2565997822 MtrGnrtr6AvllMnmmTrq "Motor/Generator 6 Available Minimum Torque: This is an estimate of the minimum available motor torque including active deratings at the present motor speed.  This refers to the motor rotor output and excludes any gearbox that may be attached to the m...";
CM_ BO_ 2565998078 "Motor/Generator 6 Inverter Rate Limits Active 1";
CM_ SG_ 2565998078 MtrGnrtr6InvrtrRtLmtsAtv1CRC "Motor/Generator 6 Inverter Rate Limits Active 1 CRC: The CRC is defined as follows:• Length: 8 bits• Polynomial: x^8+x^5+x^3+x^2+x+1• Initial Value: FFh• Input Data Reflection: Not reflected• Result Data Reflection: Not reflected• XOR value: FFhSAE m...";
CM_ SG_ 2565998078 MtrGnrtr6InvrtrRtLmtsAtv1Cntr "Motor/Generator 6 Inverter Rate Limits Active 1 Counter: The message counter is used to detect situations where the transmitting ECU malfunction repeats the same frame all the time. The receiver of the information may use the counter parameter to det...";
CM_ SG_ 2565998078 MtGt6IvtRtLtsAtvAstSpdRtLt "Motor/Generator 6 Inverter Rate Limits Active Absolute Speed Rate Limit: The active maximum rate of change for the absolute motor speed  (i.e. |d(speed)|/dt) in all control modes of this motor/generator inverter instance. Refer to SPN 12176 [Referenc...";
CM_ SG_ 2565998078 MtGt6IvtRtLtsAtvAstTqRtLt "Motor/Generator 6 Inverter Rate Limits Active Absolute Torque Rate Limit: The active maximum rate of change for the absolute motor torque (i.e. |d(torque)|/dt) in all control modes of this motor/generator inverter instance. Refer to SPN 12175 [Refere...";
CM_ BO_ 2364671742 "Blind Spot Detection 1";
CM_ SG_ 2364671742 BlindSpotDetectionState "Blind Spot Detection State: Current operational state of the blind spot detection function. 0000b = system is not ready (initialization not finished) 0001b = system is temporarily not available (e.g. due to boundary conditions necessary for operation...";
CM_ SG_ 2364671742 BlindSpotCollisionWarningLevel "Blind Spot Collision Warning Level: To implement different human machine interface (HMI) concepts, e.g. visual only, visual/audible, different warning tones etc., the object detection provides different levels of collision warning. 0000b = no warning...";
CM_ SG_ 2364671742 BlndSptWrnngRlvntOjtDttd "Blind Spot Warning Relevant Object Detected: Indication if the blind spot detection system (BSD) is monitoring a relevant object.000b = No relevant object monitored 001b = Single relevant object is being monitored 010b = Multiple relevant objects are...";
CM_ SG_ 2364671742 BndOffPrltfMstImprtntOjt "Bend-Off Probability of Most Important Object: Probabilty if the most important monitored relevant object might start a bend-off maneuver (e.g. turning), which could clear the travelling path of the host vehicle. 000b = no indication for a bend-off m...";
CM_ SG_ 2364671742 BlndSptDttnLftSdMntrd "Blind Spot Detection Left Side Monitored: Indicates if left side area is monitored by the blind spot detection system. This signal can be used to trigger the correct warning(s) in the human machine interface (HMI).00b = Not being monitored 01b = Moni...";
CM_ SG_ 2364671742 BlndSptDttnRghtSdMntrd "Blind Spot Detection Right Side Monitored: Indicates if right side area is monitored by the blind spot detection system. This signal can be used to trigger the correct warning(s) in the human machine interface (HMI).00b = Not being monitored 01b = Mo...";
CM_ SG_ 2364671742 BlndSptDttnFrntMntrd "Blind Spot Detection Front Monitored: Indicates if front area is monitored by the blind spot detection system. This signal can be used to trigger the correct warning(s) in the human machine interface (HMI).00b = Not being monitored 01b = Monitored10b...";
CM_ SG_ 2364671742 BlindSpotDetectionRearMonitored "Blind Spot Detection Rear Monitored: Indicates if rear area is monitored by the blind spot detection system. This signal can be used to trigger the correct warning(s) in the human machine interface (HMI).00b = Not being monitored 01b = Monitored10b =...";
CM_ BO_ 2364671998 "Winch Information 1";
CM_ SG_ 2364671998 WinchMotorEncoderPosition "Winch Motor Encoder Position: Angular position of the winch motor shaft where 0 represents the initial position, with the value incrementing up to 32767 before rolling over to 0 at one complete revolution.  Likewise, the value decrements for reverse ...";
CM_ SG_ 2364671998 WinchRevolutionCounter "Winch Revolution Counter: Count of complete revolutions since reset. Value increments in forward direction and decrements in reverse direction.";
CM_ BO_ 2364672254 "Motor/Generator 3 Inverter Control";
CM_ SG_ 2364672254 MtrGnrtr3InvrtrCntrlCRC "Motor/Generator 3 Inverter Control CRC: The CRC is defined as follows:• Length: 8 bits• Polynomial: x^8+x^5+x^3+x^2+x+1• Initial Value: FFh• Input Data Reflection: Not reflected• Result Data Reflection: Not reflected• XOR value: FFhSAE makes no claim...";
CM_ SG_ 2364672254 MtrGnrtr3InvrtrCntrlCntr "Motor/Generator 3 Inverter Control Counter: The message counter is used to detect situations where the transmitting ECU malfunction repeats the same frame all the time. The receiver of the information may use the counter parameter to detect this situ...";
CM_ SG_ 2364672254 MtGt3IvtCtLtsRqstOvdMd "Motor/Generator 3 Inverter Control Limits Request Override Mode: This parameter provides a way to temporarily override limits that are being received by the inverter in other messages.  It allows a specific type of limit to be transmitted at a high r...";
CM_ SG_ 2364672254 MtGt3IvtCtLtsRqstOvdMx "Motor/Generator 3 Inverter Control Limits Request Override Maximum: The Maximum limit requested by this parameter depends on the value of SPN 11810 [Control Limits Request Override Mode].In normal operating conditions, the inverter operating limits a...";
CM_ SG_ 2364672254 MtGt3IvtCtLtsRqstOvdM "Motor/Generator 3 Inverter Control Limits Request Override Minimum : The Minimum limit requested by this parameter depends on the value of SPN 11810 [Control Limits Request Override Mode].In normal operating conditions, the inverter operating limits ...";
CM_ SG_ 2364672254 MtrGnrtr3InvrtrCntrlStpntMdRqst "Motor/Generator 3 Inverter Control Setpoint Mode Request: Requests the modes for this instance of the inverter.  See SPN 11818 [Control Setpoint Mode] for the feedback to this request.Passive modes:  Modes where the inverter does not actively control...";
CM_ SG_ 2364672254 MtrGnrtr3InvrtrCntrlStpntRqst "Motor/Generator 3 Inverter Control Setpoint Request: Requests the set point for this inverter.  The type of set point requested by this parameter depends on the value of SPN 11813 [Control Setpoint Mode Request] as follows:Passive Modes: In any Passi...";
CM_ BO_ 2565999102 "Motor/Generator 3 Inverter Rate Limits Request 1";
CM_ SG_ 2565999102 MtrGnrtr3InvrtrRtLmtsRqst1CRC "Motor/Generator 3 Inverter Rate Limits Request 1 CRC: The CRC is defined as follows:• Length: 8 bits• Polynomial: x^8+x^5+x^3+x^2+x+1• Initial Value: FFh• Input Data Reflection: Not reflected• Result Data Reflection: Not reflected• XOR value: FFhSAE ...";
CM_ SG_ 2565999102 MtrGnrtr3InvrtrRtLmtsRqst1Cntr "Motor/Generator 3 Inverter Rate Limits Request 1 Counter: The message counter is used to detect situations where the transmitting ECU malfunction repeats the same frame all the time. The receiver of the information may use the counter parameter to de...";
CM_ SG_ 2565999102 MtGt3IvtRtLtsRqstAstSpdRtLt "Motor/Generator 3 Inverter Rate Limits Request Absolute Speed Rate Limit: The maximum rate of change for the absolute motor speed  (i.e. |d(speed)|/dt) in all control modes. This limit shall solely lead to reducing the absolute torque, not increasing...";
CM_ SG_ 2565999102 MtGt3IvtRtLtsRqstAstTqRtLt "Motor/Generator 3 Inverter Rate Limits Request Absolute Torque Rate Limit: The maximum rate of change for the absolute motor torque (i.e. |d(torque)|/dt) in all control modes. Refer to SPN 11821 [Reference Torque] to convert %/sec to Nm/sec. Request ...";
CM_ BO_ 2364672766 "Motor/Generator 4 Inverter Control";
CM_ SG_ 2364672766 MtrGnrtr4InvrtrCntrlCRC "Motor/Generator 4 Inverter Control CRC: The CRC is defined as follows:• Length: 8 bits• Polynomial: x^8+x^5+x^3+x^2+x+1• Initial Value: FFh• Input Data Reflection: Not reflected• Result Data Reflection: Not reflected• XOR value: FFhSAE makes no claim...";
CM_ SG_ 2364672766 MtrGnrtr4InvrtrCntrlCntr "Motor/Generator 4 Inverter Control Counter: The message counter is used to detect situations where the transmitting ECU malfunction repeats the same frame all the time. The receiver of the information may use the counter parameter to detect this situ...";
CM_ SG_ 2364672766 MtGt4IvtCtLtsRqstOvdMd "Motor/Generator 4 Inverter Control Limits Request Override Mode: This parameter provides a way to temporarily override limits that are being received by the inverter in other messages.  It allows a specific type of limit to be transmitted at a high r...";
CM_ SG_ 2364672766 MtGt4IvtCtLtsRqstOvdMx "Motor/Generator 4 Inverter Control Limits Request Override Maximum: The Maximum limit requested by this parameter depends on the value of SPN 11928 [Control Limits Request Override Mode].In normal operating conditions, the inverter operating limits a...";
CM_ SG_ 2364672766 MtGt4IvtCtLtsRqstOvdM "Motor/Generator 4 Inverter Control Limits Request Override Minimum : The Minimum limit requested by this parameter depends on the value of SPN 11928 [Control Limits Request Override Mode].In normal operating conditions, the inverter operating limits ...";
CM_ SG_ 2364672766 MtrGnrtr4InvrtrCntrlStpntMdRqst "Motor/Generator 4 Inverter Control Setpoint Mode Request: Requests the modes for this instance of the inverter.  See SPN 11936 [Control Setpoint Mode] for the feedback to this request.Passive modes:  Modes where the inverter does not actively control...";
CM_ SG_ 2364672766 MtrGnrtr4InvrtrCntrlStpntRqst "Motor/Generator 4 Inverter Control Setpoint Request: Requests the set point for this inverter.  The type of set point requested by this parameter depends on the value of SPN 11931 [Control Setpoint Mode Request] as follows:Passive Modes: In any Passi...";
CM_ BO_ 2565999614 "Motor/Generator 4 Inverter Rate Limits Request 1";
CM_ SG_ 2565999614 MtrGnrtr4InvrtrRtLmtsRqst1CRC "Motor/Generator 4 Inverter Rate Limits Request 1 CRC: The CRC is defined as follows:• Length: 8 bits• Polynomial: x^8+x^5+x^3+x^2+x+1• Initial Value: FFh• Input Data Reflection: Not reflected• Result Data Reflection: Not reflected• XOR value: FFhSAE ...";
CM_ SG_ 2565999614 MtrGnrtr4InvrtrRtLmtsRqst1Cntr "Motor/Generator 4 Inverter Rate Limits Request 1 Counter: The message counter is used to detect situations where the transmitting ECU malfunction repeats the same frame all the time. The receiver of the information may use the counter parameter to de...";
CM_ SG_ 2565999614 MtGt4IvtRtLtsRqstAstSpdRtLt "Motor/Generator 4 Inverter Rate Limits Request Absolute Speed Rate Limit: The maximum rate of change for the absolute motor speed  (i.e. |d(speed)|/dt) in all control modes. This limit shall solely lead to reducing the absolute torque, not increasing...";
CM_ SG_ 2565999614 MtGt4IvtRtLtsRqstAstTqRtLt "Motor/Generator 4 Inverter Rate Limits Request Absolute Torque Rate Limit: The maximum rate of change for the absolute motor torque (i.e. |d(torque)|/dt) in all control modes. Refer to SPN 11939 [Reference Torque] to convert %/sec to Nm/sec. Request ...";
CM_ BO_ 2364673278 "Motor/Generator 5 Inverter Control";
CM_ SG_ 2364673278 MtrGnrtr5InvrtrCntrlCRC "Motor/Generator 5 Inverter Control CRC: The CRC is defined as follows:• Length: 8 bits• Polynomial: x^8+x^5+x^3+x^2+x+1• Initial Value: FFh• Input Data Reflection: Not reflected• Result Data Reflection: Not reflected• XOR value: FFhSAE makes no claim...";
CM_ SG_ 2364673278 MtrGnrtr5InvrtrCntrlCntr "Motor/Generator 5 Inverter Control Counter: The message counter is used to detect situations where the transmitting ECU malfunction repeats the same frame all the time. The receiver of the information may use the counter parameter to detect this situ...";
CM_ SG_ 2364673278 MtGt5IvtCtLtsRqstOvdMd "Motor/Generator 5 Inverter Control Limits Request Override Mode: This parameter provides a way to temporarily override limits that are being received by the inverter in other messages.  It allows a specific type of limit to be transmitted at a high r...";
CM_ SG_ 2364673278 MtGt5IvtCtLtsRqstOvdMx "Motor/Generator 5 Inverter Control Limits Request Override Maximum: The Maximum limit requested by this parameter depends on the value of SPN 12046 [Control Limits Request Override Mode].In normal operating conditions, the inverter operating limits a...";
CM_ SG_ 2364673278 MtGt5IvtCtLtsRqstOvdM "Motor/Generator 5 Inverter Control Limits Request Override Minimum : The Minimum limit requested by this parameter depends on the value of SPN 12046 [Control Limits Request Override Mode].In normal operating conditions, the inverter operating limits ...";
CM_ SG_ 2364673278 MtrGnrtr5InvrtrCntrlStpntMdRqst "Motor/Generator 5 Inverter Control Setpoint Mode Request: Requests the modes for this instance of the inverter.  See SPN 12054 [Control Setpoint Mode] for the feedback to this request.Passive modes:  Modes where the inverter does not actively control...";
CM_ SG_ 2364673278 MtrGnrtr5InvrtrCntrlStpntRqst "Motor/Generator 5 Inverter Control Setpoint Request: Requests the set point for this inverter.  The type of set point requested by this parameter depends on the value of SPN 12049 [Control Setpoint Mode Request] as follows:Passive Modes: In any Passi...";
CM_ BO_ 2566000126 "Motor/Generator 5 Inverter Rate Limits Request 1";
CM_ SG_ 2566000126 MtrGnrtr5InvrtrRtLmtsRqst1CRC "Motor/Generator 5 Inverter Rate Limits Request 1 CRC: The CRC is defined as follows:• Length: 8 bits• Polynomial: x^8+x^5+x^3+x^2+x+1• Initial Value: FFh• Input Data Reflection: Not reflected• Result Data Reflection: Not reflected• XOR value: FFhSAE ...";
CM_ SG_ 2566000126 MtrGnrtr5InvrtrRtLmtsRqst1Cntr "Motor/Generator 5 Inverter Rate Limits Request 1 Counter: The message counter is used to detect situations where the transmitting ECU malfunction repeats the same frame all the time. The receiver of the information may use the counter parameter to de...";
CM_ SG_ 2566000126 MtGt5IvtRtLtsRqstAstSpdRtLt "Motor/Generator 5 Inverter Rate Limits Request Absolute Speed Rate Limit: The maximum rate of change for the absolute motor speed  (i.e. |d(speed)|/dt) in all control modes. This limit shall solely lead to reducing the absolute torque, not increasing...";
CM_ SG_ 2566000126 MtGt5IvtRtLtsRqstAstTqRtLt "Motor/Generator 5 Inverter Rate Limits Request Absolute Torque Rate Limit: The maximum rate of change for the absolute motor torque (i.e. |d(torque)|/dt) in all control modes. Refer to SPN 12057 [Reference Torque] to convert %/sec to Nm/sec. Request ...";
CM_ BO_ 2364673790 "Motor/Generator 6 Inverter Control";
CM_ SG_ 2364673790 MtrGnrtr6InvrtrCntrlCRC "Motor/Generator 6 Inverter Control CRC: The CRC is defined as follows:• Length: 8 bits• Polynomial: x^8+x^5+x^3+x^2+x+1• Initial Value: FFh• Input Data Reflection: Not reflected• Result Data Reflection: Not reflected• XOR value: FFhSAE makes no claim...";
CM_ SG_ 2364673790 MtrGnrtr6InvrtrCntrlCntr "Motor/Generator 6 Inverter Control Counter: The message counter is used to detect situations where the transmitting ECU malfunction repeats the same frame all the time. The receiver of the information may use the counter parameter to detect this situ...";
CM_ SG_ 2364673790 MtGt6IvtCtLtsRqstOvdMd "Motor/Generator 6 Inverter Control Limits Request Override Mode: This parameter provides a way to temporarily override limits that are being received by the inverter in other messages.  It allows a specific type of limit to be transmitted at a high r...";
CM_ SG_ 2364673790 MtGt6IvtCtLtsRqstOvdMx "Motor/Generator 6 Inverter Control Limits Request Override Maximum: The Maximum limit requested by this parameter depends on the value of SPN 12164 [Control Limits Request Override Mode].In normal operating conditions, the inverter operating limits a...";
CM_ SG_ 2364673790 MtGt6IvtCtLtsRqstOvdM "Motor/Generator 6 Inverter Control Limits Request Override Minimum : The Minimum limit requested by this parameter depends on the value of SPN 12164 [Control Limits Request Override Mode].In normal operating conditions, the inverter operating limits ...";
CM_ SG_ 2364673790 MtrGnrtr6InvrtrCntrlStpntMdRqst "Motor/Generator 6 Inverter Control Setpoint Mode Request: Requests the modes for this instance of the inverter.  See SPN 12172 [Control Setpoint Mode] for the feedback to this request.Passive modes:  Modes where the inverter does not actively control...";
CM_ SG_ 2364673790 MtrGnrtr6InvrtrCntrlStpntRqst "Motor/Generator 6 Inverter Control Setpoint Request: Requests the set point for this inverter.  The type of set point requested by this parameter depends on the value of SPN 12167 [Control Setpoint Mode Request] as follows:Passive Modes: In any Passi...";
CM_ BO_ 2566000638 "Motor/Generator 6 Inverter Rate Limits Request 1";
CM_ SG_ 2566000638 MtrGnrtr6InvrtrRtLmtsRqst1CRC "Motor/Generator 6 Inverter Rate Limits Request 1 CRC: The CRC is defined as follows:• Length: 8 bits• Polynomial: x^8+x^5+x^3+x^2+x+1• Initial Value: FFh• Input Data Reflection: Not reflected• Result Data Reflection: Not reflected• XOR value: FFhSAE ...";
CM_ SG_ 2566000638 MtrGnrtr6InvrtrRtLmtsRqst1Cntr "Motor/Generator 6 Inverter Rate Limits Request 1 Counter: The message counter is used to detect situations where the transmitting ECU malfunction repeats the same frame all the time. The receiver of the information may use the counter parameter to de...";
CM_ SG_ 2566000638 MtGt6IvtRtLtsRqstAstSpdRtLt "Motor/Generator 6 Inverter Rate Limits Request Absolute Speed Rate Limit: The maximum rate of change for the absolute motor speed  (i.e. |d(speed)|/dt) in all control modes. This limit shall solely lead to reducing the absolute torque, not increasing...";
CM_ SG_ 2566000638 MtGt6IvtRtLtsRqstAstTqRtLt "Motor/Generator 6 Inverter Rate Limits Request Absolute Torque Rate Limit: The maximum rate of change for the absolute motor torque (i.e. |d(torque)|/dt) in all control modes. Refer to SPN 12175 [Reference Torque] to convert %/sec to Nm/sec. Request ...";
CM_ BO_ 2566574078 "EVCC1 Diagnostic Data 1";
CM_ SG_ 2566574078 EVCC1ControlPilotmaximumvoltage "EVCC1 Control Pilot maximum voltage: The control pilot from the off-board EVSE is either a DC signal or a square wave. This parameter contains the DC value or the maximum voltage of the square wave.";
CM_ SG_ 2566574078 EVCC1ControlPilotminimumvoltage "EVCC1 Control Pilot minimum voltage: The control pilot from the off-board EVSE is either a DC signal or a square wave. This parameter contains the DC value or the minimum voltage of the square wave.";
CM_ SG_ 2566574078 EVCC1ControlPilotPWMfrequency "EVCC1 Control Pilot PWM frequency: The control pilot from the off-board EVSE is either a DC signal or a square wave. This parameter contains either zero when a DC value or the frequency when a square wave.";
CM_ SG_ 2566574078 EVCC1ControlPilotDutyCycle "EVCC1 Control Pilot Duty Cycle: The control pilot from the off-board EVSE is either a DC signal or a square wave. This parameter contains the duty cycle of the PWM square wave. ";
CM_ SG_ 2566574078 EVCC1ControlPilotState "EVCC1 Control Pilot State: Indicates the EVSE state as determined by the peak voltage level of the Control Pilot and representing states A to F as defined by IEC-61851 and J1772.0000b = State A, EVSE Disconnected0001b = State B, EVSE Connected, Power...";
CM_ SG_ 2566574078 EVCC1ControlPilotSubState "EVCC1 Control Pilot Sub-State: Indicates the EVSE sub-state as determined by the frequency of the Control Pilot as defined by IEC-61851 and J1772.0000b = Sub-state 1 - DC Level, EVSE not ready/able to enable power0001b = Sub-state 2 - Valid PWM, EVSE...";
CM_ SG_ 2566574078 EVCC1Proximitycircuitvoltage "EVCC1 Proximity circuit voltage: The cable from the EVSE may contain a resistive proximity circuit.  Resistors are built into both the cable and inlet sides of the connectors and are supplied from a DC source.The voltage interpretation will depend on...";
CM_ SG_ 2566574078 EVCC1Inletconnectortemperature "EVCC1 Inlet connector temperature: Temperature reading at the vehicle inlet connector.";
CM_ SG_ 2566574078 EVCC1CompatibilityCode "EVCC1 Compatibility Code: Indicates incompatability between the vehicle and the EVSE.0000b = EVSE is compatible0001b = Digital Communications. The EVSE has attempted to establish commuications but the protocol is not supported by the EVCC.0010b = Ven...";
CM_ BO_ 2499465470 "Cab Door Control 2";
CM_ SG_ 2499465470 Mirror1LeftRightSelection "Mirror 1 Left/Right Selection: Indicates the position of a switch that selects between left or right mirror control. Signal may be used to provide visual indication of selected mirror.000b = No Mirror Selected (Neutral Position)001b = Mirror 1 Left S...";
CM_ SG_ 2499465470 Mirror2LeftRightSelection "Mirror 2 Left/Right Selection: Indicates the position of a switch that selects between left or right mirror control. Signal may be used to provide visual indication of selected mirror.000b = No Mirror Selected (Neutral Position)001b = Mirror 2 Left S...";
CM_ SG_ 2499465470 MirrorPrimarySecondarySelection "Mirror Primary/Secondary Selection: Indicates the position of a switch that selects between primary and secondary mirror sets. Signal may be used to provide visual indication of selected mirror.000b = No Mirror Selected (Neutral Position)001b = Prima...";
CM_ BO_ 2499465726 "Engine Average Information 2";
CM_ SG_ 2499465726 EngnClndrTmprtrAvrg "Engine Cylinder Temperature Average: The calculated average temperature based upon all of the engine cylinder temperatures measured at the head of each cylinder. This is the average temperature based upon the measurements in each of the engine cylind...";
CM_ SG_ 2499465726 EngnClndrBnk1TmprtrAvrg "Engine Cylinder Bank 1 Temperature Average: The calculated average temperature based upon all of the Bank 1 (left bank) engine cylinders measured at the head of each cylinder. This is the average temperature measurement of each of the engine cylinder...";
CM_ SG_ 2499465726 EngnClndrBnk2TmprtrAvrg "Engine Cylinder Bank 2 Temperature Average: The calculated average temperature based upon all of the Bank 2 (right bank) engine cylinders measured at the head of each cylinder. This is the average temperature measurement of each of the engine cylinde...";
BA_DEF_ SG_  "SPN" INT 0 524287;
BA_DEF_ BO_  "VFrameFormat" ENUM  "StandardCAN","ExtendedCAN","reserved","J1939PG";
BA_DEF_DEF_  "SPN" 0;
BA_DEF_DEF_  "VFrameFormat" "J1939PG";
BA_ "SPN" SG_ 2364656894 HVESP5DshrgPwrLmtDtSttfChrg 11502;
BA_ "SPN" SG_ 2364656894 HVESP5DshrgPwrLmtDtBttrTmprtr 11503;
BA_ "SPN" SG_ 2364656894 HVESP5DsPwLtDtBttDstCdt 11504;
BA_ "SPN" SG_ 2364656894 HVESP5DshrgPwrLmtDtBttrrCllVltg 11505;
BA_ "SPN" SG_ 2364656894 HVESP5DshrgPwrLmtDtBttrCrrnt 11506;
BA_ "SPN" SG_ 2364656894 HVESP5DshrgPwrLmtDtnUndfndCs 11507;
BA_ "SPN" SG_ 2364656894 HVESP5ChrgPwrLmtDtSttfChrg 11508;
BA_ "SPN" SG_ 2364656894 HVESP5ChrgPwrLmtDtBttrTmprtr 11509;
BA_ "SPN" SG_ 2364656894 HVESP5CPwLtDtBttDstCdt 11510;
BA_ "SPN" SG_ 2364656894 HVESP5ChrgPwrLmtDtBttrrCllVltg 11511;
BA_ "SPN" SG_ 2364656894 HVESP5ChrgPwrLmtDtBttrCrrnt 11512;
BA_ "SPN" SG_ 2364656894 HVESP5ChrgPwrLmtDtnUndfndCs 11513;
BA_ "SPN" SG_ 2364657150 HVESP5AvailableDischargePower 11514;
BA_ "SPN" SG_ 2364657150 HVESP5AvailableChargePower 11515;
BA_ "SPN" SG_ 2364657150 HVESP5VoltageLevel 11516;
BA_ "SPN" SG_ 2364657150 HVESP5Current 11517;
BA_ "SPN" SG_ 2364657406 HVESP5FastUpdateStateofCharge 11518;
BA_ "SPN" SG_ 2364657406 HVESP5HighestCellVoltage 11519;
BA_ "SPN" SG_ 2364657406 HVESP5LowestCellVoltage 11520;
BA_ "SPN" SG_ 2364657406 HVESP5CllVltgDffrntlStts 11521;
BA_ "SPN" SG_ 2364657662 HVESP5HighestCellTemperature 11522;
BA_ "SPN" SG_ 2364657662 HVESP5LowestCellTemperature 11523;
BA_ "SPN" SG_ 2364657662 HVESP5AverageCellTemperature 11524;
BA_ "SPN" SG_ 2364657662 HVESP5CllTmprtrDffrntlStts 11525;
BA_ "SPN" SG_ 2364657918 HVESP5DischargeCapacity 11526;
BA_ "SPN" SG_ 2364657918 HVESP5ChargeCapacity 11527;
BA_ "SPN" SG_ 2364657918 HVESP5CellBalancingCount 11528;
BA_ "SPN" SG_ 2364658174 HVESP5DischargeCurrentLimit 11529;
BA_ "SPN" SG_ 2364658174 HVESP5ChargeCurrentLimit 11530;
BA_ "SPN" SG_ 2364658174 HVESP5LowestCellStateofCharge 11531;
BA_ "SPN" SG_ 2364658174 HVESP5HighestCellStateofCharge 11532;
BA_ "SPN" SG_ 2364658430 HVESP5BusVoltage 11533;
BA_ "SPN" SG_ 2364658430 HVESP5IgnitionVoltage 11534;
BA_ "SPN" SG_ 2364658430 HVESP5IntakeCoolantTemperature 11535;
BA_ "SPN" SG_ 2364658430 HVESP5OutletCoolantTemperature 11536;
BA_ "SPN" SG_ 2364658430 HVESP5ElectronicsTemperature 11537;
BA_ "SPN" SG_ 2364658430 HVESP5Temperature 11538;
BA_ "SPN" SG_ 2364658686 HVESP5HghVltgBsPstvCnttrStt 11539;
BA_ "SPN" SG_ 2364658686 HVESP5HghVltgBsNgtvCnttrStt 11540;
BA_ "SPN" SG_ 2364658686 HVESP5HghVltgBsDsnntFrwrnng 11541;
BA_ "SPN" SG_ 2364658686 HVESP5HghVltgBsPrChrgRlStt 11542;
BA_ "SPN" SG_ 2364658686 HVESP5CntrfPkCnttrStt 11543;
BA_ "SPN" SG_ 2364658686 HVESP5HghVltgBsAtvIsltnTstStts 11544;
BA_ "SPN" SG_ 2364658686 HVESP5HghVltgBsPssvIsltnTstStts 11545;
BA_ "SPN" SG_ 2364658686 HVESP5HVILStatus 11546;
BA_ "SPN" SG_ 2364658686 HVESP5InertiaSwitchStatus 11547;
BA_ "SPN" SG_ 2364658686 HVESP5StateofChargeStatus 11548;
BA_ "SPN" SG_ 2364658686 HVESP5CellBalanceStatus 11549;
BA_ "SPN" SG_ 2364658686 HVESP5CellBalancingActive 11550;
BA_ "SPN" SG_ 2364658686 HVESP5InternalChargerStatus 11551;
BA_ "SPN" SG_ 2364658686 HVESP5HghVltgBsCnntnStts 11552;
BA_ "SPN" SG_ 2364658686 HVESP5OperationalStatus 11553;
BA_ "SPN" SG_ 2364658686 HVESP5Status1Counter 13023;
BA_ "SPN" SG_ 2364658686 HVESP5Status1CRC 13024;
BA_ "SPN" SG_ 2364658942 HVESP5DischargeEnergyCapacity 11554;
BA_ "SPN" SG_ 2364658942 HVESP5ChargeEnergyCapacity 11555;
BA_ "SPN" SG_ 2364658942 HVESP5MaximumChargeVoltageLimit 11556;
BA_ "SPN" SG_ 2364659198 HVESP5Module1OperationalStatus 11557;
BA_ "SPN" SG_ 2364659198 HVESP5Module2OperationalStatus 11558;
BA_ "SPN" SG_ 2364659198 HVESP5Module3OperationalStatus 11559;
BA_ "SPN" SG_ 2364659198 HVESP5Module4OperationalStatus 11560;
BA_ "SPN" SG_ 2364659198 HVESP5Module5OperationalStatus 11561;
BA_ "SPN" SG_ 2364659198 HVESP5Module6OperationalStatus 11562;
BA_ "SPN" SG_ 2364659198 HVESP5Module7OperationalStatus 11563;
BA_ "SPN" SG_ 2364659198 HVESP5Module8OperationalStatus 11564;
BA_ "SPN" SG_ 2364659198 HVESP5Module9OperationalStatus 11565;
BA_ "SPN" SG_ 2364659198 HVESP5Module10OperationalStatus 11566;
BA_ "SPN" SG_ 2364659198 HVESP5Module11OperationalStatus 11567;
BA_ "SPN" SG_ 2364659198 HVESP5Module12OperationalStatus 11568;
BA_ "SPN" SG_ 2364659198 HVESP5Module13OperationalStatus 11569;
BA_ "SPN" SG_ 2364659198 HVESP5Module14OperationalStatus 11570;
BA_ "SPN" SG_ 2364659198 HVESP5Module15OperationalStatus 11571;
BA_ "SPN" SG_ 2364659198 HVESP5Module16OperationalStatus 11572;
BA_ "SPN" SG_ 2364659198 HVESP5Module17OperationalStatus 14689;
BA_ "SPN" SG_ 2364659198 HVESP5Module18OperationalStatus 14690;
BA_ "SPN" SG_ 2364659198 HVESP5Module19OperationalStatus 14691;
BA_ "SPN" SG_ 2364659198 HVESP5Module20OperationalStatus 14692;
BA_ "SPN" SG_ 2364659198 HVESP5Module21OperationalStatus 14693;
BA_ "SPN" SG_ 2364659198 HVESP5Module22OperationalStatus 14694;
BA_ "SPN" SG_ 2364659198 HVESP5Module23OperationalStatus 14695;
BA_ "SPN" SG_ 2364659198 HVESP5Module24OperationalStatus 14696;
BA_ "SPN" SG_ 2364659198 HVESP5Module25OperationalStatus 14697;
BA_ "SPN" SG_ 2364659198 HVESP5Module26OperationalStatus 14698;
BA_ "SPN" SG_ 2364659198 HVESP5Module27OperationalStatus 14699;
BA_ "SPN" SG_ 2364659198 HVESP5Module28OperationalStatus 14700;
BA_ "SPN" SG_ 2364659198 HVESP5Module29OperationalStatus 14701;
BA_ "SPN" SG_ 2364659198 HVESP5Module30OperationalStatus 14702;
BA_ "SPN" SG_ 2364659198 HVESP5Module31OperationalStatus 14703;
BA_ "SPN" SG_ 2364659198 HVESP5Module32OperationalStatus 14704;
BA_ "SPN" SG_ 2364659454 HVESP5ThrmlMngmntSstmSLIInptPwr 11573;
BA_ "SPN" SG_ 2364659454 HVESP5TMtSstHVtIptPw 11574;
BA_ "SPN" SG_ 2364659454 HVESP5ThrmlMngmntSstmCmprssrSpd 11575;
BA_ "SPN" SG_ 2364659454 HVESP5ThrmlMngmntSstmRltvHmdt 11576;
BA_ "SPN" SG_ 2364659454 HVESP5ThrmlMngmntSstmHtrStts 11577;
BA_ "SPN" SG_ 2364659454 HVESP5ThrmlMngmntSstmHVILStts 12815;
BA_ "SPN" SG_ 2364659454 HVESP5ThrmlMngmntSstmMd 11578;
BA_ "SPN" SG_ 2364659454 HVESP5ThrmlMngmntSstmClntLvl 12902;
BA_ "SPN" SG_ 2364659710 HVESP5HghstCllVltgMdlNmr 11579;
BA_ "SPN" SG_ 2364659710 HVESP5HghstCllVltgCllNmr 11580;
BA_ "SPN" SG_ 2364659710 HVESP5LwstCllVltgMdlNmr 11581;
BA_ "SPN" SG_ 2364659710 HVESP5LwstCllVltgCllNmr 11582;
BA_ "SPN" SG_ 2364659710 HVESP5AverageCellVoltage 11583;
BA_ "SPN" SG_ 2364659966 HVESP5HghstCllTmprtrMdlNmr 11584;
BA_ "SPN" SG_ 2364659966 HVESP5HghstCllTmprtrCllNmr 11585;
BA_ "SPN" SG_ 2364659966 HVESP5LwstCllTmprtrMdlNmr 11586;
BA_ "SPN" SG_ 2364659966 HVESP5LwstCllTmprtrCllNmr 11587;
BA_ "SPN" SG_ 2364660222 HVESP5HghstCllSttfChrgMdlNmr 11588;
BA_ "SPN" SG_ 2364660222 HVESP5HghstCllSttfChrgCllNmr 11589;
BA_ "SPN" SG_ 2364660222 HVESP5LwstCllSttfChrgMdlNmr 11590;
BA_ "SPN" SG_ 2364660222 HVESP5LwstCllSttfChrgCllNmr 11591;
BA_ "SPN" SG_ 2364660222 HVESP5HghVltgBsAtvIsltnTstRslts 11592;
BA_ "SPN" SG_ 2364660222 HVESP5HVtBsPssvIstTstRsts 11593;
BA_ "SPN" SG_ 2364660478 HVESP5BsVltgNgtvtChsssGrndVltg 11594;
BA_ "SPN" SG_ 2364660478 HVESP5VltgLvlNgtvtChsssGrndVltg 11595;
BA_ "SPN" SG_ 2364660478 HVESP5ActualChargeRate 13069;
BA_ "SPN" SG_ 2364660734 HVESP6DshrgPwrLmtDtSttfChrg 11618;
BA_ "SPN" SG_ 2364660734 HVESP6DshrgPwrLmtDtBttrTmprtr 11619;
BA_ "SPN" SG_ 2364660734 HVESP6DsPwLtDtBttDstCdt 11620;
BA_ "SPN" SG_ 2364660734 HVESP6DshrgPwrLmtDtBttrrCllVltg 11621;
BA_ "SPN" SG_ 2364660734 HVESP6DshrgPwrLmtDtBttrCrrnt 11622;
BA_ "SPN" SG_ 2364660734 HVESP6DshrgPwrLmtDtnUndfndCs 11623;
BA_ "SPN" SG_ 2364660734 HVESP6ChrgPwrLmtDtSttfChrg 11624;
BA_ "SPN" SG_ 2364660734 HVESP6ChrgPwrLmtDtBttrTmprtr 11625;
BA_ "SPN" SG_ 2364660734 HVESP6CPwLtDtBttDstCdt 11626;
BA_ "SPN" SG_ 2364660734 HVESP6ChrgPwrLmtDtBttrrCllVltg 11627;
BA_ "SPN" SG_ 2364660734 HVESP6ChrgPwrLmtDtBttrCrrnt 11628;
BA_ "SPN" SG_ 2364660734 HVESP6ChrgPwrLmtDtnUndfndCs 11629;
BA_ "SPN" SG_ 2364660990 HVESP6AvailableDischargePower 11630;
BA_ "SPN" SG_ 2364660990 HVESP6AvailableChargePower 11631;
BA_ "SPN" SG_ 2364660990 HVESP6VoltageLevel 11632;
BA_ "SPN" SG_ 2364660990 HVESP6Current 11633;
BA_ "SPN" SG_ 2364661246 HVESP6FastUpdateStateofCharge 11634;
BA_ "SPN" SG_ 2364661246 HVESP6HighestCellVoltage 11635;
BA_ "SPN" SG_ 2364661246 HVESP6LowestCellVoltage 11636;
BA_ "SPN" SG_ 2364661246 HVESP6CllVltgDffrntlStts 11637;
BA_ "SPN" SG_ 2364661502 HVESP6HighestCellTemperature 11638;
BA_ "SPN" SG_ 2364661502 HVESP6LowestCellTemperature 11639;
BA_ "SPN" SG_ 2364661502 HVESP6AverageCellTemperature 11640;
BA_ "SPN" SG_ 2364661502 HVESP6CllTmprtrDffrntlStts 11641;
BA_ "SPN" SG_ 2364661758 HVESP6DischargeCapacity 11642;
BA_ "SPN" SG_ 2364661758 HVESP6ChargeCapacity 11643;
BA_ "SPN" SG_ 2364661758 HVESP6CellBalancingCount 11644;
BA_ "SPN" SG_ 2364662014 HVESP6DischargeCurrentLimit 11645;
BA_ "SPN" SG_ 2364662014 HVESP6ChargeCurrentLimit 11646;
BA_ "SPN" SG_ 2364662014 HVESP6LowestCellStateofCharge 11647;
BA_ "SPN" SG_ 2364662014 HVESP6HighestCellStateofCharge 11648;
BA_ "SPN" SG_ 2364662270 HVESP6BusVoltage 11649;
BA_ "SPN" SG_ 2364662270 HVESP6IgnitionVoltage 11650;
BA_ "SPN" SG_ 2364662270 HVESP6IntakeCoolantTemperature 11651;
BA_ "SPN" SG_ 2364662270 HVESP6OutletCoolantTemperature 11652;
BA_ "SPN" SG_ 2364662270 HVESP6ElectronicsTemperature 11653;
BA_ "SPN" SG_ 2364662270 HVESP6Temperature 11654;
BA_ "SPN" SG_ 2364662526 HVESP6HghVltgBsPstvCnttrStt 11655;
BA_ "SPN" SG_ 2364662526 HVESP6HghVltgBsNgtvCnttrStt 11656;
BA_ "SPN" SG_ 2364662526 HVESP6HghVltgBsDsnntFrwrnng 11657;
BA_ "SPN" SG_ 2364662526 HVESP6HghVltgBsPrChrgRlStt 11658;
BA_ "SPN" SG_ 2364662526 HVESP6CntrfPkCnttrStt 11659;
BA_ "SPN" SG_ 2364662526 HVESP6HghVltgBsAtvIsltnTstStts 11660;
BA_ "SPN" SG_ 2364662526 HVESP6HghVltgBsPssvIsltnTstStts 11661;
BA_ "SPN" SG_ 2364662526 HVESP6HVILStatus 11662;
BA_ "SPN" SG_ 2364662526 HVESP6InertiaSwitchStatus 11663;
BA_ "SPN" SG_ 2364662526 HVESP6StateofChargeStatus 11664;
BA_ "SPN" SG_ 2364662526 HVESP6CellBalanceStatus 11665;
BA_ "SPN" SG_ 2364662526 HVESP6CellBalancingActive 11666;
BA_ "SPN" SG_ 2364662526 HVESP6InternalChargerStatus 11667;
BA_ "SPN" SG_ 2364662526 HVESP6HghVltgBsCnntnStts 11668;
BA_ "SPN" SG_ 2364662526 HVESP6OperationalStatus 11669;
BA_ "SPN" SG_ 2364662526 HVESP6Status1Counter 13025;
BA_ "SPN" SG_ 2364662526 HVESP6Status1CRC 13026;
BA_ "SPN" SG_ 2364662782 HVESP6DischargeEnergyCapacity 11670;
BA_ "SPN" SG_ 2364662782 HVESP6ChargeEnergyCapacity 11671;
BA_ "SPN" SG_ 2364662782 HVESP6MaximumChargeVoltageLimit 11672;
BA_ "SPN" SG_ 2364663038 HVESP6Module1OperationalStatus 11673;
BA_ "SPN" SG_ 2364663038 HVESP6Module2OperationalStatus 11674;
BA_ "SPN" SG_ 2364663038 HVESP6Module3OperationalStatus 11675;
BA_ "SPN" SG_ 2364663038 HVESP6Module4OperationalStatus 11676;
BA_ "SPN" SG_ 2364663038 HVESP6Module5OperationalStatus 11677;
BA_ "SPN" SG_ 2364663038 HVESP6Module6OperationalStatus 11678;
BA_ "SPN" SG_ 2364663038 HVESP6Module7OperationalStatus 11679;
BA_ "SPN" SG_ 2364663038 HVESP6Module8OperationalStatus 11680;
BA_ "SPN" SG_ 2364663038 HVESP6Module9OperationalStatus 11681;
BA_ "SPN" SG_ 2364663038 HVESP6Module10OperationalStatus 11682;
BA_ "SPN" SG_ 2364663038 HVESP6Module11OperationalStatus 11683;
BA_ "SPN" SG_ 2364663038 HVESP6Module12OperationalStatus 11684;
BA_ "SPN" SG_ 2364663038 HVESP6Module13OperationalStatus 11685;
BA_ "SPN" SG_ 2364663038 HVESP6Module14OperationalStatus 11686;
BA_ "SPN" SG_ 2364663038 HVESP6Module15OperationalStatus 11687;
BA_ "SPN" SG_ 2364663038 HVESP6Module16OperationalStatus 11688;
BA_ "SPN" SG_ 2364663038 HVESP6Module17OperationalStatus 14705;
BA_ "SPN" SG_ 2364663038 HVESP6Module18OperationalStatus 14706;
BA_ "SPN" SG_ 2364663038 HVESP6Module19OperationalStatus 14707;
BA_ "SPN" SG_ 2364663038 HVESP6Module20OperationalStatus 14708;
BA_ "SPN" SG_ 2364663038 HVESP6Module21OperationalStatus 14709;
BA_ "SPN" SG_ 2364663038 HVESP6Module22OperationalStatus 14710;
BA_ "SPN" SG_ 2364663038 HVESP6Module23OperationalStatus 14711;
BA_ "SPN" SG_ 2364663038 HVESP6Module24OperationalStatus 14712;
BA_ "SPN" SG_ 2364663038 HVESP6Module25OperationalStatus 14713;
BA_ "SPN" SG_ 2364663038 HVESP6Module26OperationalStatus 14714;
BA_ "SPN" SG_ 2364663038 HVESP6Module27OperationalStatus 14715;
BA_ "SPN" SG_ 2364663038 HVESP6Module28OperationalStatus 14716;
BA_ "SPN" SG_ 2364663038 HVESP6Module29OperationalStatus 14717;
BA_ "SPN" SG_ 2364663038 HVESP6Module30OperationalStatus 14718;
BA_ "SPN" SG_ 2364663038 HVESP6Module31OperationalStatus 14719;
BA_ "SPN" SG_ 2364663038 HVESP6Module32OperationalStatus 14720;
BA_ "SPN" SG_ 2364663294 HVESP6ThrmlMngmntSstmSLIInptPwr 11689;
BA_ "SPN" SG_ 2364663294 HVESP6TMtSstHVtIptPw 11690;
BA_ "SPN" SG_ 2364663294 HVESP6ThrmlMngmntSstmCmprssrSpd 11691;
BA_ "SPN" SG_ 2364663294 HVESP6ThrmlMngmntSstmRltvHmdt 11692;
BA_ "SPN" SG_ 2364663294 HVESP6ThrmlMngmntSstmHtrStts 11693;
BA_ "SPN" SG_ 2364663294 HVESP6ThrmlMngmntSstmHVILStts 12814;
BA_ "SPN" SG_ 2364663294 HVESP6ThrmlMngmntSstmMd 11694;
BA_ "SPN" SG_ 2364663294 HVESP6ThrmlMngmntSstmClntLvl 12903;
BA_ "SPN" SG_ 2364663550 HVESP6HghstCllVltgMdlNmr 11695;
BA_ "SPN" SG_ 2364663550 HVESP6HghstCllVltgCllNmr 11696;
BA_ "SPN" SG_ 2364663550 HVESP6LwstCllVltgMdlNmr 11697;
BA_ "SPN" SG_ 2364663550 HVESP6LwstCllVltgCllNmr 11698;
BA_ "SPN" SG_ 2364663550 HVESP6AverageCellVoltage 11699;
BA_ "SPN" SG_ 2364663806 HVESP6HghstCllTmprtrMdlNmr 11700;
BA_ "SPN" SG_ 2364663806 HVESP6HghstCllTmprtrCllNmr 11701;
BA_ "SPN" SG_ 2364663806 HVESP6LwstCllTmprtrMdlNmr 11702;
BA_ "SPN" SG_ 2364663806 HVESP6LwstCllTmprtrCllNmr 11703;
BA_ "SPN" SG_ 2364664062 HVESP6HghstCllSttfChrgMdlNmr 11704;
BA_ "SPN" SG_ 2364664062 HVESP6HghstCllSttfChrgCllNmr 11705;
BA_ "SPN" SG_ 2364664062 HVESP6LwstCllSttfChrgMdlNmr 11706;
BA_ "SPN" SG_ 2364664062 HVESP6LwstCllSttfChrgCllNmr 11707;
BA_ "SPN" SG_ 2364664062 HVESP6HghVltgBsAtvIsltnTstRslts 11708;
BA_ "SPN" SG_ 2364664062 HVESP6HVtBsPssvIstTstRsts 11709;
BA_ "SPN" SG_ 2364664318 HVESP6BsVltgNgtvtChsssGrndVltg 11710;
BA_ "SPN" SG_ 2364664318 HVESP6VltgLvlNgtvtChsssGrndVltg 11711;
BA_ "SPN" SG_ 2364664318 HVESP6ActualChargeRate 13070;
BA_ "SPN" SG_ 2364664574 MtrGnrtr3InvrtrMdFdk1CRC 11815;
BA_ "SPN" SG_ 2364664574 MtrGnrtr3InvrtrMdFdk1Cntr 11816;
BA_ "SPN" SG_ 2364664574 MtrGnrtr3InvrtrCntrlLmtsOvrrdMd 11817;
BA_ "SPN" SG_ 2364664574 MtrGnrtr3InvrtrCntrlStpntMd 11818;
BA_ "SPN" SG_ 2364664574 MtrGnrtr3InvrtrHVILStts 11805;
BA_ "SPN" SG_ 2565991422 MtrGnrtr3InvrtrLmtsAtvPwrCRC 11833;
BA_ "SPN" SG_ 2565991422 MtrGnrtr3InvrtrLmtsAtvPwrCntr 11834;
BA_ "SPN" SG_ 2565991422 MtGt3IvtLtsAtvMPwMx 11835;
BA_ "SPN" SG_ 2565991422 MtGt3IvtLtsAtvMPwM 11836;
BA_ "SPN" SG_ 2565991422 MtGt3IvtLtsAtvDCSdPwMx 11837;
BA_ "SPN" SG_ 2565991422 MtGt3IvtLtsAtvDCSdPwM 11838;
BA_ "SPN" SG_ 2565991678 MtrGnrtr3InvrtrLmtsAtvMhnlCRC 11845;
BA_ "SPN" SG_ 2565991678 MtrGnrtr3InvrtrLmtsAtvMhnlCntr 11846;
BA_ "SPN" SG_ 2565991678 MtrGnrtr3InvrtrLmtsAtvTrqMxmm 11847;
BA_ "SPN" SG_ 2565991678 MtrGnrtr3InvrtrLmtsAtvTrqMnmm 11848;
BA_ "SPN" SG_ 2565991678 MtrGnrtr3InvrtrLmtsAtvSpdMxmm 11849;
BA_ "SPN" SG_ 2565991678 MtrGnrtr3InvrtrLmtsAtvSpdMnmm 11850;
BA_ "SPN" SG_ 2565991934 MtrGnrtr3InvrtrLmtsAtvDCSdCRC 11861;
BA_ "SPN" SG_ 2565991934 MtrGnrtr3InvrtrLmtsAtvDCSdCntr 11862;
BA_ "SPN" SG_ 2565991934 MtGt3IvtLtsAtvDCSdVtMx 11863;
BA_ "SPN" SG_ 2565991934 MtGt3IvtLtsAtvDCSdVtM 11864;
BA_ "SPN" SG_ 2565991934 MtGt3IvtLtsAtvDCSdCtMx 11865;
BA_ "SPN" SG_ 2565991934 MtGt3IvtLtsAtvDCSdCtM 11866;
BA_ "SPN" SG_ 2565992190 MtrGnrtr3InvrtrSwthdIgntnVltg 11806;
BA_ "SPN" SG_ 2565992190 MtrGnrtr3InvrtrUnswthdSLIVltg 11807;
BA_ "SPN" SG_ 2565992446 MtrGnrtr3InvrtrStts2CRC 11874;
BA_ "SPN" SG_ 2565992446 MtrGnrtr3InvrtrStts2Cntr 11875;
BA_ "SPN" SG_ 2565992446 MtrGnrtr3AvllMxmmTrq 11876;
BA_ "SPN" SG_ 2565992446 MtrGnrtr3AvllMnmmTrq 11877;
BA_ "SPN" SG_ 2565992702 MtrGnrtr3InvrtrRtLmtsAtv1CRC 11908;
BA_ "SPN" SG_ 2565992702 MtrGnrtr3InvrtrRtLmtsAtv1Cntr 11909;
BA_ "SPN" SG_ 2565992702 MtGt3IvtRtLtsAtvAstSpdRtLt 11910;
BA_ "SPN" SG_ 2565992702 MtGt3IvtRtLtsAtvAstTqRtLt 11911;
BA_ "SPN" SG_ 2364666366 MtrGnrtr4InvrtrMdFdk1CRC 11933;
BA_ "SPN" SG_ 2364666366 MtrGnrtr4InvrtrMdFdk1Cntr 11934;
BA_ "SPN" SG_ 2364666366 MtrGnrtr4InvrtrCntrlLmtsOvrrdMd 11935;
BA_ "SPN" SG_ 2364666366 MtrGnrtr4InvrtrCntrlStpntMd 11936;
BA_ "SPN" SG_ 2364666366 MtrGnrtr4InvrtrHVILStts 11923;
BA_ "SPN" SG_ 2565993214 MtrGnrtr4InvrtrLmtsAtvPwrCRC 11951;
BA_ "SPN" SG_ 2565993214 MtrGnrtr4InvrtrLmtsAtvPwrCntr 11952;
BA_ "SPN" SG_ 2565993214 MtGt4IvtLtsAtvMPwMx 11953;
BA_ "SPN" SG_ 2565993214 MtGt4IvtLtsAtvMPwM 11954;
BA_ "SPN" SG_ 2565993214 MtGt4IvtLtsAtvDCSdPwMx 11955;
BA_ "SPN" SG_ 2565993214 MtGt4IvtLtsAtvDCSdPwM 11956;
BA_ "SPN" SG_ 2565993470 MtrGnrtr4InvrtrLmtsAtvMhnlCRC 11963;
BA_ "SPN" SG_ 2565993470 MtrGnrtr4InvrtrLmtsAtvMhnlCntr 11964;
BA_ "SPN" SG_ 2565993470 MtrGnrtr4InvrtrLmtsAtvTrqMxmm 11965;
BA_ "SPN" SG_ 2565993470 MtrGnrtr4InvrtrLmtsAtvTrqMnmm 11966;
BA_ "SPN" SG_ 2565993470 MtrGnrtr4InvrtrLmtsAtvSpdMxmm 11967;
BA_ "SPN" SG_ 2565993470 MtrGnrtr4InvrtrLmtsAtvSpdMnmm 11968;
BA_ "SPN" SG_ 2565993726 MtrGnrtr4InvrtrLmtsAtvDCSdCRC 11979;
BA_ "SPN" SG_ 2565993726 MtrGnrtr4InvrtrLmtsAtvDCSdCntr 11980;
BA_ "SPN" SG_ 2565993726 MtGt4IvtLtsAtvDCSdVtMx 11981;
BA_ "SPN" SG_ 2565993726 MtGt4IvtLtsAtvDCSdVtM 11982;
BA_ "SPN" SG_ 2565993726 MtGt4IvtLtsAtvDCSdCtMx 11983;
BA_ "SPN" SG_ 2565993726 MtGt4IvtLtsAtvDCSdCtM 11984;
BA_ "SPN" SG_ 2565993982 MtrGnrtr4InvrtrSwthdIgntnVltg 11924;
BA_ "SPN" SG_ 2565993982 MtrGnrtr4InvrtrUnswthdSLIVltg 11925;
BA_ "SPN" SG_ 2565994238 MtrGnrtr4InvrtrStts2CRC 11992;
BA_ "SPN" SG_ 2565994238 MtrGnrtr4InvrtrStts2Cntr 11993;
BA_ "SPN" SG_ 2565994238 MtrGnrtr4AvllMxmmTrq 11994;
BA_ "SPN" SG_ 2565994238 MtrGnrtr4AvllMnmmTrq 11995;
BA_ "SPN" SG_ 2565994494 MtrGnrtr4InvrtrRtLmtsAtv1CRC 12026;
BA_ "SPN" SG_ 2565994494 MtrGnrtr4InvrtrRtLmtsAtv1Cntr 12027;
BA_ "SPN" SG_ 2565994494 MtGt4IvtRtLtsAtvAstSpdRtLt 12028;
BA_ "SPN" SG_ 2565994494 MtGt4IvtRtLtsAtvAstTqRtLt 12029;
BA_ "SPN" SG_ 2364668158 MtrGnrtr5InvrtrMdFdk1CRC 12051;
BA_ "SPN" SG_ 2364668158 MtrGnrtr5InvrtrMdFdk1Cntr 12052;
BA_ "SPN" SG_ 2364668158 MtrGnrtr5InvrtrCntrlLmtsOvrrdMd 12053;
BA_ "SPN" SG_ 2364668158 MtrGnrtr5InvrtrCntrlStpntMd 12054;
BA_ "SPN" SG_ 2364668158 MtrGnrtr5InvrtrHVILStts 12041;
BA_ "SPN" SG_ 2565995006 MtrGnrtr5InvrtrLmtsAtvPwrCRC 12069;
BA_ "SPN" SG_ 2565995006 MtrGnrtr5InvrtrLmtsAtvPwrCntr 12070;
BA_ "SPN" SG_ 2565995006 MtGt5IvtLtsAtvMPwMx 12071;
BA_ "SPN" SG_ 2565995006 MtGt5IvtLtsAtvMPwM 12072;
BA_ "SPN" SG_ 2565995006 MtGt5IvtLtsAtvDCSdPwMx 12073;
BA_ "SPN" SG_ 2565995006 MtGt5IvtLtsAtvDCSdPwM 12074;
BA_ "SPN" SG_ 2565995262 MtrGnrtr5InvrtrLmtsAtvMhnlCRC 12081;
BA_ "SPN" SG_ 2565995262 MtrGnrtr5InvrtrLmtsAtvMhnlCntr 12082;
BA_ "SPN" SG_ 2565995262 MtrGnrtr5InvrtrLmtsAtvTrqMxmm 12083;
BA_ "SPN" SG_ 2565995262 MtrGnrtr5InvrtrLmtsAtvTrqMnmm 12084;
BA_ "SPN" SG_ 2565995262 MtrGnrtr5InvrtrLmtsAtvSpdMxmm 12085;
BA_ "SPN" SG_ 2565995262 MtrGnrtr5InvrtrLmtsAtvSpdMnmm 12086;
BA_ "SPN" SG_ 2565995518 MtrGnrtr5InvrtrLmtsAtvDCSdCRC 12097;
BA_ "SPN" SG_ 2565995518 MtrGnrtr5InvrtrLmtsAtvDCSdCntr 12098;
BA_ "SPN" SG_ 2565995518 MtGt5IvtLtsAtvDCSdVtMx 12099;
BA_ "SPN" SG_ 2565995518 MtGt5IvtLtsAtvDCSdVtM 12100;
BA_ "SPN" SG_ 2565995518 MtGt5IvtLtsAtvDCSdCtMx 12101;
BA_ "SPN" SG_ 2565995518 MtGt5IvtLtsAtvDCSdCtM 12102;
BA_ "SPN" SG_ 2565995774 MtrGnrtr5InvrtrSwthdIgntnVltg 12042;
BA_ "SPN" SG_ 2565995774 MtrGnrtr5InvrtrUnswthdSLIVltg 12043;
BA_ "SPN" SG_ 2565996030 MtrGnrtr5InvrtrStts2CRC 12110;
BA_ "SPN" SG_ 2565996030 MtrGnrtr5InvrtrStts2Cntr 12111;
BA_ "SPN" SG_ 2565996030 MtrGnrtr5AvllMxmmTrq 12112;
BA_ "SPN" SG_ 2565996030 MtrGnrtr5AvllMnmmTrq 12113;
BA_ "SPN" SG_ 2565996286 MtrGnrtr5InvrtrRtLmtsAtv1CRC 12144;
BA_ "SPN" SG_ 2565996286 MtrGnrtr5InvrtrRtLmtsAtv1Cntr 12145;
BA_ "SPN" SG_ 2565996286 MtGt5IvtRtLtsAtvAstSpdRtLt 12146;
BA_ "SPN" SG_ 2565996286 MtGt5IvtRtLtsAtvAstTqRtLt 12147;
BA_ "SPN" SG_ 2364669950 MtrGnrtr6InvrtrMdFdk1CRC 12169;
BA_ "SPN" SG_ 2364669950 MtrGnrtr6InvrtrMdFdk1Cntr 12170;
BA_ "SPN" SG_ 2364669950 MtrGnrtr6InvrtrCntrlLmtsOvrrdMd 12171;
BA_ "SPN" SG_ 2364669950 MtrGnrtr6InvrtrCntrlStpntMd 12172;
BA_ "SPN" SG_ 2364669950 MtrGnrtr6InvrtrHVILStts 12159;
BA_ "SPN" SG_ 2565996798 MtrGnrtr6InvrtrLmtsAtvPwrCRC 12187;
BA_ "SPN" SG_ 2565996798 MtrGnrtr6InvrtrLmtsAtvPwrCntr 12188;
BA_ "SPN" SG_ 2565996798 MtGt6IvtLtsAtvMPwMx 12189;
BA_ "SPN" SG_ 2565996798 MtGt6IvtLtsAtvMPwM 12190;
BA_ "SPN" SG_ 2565996798 MtGt6IvtLtsAtvDCSdPwMx 12191;
BA_ "SPN" SG_ 2565996798 MtGt6IvtLtsAtvDCSdPwM 12192;
BA_ "SPN" SG_ 2565997054 MtrGnrtr6InvrtrLmtsAtvMhnlCRC 12199;
BA_ "SPN" SG_ 2565997054 MtrGnrtr6InvrtrLmtsAtvMhnlCntr 12200;
BA_ "SPN" SG_ 2565997054 MtrGnrtr6InvrtrLmtsAtvTrqMxmm 12201;
BA_ "SPN" SG_ 2565997054 MtrGnrtr6InvrtrLmtsAtvTrqMnmm 12202;
BA_ "SPN" SG_ 2565997054 MtrGnrtr6InvrtrLmtsAtvSpdMxmm 12203;
BA_ "SPN" SG_ 2565997054 MtrGnrtr6InvrtrLmtsAtvSpdMnmm 12204;
BA_ "SPN" SG_ 2565997310 MtrGnrtr6InvrtrLmtsAtvDCSdCRC 12215;
BA_ "SPN" SG_ 2565997310 MtrGnrtr6InvrtrLmtsAtvDCSdCntr 12216;
BA_ "SPN" SG_ 2565997310 MtGt6IvtLtsAtvDCSdVtMx 12217;
BA_ "SPN" SG_ 2565997310 MtGt6IvtLtsAtvDCSdVtM 12218;
BA_ "SPN" SG_ 2565997310 MtGt6IvtLtsAtvDCSdCtMx 12219;
BA_ "SPN" SG_ 2565997310 MtGt6IvtLtsAtvDCSdCtM 12220;
BA_ "SPN" SG_ 2565997566 MtrGnrtr6InvrtrSwthdIgntnVltg 12160;
BA_ "SPN" SG_ 2565997566 MtrGnrtr6InvrtrUnswthdSLIVltg 12161;
BA_ "SPN" SG_ 2565997822 MtrGnrtr6InvrtrStts2CRC 12228;
BA_ "SPN" SG_ 2565997822 MtrGnrtr6InvrtrStts2Cntr 12229;
BA_ "SPN" SG_ 2565997822 MtrGnrtr6AvllMxmmTrq 12230;
BA_ "SPN" SG_ 2565997822 MtrGnrtr6AvllMnmmTrq 12231;
BA_ "SPN" SG_ 2565998078 MtrGnrtr6InvrtrRtLmtsAtv1CRC 12262;
BA_ "SPN" SG_ 2565998078 MtrGnrtr6InvrtrRtLmtsAtv1Cntr 12263;
BA_ "SPN" SG_ 2565998078 MtGt6IvtRtLtsAtvAstSpdRtLt 12264;
BA_ "SPN" SG_ 2565998078 MtGt6IvtRtLtsAtvAstTqRtLt 12265;
BA_ "SPN" SG_ 2364671742 BlindSpotDetectionState 12286;
BA_ "SPN" SG_ 2364671742 BlindSpotCollisionWarningLevel 12287;
BA_ "SPN" SG_ 2364671742 BlndSptWrnngRlvntOjtDttd 12288;
BA_ "SPN" SG_ 2364671742 BndOffPrltfMstImprtntOjt 12289;
BA_ "SPN" SG_ 2364671742 BlndSptDttnLftSdMntrd 12290;
BA_ "SPN" SG_ 2364671742 BlndSptDttnRghtSdMntrd 12291;
BA_ "SPN" SG_ 2364671742 BlndSptDttnFrntMntrd 12292;
BA_ "SPN" SG_ 2364671742 BlindSpotDetectionRearMonitored 12293;
BA_ "SPN" SG_ 2364671998 WinchMotorEncoderPosition 12309;
BA_ "SPN" SG_ 2364671998 WinchRevolutionCounter 12310;
BA_ "SPN" SG_ 2364672254 MtrGnrtr3InvrtrCntrlCRC 11808;
BA_ "SPN" SG_ 2364672254 MtrGnrtr3InvrtrCntrlCntr 11809;
BA_ "SPN" SG_ 2364672254 MtGt3IvtCtLtsRqstOvdMd 11810;
BA_ "SPN" SG_ 2364672254 MtGt3IvtCtLtsRqstOvdMx 11811;
BA_ "SPN" SG_ 2364672254 MtGt3IvtCtLtsRqstOvdM 11812;
BA_ "SPN" SG_ 2364672254 MtrGnrtr3InvrtrCntrlStpntMdRqst 11813;
BA_ "SPN" SG_ 2364672254 MtrGnrtr3InvrtrCntrlStpntRqst 11814;
BA_ "SPN" SG_ 2565999102 MtrGnrtr3InvrtrRtLmtsRqst1CRC 11904;
BA_ "SPN" SG_ 2565999102 MtrGnrtr3InvrtrRtLmtsRqst1Cntr 11905;
BA_ "SPN" SG_ 2565999102 MtGt3IvtRtLtsRqstAstSpdRtLt 11906;
BA_ "SPN" SG_ 2565999102 MtGt3IvtRtLtsRqstAstTqRtLt 11907;
BA_ "SPN" SG_ 2364672766 MtrGnrtr4InvrtrCntrlCRC 11926;
BA_ "SPN" SG_ 2364672766 MtrGnrtr4InvrtrCntrlCntr 11927;
BA_ "SPN" SG_ 2364672766 MtGt4IvtCtLtsRqstOvdMd 11928;
BA_ "SPN" SG_ 2364672766 MtGt4IvtCtLtsRqstOvdMx 11929;
BA_ "SPN" SG_ 2364672766 MtGt4IvtCtLtsRqstOvdM 11930;
BA_ "SPN" SG_ 2364672766 MtrGnrtr4InvrtrCntrlStpntMdRqst 11931;
BA_ "SPN" SG_ 2364672766 MtrGnrtr4InvrtrCntrlStpntRqst 11932;
BA_ "SPN" SG_ 2565999614 MtrGnrtr4InvrtrRtLmtsRqst1CRC 12022;
BA_ "SPN" SG_ 2565999614 MtrGnrtr4InvrtrRtLmtsRqst1Cntr 12023;
BA_ "SPN" SG_ 2565999614 MtGt4IvtRtLtsRqstAstSpdRtLt 12024;
BA_ "SPN" SG_ 2565999614 MtGt4IvtRtLtsRqstAstTqRtLt 12025;
BA_ "SPN" SG_ 2364673278 MtrGnrtr5InvrtrCntrlCRC 12044;
BA_ "SPN" SG_ 2364673278 MtrGnrtr5InvrtrCntrlCntr 12045;
BA_ "SPN" SG_ 2364673278 MtGt5IvtCtLtsRqstOvdMd 12046;
BA_ "SPN" SG_ 2364673278 MtGt5IvtCtLtsRqstOvdMx 12047;
BA_ "SPN" SG_ 2364673278 MtGt5IvtCtLtsRqstOvdM 12048;
BA_ "SPN" SG_ 2364673278 MtrGnrtr5InvrtrCntrlStpntMdRqst 12049;
BA_ "SPN" SG_ 2364673278 MtrGnrtr5InvrtrCntrlStpntRqst 12050;
BA_ "SPN" SG_ 2566000126 MtrGnrtr5InvrtrRtLmtsRqst1CRC 12140;
BA_ "SPN" SG_ 2566000126 MtrGnrtr5InvrtrRtLmtsRqst1Cntr 12141;
BA_ "SPN" SG_ 2566000126 MtGt5IvtRtLtsRqstAstSpdRtLt 12142;
BA_ "SPN" SG_ 2566000126 MtGt5IvtRtLtsRqstAstTqRtLt 12143;
BA_ "SPN" SG_ 2364673790 MtrGnrtr6InvrtrCntrlCRC 12162;
BA_ "SPN" SG_ 2364673790 MtrGnrtr6InvrtrCntrlCntr 12163;
BA_ "SPN" SG_ 2364673790 MtGt6IvtCtLtsRqstOvdMd 12164;
BA_ "SPN" SG_ 2364673790 MtGt6IvtCtLtsRqstOvdMx 12165;
BA_ "SPN" SG_ 2364673790 MtGt6IvtCtLtsRqstOvdM 12166;
BA_ "SPN" SG_ 2364673790 MtrGnrtr6InvrtrCntrlStpntMdRqst 12167;
BA_ "SPN" SG_ 2364673790 MtrGnrtr6InvrtrCntrlStpntRqst 12168;
BA_ "SPN" SG_ 2566000638 MtrGnrtr6InvrtrRtLmtsRqst1CRC 12258;
BA_ "SPN" SG_ 2566000638 MtrGnrtr6InvrtrRtLmtsRqst1Cntr 12259;
BA_ "SPN" SG_ 2566000638 MtGt6IvtRtLtsRqstAstSpdRtLt 12260;
BA_ "SPN" SG_ 2566000638 MtGt6IvtRtLtsRqstAstTqRtLt 12261;
BA_ "SPN" SG_ 2566574078 EVCC1ControlPilotmaximumvoltage 12927;
BA_ "SPN" SG_ 2566574078 EVCC1ControlPilotminimumvoltage 12928;
BA_ "SPN" SG_ 2566574078 EVCC1ControlPilotPWMfrequency 12929;
BA_ "SPN" SG_ 2566574078 EVCC1ControlPilotDutyCycle 12930;
BA_ "SPN" SG_ 2566574078 EVCC1ControlPilotState 12931;
BA_ "SPN" SG_ 2566574078 EVCC1ControlPilotSubState 12932;
BA_ "SPN" SG_ 2566574078 EVCC1Proximitycircuitvoltage 12933;
BA_ "SPN" SG_ 2566574078 EVCC1Inletconnectortemperature 12934;
BA_ "SPN" SG_ 2566574078 EVCC1CompatibilityCode 12935;
BA_ "SPN" SG_ 2499465470 Mirror1LeftRightSelection 12923;
BA_ "SPN" SG_ 2499465470 Mirror2LeftRightSelection 12924;
BA_ "SPN" SG_ 2499465470 MirrorPrimarySecondarySelection 12925;
BA_ "SPN" SG_ 2499465726 EngnClndrTmprtrAvrg 12894;
BA_ "SPN" SG_ 2499465726 EngnClndrBnk1TmprtrAvrg 12895;
BA_ "SPN" SG_ 2499465726 EngnClndrBnk2TmprtrAvrg 12896;
